VERSION "HNPBNNNYNNNNNNNNNNNNNNNNNNNNNNNNYNYYYYYYYY>4>%%%/4>'%**4YYY///"

NS_ :

BS_:

BU_: TPM TCM SCCM RF_HUB PTS ORC IC HaLF ETM ESM ESC EPS ECM Diagnost DTCM DASM CBC AFLS ADCM

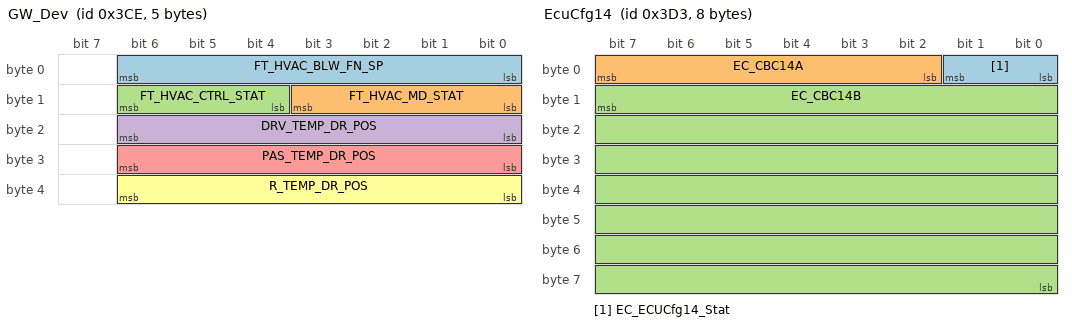
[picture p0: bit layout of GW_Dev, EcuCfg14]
BO_ 974 GW_Dev: 5 CBC
 SG_ FT_HVAC_BLW_FN_SP : 0|7@1+ (1,0) [0|100] "Bars"  ECM
 SG_ FT_HVAC_MD_STAT : 8|4@1+ (1,0) [0|0] ""  ECM
 SG_ FT_HVAC_CTRL_STAT : 12|3@1+ (1,0) [0|0] ""  ECM
 SG_ DRV_TEMP_DR_POS : 16|7@1+ (1,0) [0|100] "%"  ECM
 SG_ PAS_TEMP_DR_POS : 24|7@1+ (1,0) [0|100] "%"  ECM
 SG_ R_TEMP_DR_POS : 32|7@1+ (1,0) [0|100] "%"  ECM

BO_ 975 IC_SRT: 8 IC
 SG_ SRT_CTRL3 M : 0|4@1+ (1,0) [0|0] ""  CBC
 SG_ SRT_60mphTmC m0 : 8|8@1+ (0.1,0) [0|25.2] "sec"  CBC
 SG_ SRT_60mphTmB m1 : 8|8@1+ (0.1,0) [0|25.2] "sec"  CBC
 SG_ SRT_100mphTmL m10 : 8|8@1+ (0.1,0) [0|25.2] "sec"  CBC
 SG_ SRT_100mphTm_C m11 : 8|8@1+ (0.1,0) [0|25.2] "sec"  CBC
 SG_ SRT_100mphTm_B m12 : 8|8@1+ (0.1,0) [0|25.2] "sec"  CBC
 SG_ SRT_100mphTm_L m13 : 8|8@1+ (0.1,0) [0|25.2] "sec"  CBC
 SG_ SRT_60mphTmL m2 : 8|8@1+ (0.1,0) [0|25.2] "sec"  CBC
 SG_ SRT_60mphTm_C m3 : 8|8@1+ (0.1,0) [0|25.2] "sec"  CBC
 SG_ SRT_60mphTm_B m4 : 8|8@1+ (0.1,0) [0|25.2] "sec"  CBC
 SG_ SRT_60mphTm_L m5 : 8|8@1+ (0.1,0) [0|25.2] "sec"  CBC
 SG_ SRT_100mphTmC m8 : 8|8@1+ (0.1,0) [0|25.2] "sec"  CBC
 SG_ SRT_100mphTmB m9 : 8|8@1+ (0.1,0) [0|25.2] "sec"  CBC
 SG_ SRT_eighthTmC m0 : 16|8@1+ (0.1,0) [0|25.2] "sec"  CBC
 SG_ SRT_eighthTmB m1 : 16|8@1+ (0.1,0) [0|25.2] "sec"  CBC
 SG_ SRT_BrkTmL m10 : 16|8@1+ (0.1,0) [0|25.2] "sec"  CBC
 SG_ SRT_BrkTm_C m11 : 16|8@1+ (0.1,0) [0|25.2] "sec"  CBC
 SG_ SRT_BrkTm_B m12 : 16|8@1+ (0.1,0) [0|25.2] "sec"  CBC
 SG_ SRT_BrkTm_L m13 : 16|8@1+ (0.1,0) [0|25.2] "sec"  CBC
 SG_ SRT_eighthTmL m2 : 16|8@1+ (0.1,0) [0|25.2] "sec"  CBC
 SG_ SRT_eighthTm_C m3 : 16|8@1+ (0.1,0) [0|25.2] "sec"  CBC
 SG_ SRT_eighthTm_B m4 : 16|8@1+ (0.1,0) [0|25.2] "sec"  CBC
 SG_ SRT_eighthTm_L m5 : 16|8@1+ (0.1,0) [0|25.2] "sec"  CBC
 SG_ SRT_BrkTmC m8 : 16|8@1+ (0.1,0) [0|25.2] "sec"  CBC
 SG_ SRT_BrkTmB m9 : 16|8@1+ (0.1,0) [0|25.2] "sec"  CBC
 SG_ SRT_quarterTmC m0 : 24|8@1+ (0.1,0) [0|25.2] "sec"  CBC
 SG_ SRT_quarterTmB m1 : 24|8@1+ (0.1,0) [0|25.2] "sec"  CBC
 SG_ SRT_ReactTmL m10 : 24|8@1+ (0.01,-1.26) [-1.26|1.26] "sec"  CBC
 SG_ SRT_quarterTmL m2 : 24|8@1+ (0.1,0) [0|25.2] "sec"  CBC
 SG_ SRT_quarterTm_C m3 : 24|8@1+ (0.1,0) [0|25.2] "sec"  CBC
 SG_ SRT_quarterTm_B m4 : 24|8@1+ (0.1,0) [0|25.2] "sec"  CBC
 SG_ SRT_quarterTm_L m5 : 24|8@1+ (0.1,0) [0|25.2] "sec"  CBC
 SG_ SRT_ReactTmC m8 : 24|8@1+ (0.01,-1.26) [-1.26|1.26] "sec"  CBC
 SG_ SRT_ReactTmB m9 : 24|8@1+ (0.01,-1.26) [-1.26|1.26] "sec"  CBC
 SG_ SRT_EthSpdC_M m0 : 32|8@1+ (1,0) [0|254] "km/h"  CBC
 SG_ SRT_EthSpdB_M m1 : 32|8@1+ (1,0) [0|254] "km/h"  CBC
 SG_ SRT_EthSpdL_M m2 : 32|8@1+ (1,0) [0|254] "km/h"  CBC
 SG_ SRT_EthSpdC_US m3 : 32|8@1+ (1,0) [0|254] "mph"  CBC
 SG_ SRT_EthSpdB_US m4 : 32|8@1+ (1,0) [0|254] "mph"  CBC
 SG_ SRT_EthSpdL_US m5 : 32|8@1+ (1,0) [0|254] "mph"  CBC
 SG_ SRT_QrtSpdC_M m0 : 40|8@1+ (1,0) [0|254] "km/h"  CBC
 SG_ SRT_QrtSpdB_M m1 : 40|8@1+ (1,0) [0|254] "km/h"  CBC
 SG_ SRT_QrtSpdL_M m2 : 40|8@1+ (1,0) [0|254] "km/h"  CBC
 SG_ SRT_QrtSpdC_US m3 : 40|8@1+ (1,0) [0|254] "mph"  CBC
 SG_ SRT_QrtSpdB_US m4 : 40|8@1+ (1,0) [0|254] "mph"  CBC
 SG_ SRT_QrtSpdL_US m5 : 40|8@1+ (1,0) [0|254] "mph"  CBC
 SG_ SRT_BrkSpdC_M m0 : 48|8@1+ (1,0) [0|254] "km/h"  CBC
 SG_ SRT_BrkSpdB_M m1 : 48|8@1+ (1,0) [0|254] "km/h"  CBC
 SG_ SRT_BrkSpdL_M m2 : 48|8@1+ (1,0) [0|254] "km/h"  CBC
 SG_ SRT_BrkSpdC_US m3 : 48|8@1+ (1,0) [0|254] "mph"  CBC
 SG_ SRT_BrkSpdB_US m4 : 48|8@1+ (1,0) [0|254] "mph"  CBC
 SG_ SRT_BrkSpdL_US m5 : 48|8@1+ (1,0) [0|254] "mph"  CBC
 SG_ SRT_BrkDistC_M m0 : 56|8@1+ (1,0) [0|252] "m"  CBC
 SG_ SRT_BrkDistB_M m1 : 56|8@1+ (1,0) [0|252] "m"  CBC
 SG_ SRT_BrkDistL_M m2 : 56|8@1+ (1,0) [0|252] "m"  CBC
 SG_ SRT_BrkDistC_US m3 : 56|8@1+ (1,0) [0|252] "Yards"  CBC
 SG_ SRT_BrkDistB_US m4 : 56|8@1+ (1,0) [0|252] "Yards"  CBC
 SG_ SRT_BrkDistL_US m5 : 56|8@1+ (1,0) [0|252] "Yards"  CBC

BO_ 977 TCM_CFG: 4 TCM
 SG_ TransTyp : 0|8@1+ (1,0) [0|0] ""  DTCM,ESC,CBC,RF_HUB

BO_ 979 EcuCfg14: 8 CBC
 SG_ EC_ECUCfg14_Stat : 0|2@1+ (1,0) [0|0] ""  RF_HUB
 SG_ EC_CBC14A : 2|6@1+ (1,0) [0|0] ""  RF_HUB
 SG_ EC_CBC14B : 15|56@0+ (1,0) [0|0] ""  RF_HUB

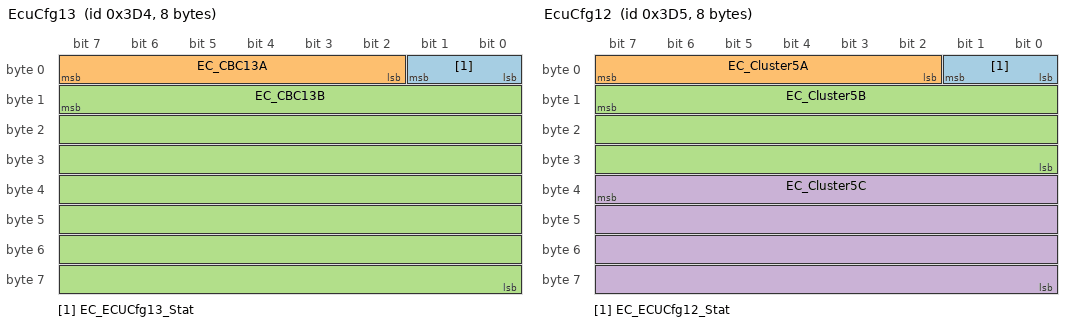
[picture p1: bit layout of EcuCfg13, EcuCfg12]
BO_ 980 EcuCfg13: 8 CBC
 SG_ EC_ECUCfg13_Stat : 0|2@1+ (1,0) [0|0] ""  RF_HUB
 SG_ EC_CBC13A : 2|6@1+ (1,0) [0|0] ""  RF_HUB
 SG_ EC_CBC13B : 15|56@0+ (1,0) [0|0] ""  RF_HUB

BO_ 981 EcuCfg12: 8 CBC
 SG_ EC_ECUCfg12_Stat : 0|2@1+ (1,0) [0|0] ""  IC,RF_HUB
 SG_ EC_Cluster5A : 2|6@1+ (1,0) [0|0] ""  IC,RF_HUB
 SG_ EC_Cluster5B : 15|24@0+ (1,0) [0|0] ""  IC,RF_HUB
 SG_ EC_Cluster5C : 39|32@0+ (1,0) [0|0] ""  IC,RF_HUB

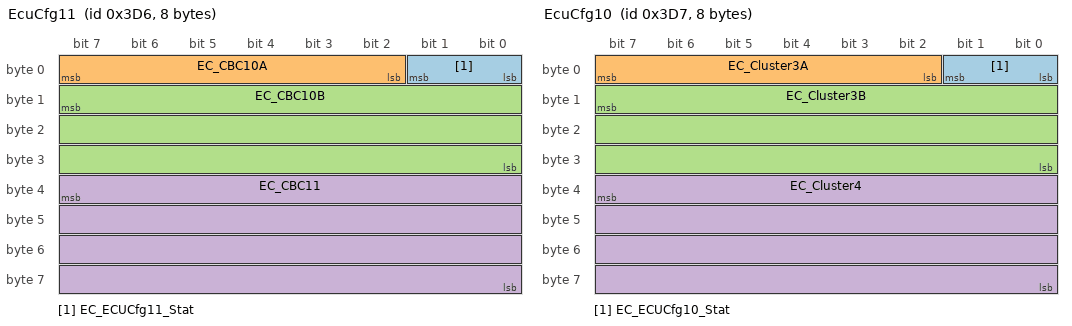
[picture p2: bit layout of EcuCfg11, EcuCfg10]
BO_ 982 EcuCfg11: 8 CBC
 SG_ EC_ECUCfg11_Stat : 0|2@1+ (1,0) [0|0] ""  RF_HUB
 SG_ EC_CBC10A : 2|6@1+ (1,0) [0|0] ""  RF_HUB
 SG_ EC_CBC10B : 15|24@0+ (1,0) [0|0] ""  RF_HUB
 SG_ EC_CBC11 : 39|32@0+ (1,0) [0|0] ""  RF_HUB

BO_ 983 EcuCfg10: 8 CBC
 SG_ EC_ECUCfg10_Stat : 0|2@1+ (1,0) [0|0] ""  IC,RF_HUB
 SG_ EC_Cluster3A : 2|6@1+ (1,0) [0|0] ""  IC,RF_HUB
 SG_ EC_Cluster3B : 15|24@0+ (1,0) [0|0] ""  IC,RF_HUB
 SG_ EC_Cluster4 : 39|32@0+ (1,0) [0|0] ""  IC,RF_HUB

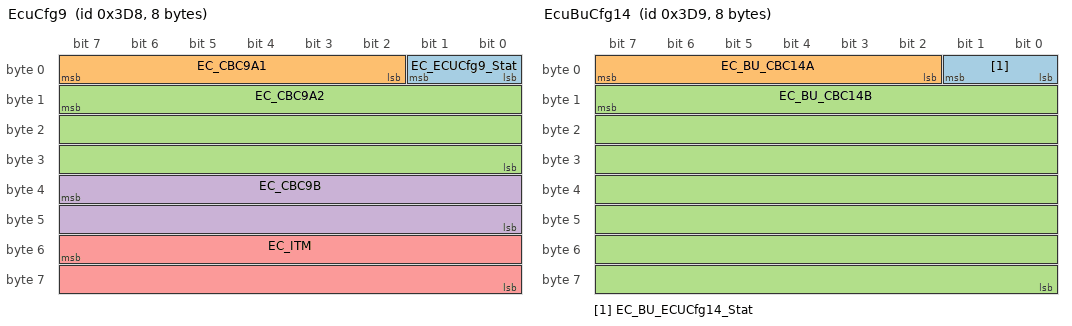
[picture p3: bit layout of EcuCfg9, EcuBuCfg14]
BO_ 984 EcuCfg9: 8 CBC
 SG_ EC_ECUCfg9_Stat : 0|2@1+ (1,0) [0|0] ""  RF_HUB
 SG_ EC_CBC9A1 : 2|6@1+ (1,0) [0|0] ""  RF_HUB
 SG_ EC_CBC9A2 : 15|24@0+ (1,0) [0|0] ""  RF_HUB
 SG_ EC_CBC9B : 39|16@0+ (1,0) [0|0] ""  RF_HUB
 SG_ EC_ITM : 55|16@0+ (1,0) [0|0] ""  RF_HUB

BO_ 985 EcuBuCfg14: 8 RF_HUB
 SG_ EC_BU_ECUCfg14_Stat : 0|2@1+ (1,0) [0|0] ""  CBC
 SG_ EC_BU_CBC14A : 2|6@1+ (1,0) [0|0] ""  CBC
 SG_ EC_BU_CBC14B : 15|56@0+ (1,0) [0|0] ""  CBC

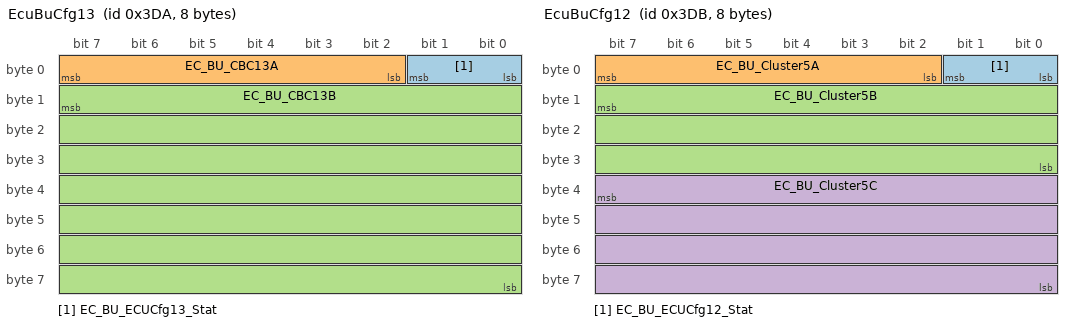
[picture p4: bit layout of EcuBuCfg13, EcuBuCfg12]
BO_ 986 EcuBuCfg13: 8 RF_HUB
 SG_ EC_BU_ECUCfg13_Stat : 0|2@1+ (1,0) [0|0] ""  CBC
 SG_ EC_BU_CBC13A : 2|6@1+ (1,0) [0|0] ""  CBC
 SG_ EC_BU_CBC13B : 15|56@0+ (1,0) [0|0] ""  CBC

BO_ 987 EcuBuCfg12: 8 RF_HUB
 SG_ EC_BU_ECUCfg12_Stat : 0|2@1+ (1,0) [0|0] ""  CBC
 SG_ EC_BU_Cluster5A : 2|6@1+ (1,0) [0|0] ""  CBC
 SG_ EC_BU_Cluster5B : 15|24@0+ (1,0) [0|0] ""  CBC
 SG_ EC_BU_Cluster5C : 39|32@0+ (1,0) [0|0] ""  CBC

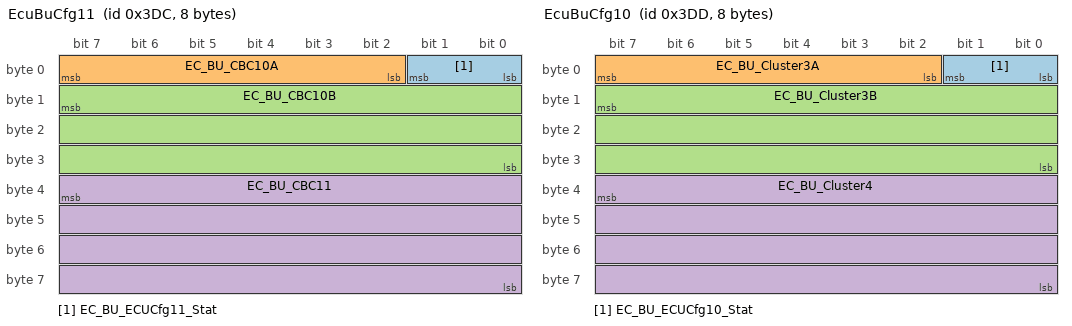
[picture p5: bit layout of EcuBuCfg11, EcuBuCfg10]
BO_ 988 EcuBuCfg11: 8 RF_HUB
 SG_ EC_BU_ECUCfg11_Stat : 0|2@1+ (1,0) [0|0] ""  CBC
 SG_ EC_BU_CBC10A : 2|6@1+ (1,0) [0|0] ""  CBC
 SG_ EC_BU_CBC10B : 15|24@0+ (1,0) [0|0] ""  CBC
 SG_ EC_BU_CBC11 : 39|32@0+ (1,0) [0|0] ""  CBC

BO_ 989 EcuBuCfg10: 8 RF_HUB
 SG_ EC_BU_ECUCfg10_Stat : 0|2@1+ (1,0) [0|0] ""  CBC
 SG_ EC_BU_Cluster3A : 2|6@1+ (1,0) [0|0] ""  CBC
 SG_ EC_BU_Cluster3B : 15|24@0+ (1,0) [0|0] ""  CBC
 SG_ EC_BU_Cluster4 : 39|32@0+ (1,0) [0|0] ""  CBC

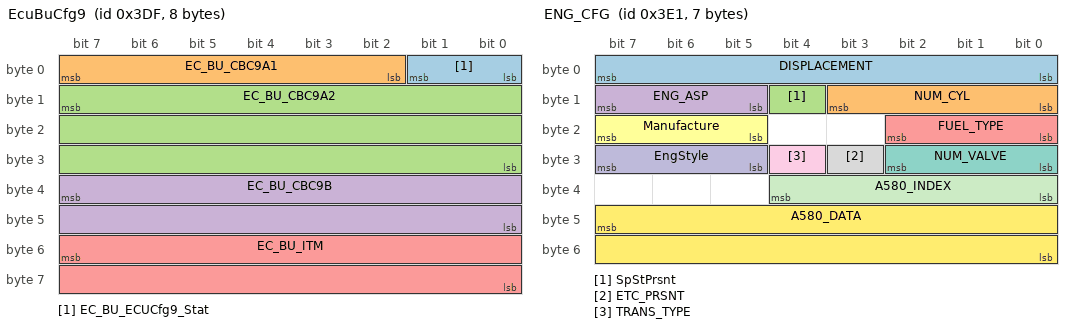
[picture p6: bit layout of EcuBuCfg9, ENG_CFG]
BO_ 991 EcuBuCfg9: 8 RF_HUB
 SG_ EC_BU_ECUCfg9_Stat : 0|2@1+ (1,0) [0|0] ""  CBC
 SG_ EC_BU_CBC9A1 : 2|6@1+ (1,0) [0|0] ""  CBC
 SG_ EC_BU_CBC9A2 : 15|24@0+ (1,0) [0|0] ""  CBC
 SG_ EC_BU_CBC9B : 39|16@0+ (1,0) [0|0] ""  CBC
 SG_ EC_BU_ITM : 55|16@0+ (1,0) [0|0] ""  CBC

BO_ 992 VIN: 8 ECM
 SG_ VIN_MSG : 0|2@1+ (1,0) [0|0] ""  HaLF,ORC,ADCM,DTCM,ESM,TCM,ECM,DASM,ESC,SCCM,EPS,AFLS,TPM,PTS,IC,CBC,RF_HUB
 SG_ VIN_DATA : 15|56@0+ (1,0) [0|0] ""  HaLF,ORC,ADCM,DTCM,ESM,TCM,ECM,DASM,ESC,SCCM,EPS,AFLS,TPM,PTS,IC,CBC,RF_HUB

BO_ 993 ENG_CFG: 7 ECM
 SG_ DISPLACEMENT : 0|8@1+ (0.1,0) [0|25] "liters"  ETM,DASM,ESC,EPS,IC,CBC
 SG_ NUM_CYL : 8|4@1+ (1,0) [0|14] "cylinders"  DASM,ESC
 SG_ SpStPrsnt : 12|1@1+ (1,0) [0|0] ""  EPS,IC,CBC
 SG_ ENG_ASP : 13|3@1+ (1,0) [0|0] ""  ETM,DASM,ESC
 SG_ FUEL_TYPE : 16|3@1+ (1,0) [0|0] ""  ORC,DASM,ESC,IC,CBC
 SG_ Manufacture : 21|3@1+ (1,0) [0|0] "" Vector__XXX
 SG_ NUM_VALVE : 24|3@1+ (1,0) [0|6] "valve-per-cylinder"  DASM
 SG_ ETC_PRSNT : 27|1@1+ (1,0) [0|0] ""  IC
 SG_ TRANS_TYPE : 28|1@1+ (1,0) [0|0] ""  EPS,ORC,DTCM,DASM,ESC,TPM,PTS,IC,CBC,RF_HUB
 SG_ EngStyle : 29|3@1+ (1,0) [0|0] ""  ESC,CBC
 SG_ A580_INDEX : 32|5@1+ (1,0) [0|0] "" Vector__XXX
 SG_ A580_DATA : 47|16@0+ (1,0) [0|0] "" Vector__XXX

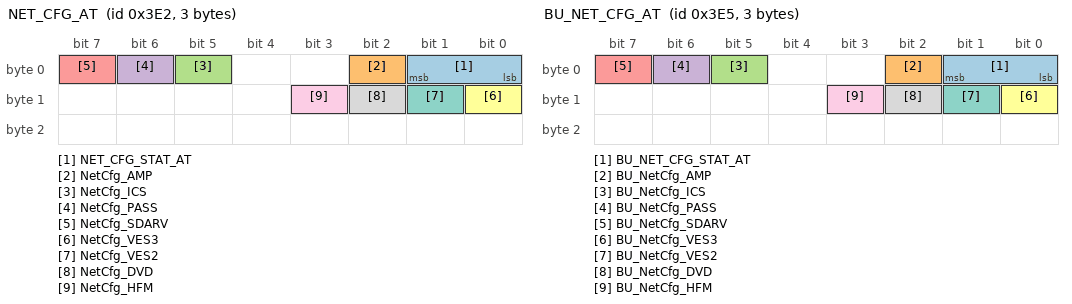
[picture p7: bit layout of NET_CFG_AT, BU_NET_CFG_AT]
BO_ 994 NET_CFG_AT: 3 CBC
 SG_ NET_CFG_STAT_AT : 0|2@1+ (1,0) [0|0] ""  RF_HUB
 SG_ NetCfg_AMP : 2|1@1+ (1,0) [0|0] ""  RF_HUB
 SG_ NetCfg_ICS : 5|1@1+ (1,0) [0|0] ""  RF_HUB
 SG_ NetCfg_PASS : 6|1@1+ (1,0) [0|0] ""  RF_HUB
 SG_ NetCfg_SDARV : 7|1@1+ (1,0) [0|0] ""  RF_HUB
 SG_ NetCfg_VES3 : 8|1@1+ (1,0) [0|0] ""  RF_HUB
 SG_ NetCfg_VES2 : 9|1@1+ (1,0) [0|0] ""  RF_HUB
 SG_ NetCfg_DVD : 10|1@1+ (1,0) [0|0] ""  RF_HUB
 SG_ NetCfg_HFM : 11|1@1+ (1,0) [0|0] ""  RF_HUB

BO_ 995 NET_CFG_INT: 8 CBC
 SG_ NET_CFG_STAT_INT : 0|2@1+ (1,0) [0|0] ""  IC,RF_HUB
 SG_ NetCfg_RBSS : 2|1@1+ (1,0) [0|0] ""  RF_HUB
 SG_ NetCfg_BSM : 3|1@1+ (1,0) [0|0] ""  IC,RF_HUB
 SG_ NetCfg_CBC_IN : 4|1@1+ (1,0) [0|0] ""  IC,RF_HUB
 SG_ NetCfg_CSWM : 5|1@1+ (1,0) [0|0] ""  IC,RF_HUB
 SG_ NetCfg_DCM_DR : 6|1@1+ (1,0) [0|0] ""  IC,RF_HUB
 SG_ NetCfg_DCM_PASS : 7|1@1+ (1,0) [0|0] ""  IC,RF_HUB
 SG_ NetCfg_DCM_RL : 8|1@1+ (1,0) [0|0] ""  IC,RF_HUB
 SG_ NetCfg_DCM_RR : 9|1@1+ (1,0) [0|0] ""  IC,RF_HUB
 SG_ NetCfg_HVAC : 10|1@1+ (1,0) [0|0] ""  IC,RF_HUB
 SG_ NetCfg_MSM : 11|1@1+ (1,0) [0|0] ""  IC,RF_HUB
 SG_ NetCfg_PLG : 12|1@1+ (1,0) [0|0] ""  IC,RF_HUB
 SG_ NetCfg_VTM : 13|1@1+ (1,0) [0|0] ""  RF_HUB
 SG_ NetCfg_PSD_LT : 14|1@1+ (1,0) [0|0] ""  IC,RF_HUB
 SG_ NetCfg_PSD_RT : 15|1@1+ (1,0) [0|0] ""  IC,RF_HUB
 SG_ NetCfg_FSM : 16|1@1+ (1,0) [0|0] ""  IC,RF_HUB
 SG_ NetCfg_PTCM : 17|1@1+ (1,0) [0|0] ""  IC,RF_HUB
 SG_ NetCfg_RBC : 18|1@1+ (1,0) [0|0] ""  IC,RF_HUB
 SG_ NetCfg_DTV : 19|1@1+ (1,0) [0|0] ""  RF_HUB
 SG_ NetCfg_TGW : 20|1@1+ (1,0) [0|0] ""  IC,RF_HUB
 SG_ NetCfg_CLOCK : 21|1@1+ (1,0) [0|0] ""  RF_HUB
 SG_ NetCfg_VSIM : 22|1@1+ (1,0) [0|0] ""  IC,RF_HUB
 SG_ NetCfg_ITM : 23|1@1+ (1,0) [0|0] ""  IC,RF_HUB
 SG_ NetCfg_AMP_I : 24|1@1+ (1,0) [0|0] ""  RF_HUB
 SG_ NetCfg_DVD_CDM : 25|1@1+ (1,0) [0|0] ""  RF_HUB
 SG_ NetCfg_HFM_CTM : 26|1@1+ (1,0) [0|0] ""  RF_HUB
 SG_ NetCfg_ICS_I : 27|1@1+ (1,0) [0|0] ""  RF_HUB
 SG_ NetCfg_VES2_I : 28|1@1+ (1,0) [0|0] ""  RF_HUB
 SG_ NetCfg_VES3_I : 29|1@1+ (1,0) [0|0] ""  RF_HUB
 SG_ NetCfg_CRSM : 30|1@1+ (1,0) [0|0] ""  RF_HUB
 SG_ NetCfg_HVAC_R : 31|1@1+ (1,0) [0|0] ""  RF_HUB

BO_ 996 NET_CFG_PT: 8 CBC
 SG_ NET_CFG_STAT_PT : 0|2@1+ (1,0) [0|0] ""  HaLF,ORC,ADCM,DTCM,ESM,TCM,ECM,DASM,ESC,SCCM,EPS,AFLS,TPM,PTS,IC,RF_HUB
 SG_ NetCfg_ACC : 2|1@1+ (1,0) [0|0] ""  IC,RF_HUB
 SG_ NetCfg_ADCM : 3|1@1+ (1,0) [0|0] ""  DASM,IC,RF_HUB
 SG_ NetCfg_AHLM : 4|1@1+ (1,0) [0|0] ""  IC,RF_HUB
 SG_ NetCfg_VSIM_C : 5|1@1+ (1,0) [0|0] ""  ECM,IC,RF_HUB
 SG_ NetCfg_ASCM : 6|1@1+ (1,0) [0|0] ""  HaLF,ESC,SCCM,AFLS,TPM,PTS,IC,RF_HUB
 SG_ NetCfg_CBC_PT : 7|1@1+ (1,0) [0|0] ""  ORC,TCM,ECM,DASM,ESC,SCCM,EPS,TPM,PTS,IC,RF_HUB
 SG_ NetCfg_DTCM : 8|1@1+ (1,0) [0|0] ""  TCM,ECM,DASM,ESC,IC,RF_HUB
 SG_ NetCfg_ECM : 9|1@1+ (1,0) [0|0] ""  ORC,TCM,ECM,DASM,ESC,SCCM,EPS,TPM,PTS,IC,RF_HUB
 SG_ NetCfg_EPS : 10|1@1+ (1,0) [0|0] ""  ECM,IC,RF_HUB
 SG_ NetCfg_ESM : 11|1@1+ (1,0) [0|0] ""  ECM,IC,RF_HUB
 SG_ NetCfg_ESC : 12|1@1+ (1,0) [0|0] ""  ORC,TCM,ECM,DASM,EPS,TPM,PTS,IC,RF_HUB
 SG_ NetCfg_EPB : 13|1@1+ (1,0) [0|0] ""  ECM,DASM,RF_HUB
 SG_ NetCfg_RF_HUB : 14|1@1+ (1,0) [0|0] ""  ECM,DASM,ESC,SCCM,TPM,IC,RF_HUB
 SG_ NetCfg_IC : 15|1@1+ (1,0) [0|0] ""  TCM,ECM,DASM,ESC,SCCM,EPS,TPM,PTS,IC,RF_HUB
 SG_ NetCfg_DASM : 16|1@1+ (1,0) [0|0] ""  TCM,ECM,DASM,ESC,SCCM,IC,RF_HUB
 SG_ NetCfg_FDCM : 17|1@1+ (1,0) [0|0] ""  RF_HUB
 SG_ NetCfg_EPPM : 18|1@1+ (1,0) [0|0] ""  ORC,RF_HUB
 SG_ NetCfg_ORC : 19|1@1+ (1,0) [0|0] ""  ECM,DASM,ESC,IC,RF_HUB
 SG_ NetCfg_PTS : 20|1@1+ (1,0) [0|0] ""  EPS,IC,RF_HUB
 SG_ NetCfg_RBT_DR : 21|1@1+ (1,0) [0|0] ""  DASM,ESC,IC,RF_HUB
 SG_ NetCfg_RBT_PASS : 22|1@1+ (1,0) [0|0] ""  DASM,ESC,IC,RF_HUB
 SG_ NetCfg_SCCM : 23|1@1+ (1,0) [0|0] ""  ORC,ECM,DASM,ESC,SCCM,EPS,TPM,PTS,IC,RF_HUB
 SG_ NetCfg_ELSD : 24|1@1+ (1,0) [0|0] ""  ESC,IC,RF_HUB
 SG_ NetCfg_TCM : 25|1@1+ (1,0) [0|0] ""  EPS,ORC,ESM,ECM,DASM,ESC,PTS,IC,RF_HUB
 SG_ NetCfg_TPM : 26|1@1+ (1,0) [0|0] ""  ORC,SCCM,TPM,IC,RF_HUB
 SG_ NetCfg_PASS_PT : 27|1@1+ (1,0) [0|0] ""  IC,RF_HUB
 SG_ NetCfg_AFLS : 28|1@1+ (1,0) [0|0] ""  IC,RF_HUB
 SG_ NetCfg_ITBM : 29|1@1+ (1,0) [0|0] ""  PTS,IC,RF_HUB
 SG_ NetCfg_OCM : 30|1@1+ (1,0) [0|0] ""  RF_HUB
 SG_ NetCfg_HaLF : 31|1@1+ (1,0) [0|0] ""  HaLF,DASM,SCCM,EPS,RF_HUB
 SG_ NetCfg_ANC : 39|1@1+ (1,0) [0|0] ""  RF_HUB

BO_ 997 BU_NET_CFG_AT: 3 RF_HUB
 SG_ BU_NET_CFG_STAT_AT : 0|2@1+ (1,0) [0|0] ""  CBC
 SG_ BU_NetCfg_AMP : 2|1@1+ (1,0) [0|0] ""  CBC
 SG_ BU_NetCfg_ICS : 5|1@1+ (1,0) [0|0] ""  CBC
 SG_ BU_NetCfg_PASS : 6|1@1+ (1,0) [0|0] ""  CBC
 SG_ BU_NetCfg_SDARV : 7|1@1+ (1,0) [0|0] ""  CBC
 SG_ BU_NetCfg_VES3 : 8|1@1+ (1,0) [0|0] ""  CBC
 SG_ BU_NetCfg_VES2 : 9|1@1+ (1,0) [0|0] ""  CBC
 SG_ BU_NetCfg_DVD : 10|1@1+ (1,0) [0|0] ""  CBC
 SG_ BU_NetCfg_HFM : 11|1@1+ (1,0) [0|0] ""  CBC

BO_ 998 BU_NET_CFG_INT: 8 RF_HUB
 SG_ BU_NET_CFG_STAT_INT : 0|2@1+ (1,0) [0|0] ""  CBC
 SG_ BU_NetCfg_RBSS : 2|1@1+ (1,0) [0|0] ""  CBC
 SG_ BU_NetCfg_BSM : 3|1@1+ (1,0) [0|0] ""  CBC
 SG_ BU_NetCfg_CBC_IN : 4|1@1+ (1,0) [0|0] ""  CBC
 SG_ BU_NetCfg_CSWM : 5|1@1+ (1,0) [0|0] ""  CBC
 SG_ BU_NetCfg_DCM_DR : 6|1@1+ (1,0) [0|0] ""  CBC
 SG_ BU_NetCfg_DCM_PASS : 7|1@1+ (1,0) [0|0] ""  CBC
 SG_ BU_NetCfg_DCM_RL : 8|1@1+ (1,0) [0|0] ""  CBC
 SG_ BU_NetCfg_DCM_RR : 9|1@1+ (1,0) [0|0] ""  CBC
 SG_ BU_NetCfg_HVAC : 10|1@1+ (1,0) [0|0] ""  CBC
 SG_ BU_NetCfg_MSM : 11|1@1+ (1,0) [0|0] ""  CBC
 SG_ BU_NetCfg_PLG : 12|1@1+ (1,0) [0|0] ""  CBC
 SG_ BU_NetCfg_VTM : 13|1@1+ (1,0) [0|0] ""  CBC
 SG_ BU_NetCfg_PSD_LT : 14|1@1+ (1,0) [0|0] ""  CBC
 SG_ BU_NetCfg_PSD_RT : 15|1@1+ (1,0) [0|0] ""  CBC
 SG_ BU_NetCfg_FSM : 16|1@1+ (1,0) [0|0] ""  CBC
 SG_ BU_NetCfg_PTCM : 17|1@1+ (1,0) [0|0] ""  CBC
 SG_ BU_NetCfg_RBC : 18|1@1+ (1,0) [0|0] ""  CBC
 SG_ BU_NetCfg_DTV : 19|1@1+ (1,0) [0|0] ""  CBC
 SG_ BU_NetCfg_TGW : 20|1@1+ (1,0) [0|0] ""  CBC
 SG_ BU_NetCfg_CLOCK : 21|1@1+ (1,0) [0|0] ""  CBC
 SG_ BU_NetCfg_VSIM : 22|1@1+ (1,0) [0|0] ""  CBC
 SG_ BU_NetCfg_ITM : 23|1@1+ (1,0) [0|0] ""  CBC
 SG_ BU_NetCfg_AMP_I : 24|1@1+ (1,0) [0|0] ""  CBC
 SG_ BU_NetCfg_DVD_CDM : 25|1@1+ (1,0) [0|0] ""  CBC
 SG_ BU_NetCfg_HFM_CTM : 26|1@1+ (1,0) [0|0] ""  CBC
 SG_ BU_NetCfg_ICS_I : 27|1@1+ (1,0) [0|0] ""  CBC
 SG_ BU_NetCfg_VES2_I : 28|1@1+ (1,0) [0|0] ""  CBC
 SG_ BU_NetCfg_VES3_I : 29|1@1+ (1,0) [0|0] ""  CBC
 SG_ BU_NetCfg_CRSM : 30|1@1+ (1,0) [0|0] ""  CBC
 SG_ BU_NetCfg_HVAC_R : 31|1@1+ (1,0) [0|0] ""  CBC

CM_ SG_ 974 FT_HVAC_BLW_FN_SP "Front HVAC blower fan speed status in 'bars'";
CM_ SG_ 974 FT_HVAC_MD_STAT "Front HVAC control mode status";
CM_ SG_ 974 FT_HVAC_CTRL_STAT "Front HVAC control status";
CM_ SG_ 974 DRV_TEMP_DR_POS "Driver temperature door postion";
CM_ SG_ 974 PAS_TEMP_DR_POS "Passenger temperature door postion";
CM_ SG_ 974 R_TEMP_DR_POS "Rear temperature door postion";
CM_ SG_ 975 SRT_CTRL3 "Control signal SRT functions";
CM_ SG_ 975 SRT_60mphTmC "SRT 0 to 60 timer - current";
CM_ SG_ 975 SRT_60mphTmB "SRT 0 to 60 timer - best";
CM_ SG_ 975 SRT_100mphTmL "SRT 0 to 100  timer - last";
CM_ SG_ 975 SRT_100mphTm_C "SRT 0 to 100  timer - current";
CM_ SG_ 975 SRT_100mphTm_B "SRT 0 to 100  timer - best";
CM_ SG_ 975 SRT_100mphTm_L "SRT 0 to 100 to 0 timer - last";
CM_ SG_ 975 SRT_60mphTmL "SRT 0 to 60 timer - last";
CM_ SG_ 975 SRT_60mphTm_C "SRT 0 to 60 timer - current";
CM_ SG_ 975 SRT_60mphTm_B "SRT 0 to 60 timer - best";
CM_ SG_ 975 SRT_60mphTm_L "SRT 0 to 60 timer - last";
CM_ SG_ 975 SRT_100mphTmC "SRT 0 to 100  timer - current";
CM_ SG_ 975 SRT_100mphTmB "SRT 0 to 100  timer - best";
CM_ SG_ 975 SRT_eighthTmC "SRT eighth mile timer - current";
CM_ SG_ 975 SRT_eighthTmB "SRT eighth mile timer - best";
CM_ SG_ 975 SRT_BrkTmL "SRT braking timer - last";
CM_ SG_ 975 SRT_BrkTm_C "SRT braking timer - current";
CM_ SG_ 975 SRT_BrkTm_B "SRT braking timer - best";
CM_ SG_ 975 SRT_BrkTm_L "SRT braking timer - last";
CM_ SG_ 975 SRT_eighthTmL "SRT eighth mile timer - last";
CM_ SG_ 975 SRT_eighthTm_C "SRT eighth mile timer - current";
CM_ SG_ 975 SRT_eighthTm_B "SRT eighth mile timer - best";
CM_ SG_ 975 SRT_eighthTm_L "SRT eighth mile timer - last";
CM_ SG_ 975 SRT_BrkTmC "SRT braking timer - current";
CM_ SG_ 975 SRT_BrkTmB "SRT braking timer - best";
CM_ SG_ 975 SRT_quarterTmC "SRT quarter mile timer - current";
CM_ SG_ 975 SRT_quarterTmB "SRT quarter mile timer - best";
CM_ SG_ 975 SRT_ReactTmL "SRT reaction time - last";
CM_ SG_ 975 SRT_quarterTmL "SRT quarter mile timer - last";
CM_ SG_ 975 SRT_quarterTm_C "SRT quarter mile timer - current";
CM_ SG_ 975 SRT_quarterTm_B "SRT quarter mile timer - best";
CM_ SG_ 975 SRT_quarterTm_L "SRT quarter mile timer - last";
CM_ SG_ 975 SRT_ReactTmC "SRT reaction time - current";
CM_ SG_ 975 SRT_ReactTmB "SRT reaction time - best";
CM_ SG_ 975 SRT_EthSpdC_M "SRT eighth mile speed - current in kmph";
CM_ SG_ 975 SRT_EthSpdB_M "SRT eighth mile speed - best in kmph";
CM_ SG_ 975 SRT_EthSpdL_M "SRT eighth mile speed - last in kmph";
CM_ SG_ 975 SRT_EthSpdC_US "SRT eighth mile speed - current in mph";
CM_ SG_ 975 SRT_EthSpdB_US "SRT eighth mile speed - best in mph";
CM_ SG_ 975 SRT_EthSpdL_US "SRT eighth mile speed - last in mph";
CM_ SG_ 975 SRT_QrtSpdC_M "SRT quarter mile speed - current in kmph";
CM_ SG_ 975 SRT_QrtSpdB_M "SRT quarter mile speed - best in kmph";
CM_ SG_ 975 SRT_QrtSpdL_M "SRT quarter mile speed - last in kmph";
CM_ SG_ 975 SRT_QrtSpdC_US "SRT quarter mile speed - current in mph";
CM_ SG_ 975 SRT_QrtSpdB_US "SRT quarter mile speed - best in mph";
CM_ SG_ 975 SRT_QrtSpdL_US "SRT quarter mile speed - last in mph";
CM_ SG_ 975 SRT_BrkSpdC_M "SRT braking speed - current in kmph";
CM_ SG_ 975 SRT_BrkSpdB_M "SRT braking speed - best in kmph";
CM_ SG_ 975 SRT_BrkSpdL_M "SRT braking speed - last in kmph";
CM_ SG_ 975 SRT_BrkSpdC_US "SRT braking speed - current in mph";
CM_ SG_ 975 SRT_BrkSpdB_US "SRT braking speed - best in mph";
CM_ SG_ 975 SRT_BrkSpdL_US "SRT braking speed - last in mph";
CM_ SG_ 975 SRT_BrkDistC_M "SRT braking distance - current in meters";
CM_ SG_ 975 SRT_BrkDistB_M "SRT braking distance - best in meters";
CM_ SG_ 975 SRT_BrkDistL_M "SRT braking distance - last in meters";
CM_ SG_ 975 SRT_BrkDistC_US "SRT braking distance - current in yards";
CM_ SG_ 975 SRT_BrkDistB_US "SRT braking distance - best in yards";
CM_ SG_ 975 SRT_BrkDistL_US "SRT braking distance - last in yards";
CM_ SG_ 977 TransTyp "Transmission type";
CM_ SG_ 979 EC_ECUCfg14_Stat "ECU Configuration messages status 14";
CM_ SG_ 979 EC_CBC14A "CBC ecu configuration 14A";
CM_ SG_ 979 EC_CBC14B "CBC ecu configuration 14B";
CM_ SG_ 980 EC_ECUCfg13_Stat "ECU Configuration messages status 13";
CM_ SG_ 980 EC_CBC13A "CBC ecu configuration 13A";
CM_ SG_ 980 EC_CBC13B "CBC ecu configuration 13B";
CM_ SG_ 981 EC_ECUCfg12_Stat "ECU Configuration messages status 12";
CM_ SG_ 981 EC_Cluster5A "Instrument cluster ecu configuration 5A";
CM_ SG_ 981 EC_Cluster5B "Instrument cluster ecu configuration 5B";
CM_ SG_ 981 EC_Cluster5C "Instrument cluster ecu configuration 5C";
CM_ SG_ 982 EC_ECUCfg11_Stat "ECU Configuration messages status 11";
CM_ SG_ 982 EC_CBC10A "CBC ecu configuration 10A";
CM_ SG_ 982 EC_CBC10B "CBC ecu configuration 10B";
CM_ SG_ 982 EC_CBC11 "CBC ecu configuration 11";
CM_ SG_ 983 EC_ECUCfg10_Stat "ECU Configuration messages status 10";
CM_ SG_ 983 EC_Cluster3A "Instrument cluster ecu configuration 3A";
CM_ SG_ 983 EC_Cluster3B "Instrument cluster ecu configuration 3B";
CM_ SG_ 983 EC_Cluster4 "Instrument cluster ecu configuration 4";
CM_ SG_ 984 EC_ECUCfg9_Stat "ECU Configuration messages status 9";
CM_ SG_ 984 EC_CBC9A1 "CBC configuration 9A1";
CM_ SG_ 984 EC_CBC9A2 "CBC configuration 9A2";
CM_ SG_ 984 EC_CBC9B "CBC configuration 9B";
CM_ SG_ 984 EC_ITM "ITM ecu configuration";
CM_ SG_ 985 EC_BU_ECUCfg14_Stat "Backup for ECU Configuration messages status 14";
CM_ SG_ 985 EC_BU_CBC14A "Backup for CBC ecu configuration 14A";
CM_ SG_ 985 EC_BU_CBC14B "Backup for CBC ecu configuration 14B";
CM_ SG_ 986 EC_BU_ECUCfg13_Stat "Backup for ECU Configuration messages status 13";
CM_ SG_ 986 EC_BU_CBC13A "Backup for CBC ecu configuration 13A";
CM_ SG_ 986 EC_BU_CBC13B "Backup for CBC ecu configuration 13B";
CM_ SG_ 987 EC_BU_ECUCfg12_Stat "Backup for ECU Configuration messages status 12";
CM_ SG_ 987 EC_BU_Cluster5A "Backup for Instrument cluster ecu configuration 5A";
CM_ SG_ 987 EC_BU_Cluster5B "Backup for Instrument cluster ecu configuration 5B";
CM_ SG_ 987 EC_BU_Cluster5C "Backup for Instrument cluster ecu configuration 5C";
CM_ SG_ 988 EC_BU_ECUCfg11_Stat "Backup for ECU Configuration messages status 11";
CM_ SG_ 988 EC_BU_CBC10A "Backup for CBC ecu configuration 10A";
CM_ SG_ 988 EC_BU_CBC10B "Backup for CBC ecu configuration 10B";
CM_ SG_ 988 EC_BU_CBC11 "Backup for CBC ecu configuration 11";
CM_ SG_ 989 EC_BU_ECUCfg10_Stat "Backup for ECU Configuration messages status 10";
CM_ SG_ 989 EC_BU_Cluster3A "Backup for Instrument cluster ecu configuration 3A";
CM_ SG_ 989 EC_BU_Cluster3B "Backup for Instrument cluster ecu configuration 3B";
CM_ SG_ 989 EC_BU_Cluster4 "Backup for Instrument cluster ecu configuration 4";
CM_ SG_ 991 EC_BU_ECUCfg9_Stat "Backup for ECU Configuration messages status 9";
CM_ SG_ 991 EC_BU_CBC9A1 "Backup for CBC configuration 9A1";
CM_ SG_ 991 EC_BU_CBC9A2 "Backup for CBC configuration 9A2";
CM_ SG_ 991 EC_BU_CBC9B "Backup for CBC configuration 9B";
CM_ SG_ 991 EC_BU_ITM "Backup for ITM ecu configuration";
CM_ SG_ 992 VIN_MSG "VIN Message Information";
CM_ SG_ 992 VIN_DATA "VIN Digits (8 bit ascii encoded) - see Signal Description Doc for details";
CM_ SG_ 993 DISPLACEMENT "Engine displacement";
CM_ SG_ 993 NUM_CYL "Number of engine cylinders";
CM_ SG_ 993 SpStPrsnt "Stop start feature present";
CM_ SG_ 993 ENG_ASP "Engine aspiration method";
CM_ SG_ 993 FUEL_TYPE "Fuel type";
CM_ SG_ 993 Manufacture "Engine manufacture";
CM_ SG_ 993 NUM_VALVE "Number of valves per cylinder";
CM_ SG_ 993 ETC_PRSNT "Electronic throttle control";
CM_ SG_ 993 TRANS_TYPE "Transmission type; [0] = manual, [1] = automatic";
CM_ SG_ 993 EngStyle "Engine output version";
CM_ SG_ 993 A580_INDEX "A580 data index";
CM_ SG_ 993 A580_DATA "A580 engine stored data and CRC";
CM_ SG_ 994 NET_CFG_STAT_AT "Network configuration status";
CM_ SG_ 994 NetCfg_AMP "Amplifier Module (1=present)";
CM_ SG_ 994 NetCfg_ICS "Integrated Center Stack Module (1=present)";
CM_ SG_ 994 NetCfg_PASS "Personal Assistant Safety System Module (1=present)";
CM_ SG_ 994 NetCfg_SDARV "Satellite Digital Video Module (1=present)";
CM_ SG_ 994 NetCfg_VES3 "Video Entertainment System Screen 1 Module (1=present)";
CM_ SG_ 994 NetCfg_VES2 "Video Entertainment System Screen 2 Module (1=present)";
CM_ SG_ 994 NetCfg_DVD "In-dash DVD player Module (1=present)";
CM_ SG_ 994 NetCfg_HFM "Hands Free Module (1=present)";
CM_ SG_ 995 NET_CFG_STAT_INT "Network configuration status";
CM_ SG_ 995 NetCfg_RBSS "Right Blind-Spot Module (1=present)";
CM_ SG_ 995 NetCfg_BSM "Blind-Spot Module (1=present)";
CM_ SG_ 995 NetCfg_CBC_IN "Common Body Controller Int Bus (1=present)";
CM_ SG_ 995 NetCfg_CSWM "Comfot Seats and Wheel Module (1=present)";
CM_ SG_ 995 NetCfg_DCM_DR "Door Control Module Driver (1=present)";
CM_ SG_ 995 NetCfg_DCM_PASS "Door Control Module Passenger (1=present)";
CM_ SG_ 995 NetCfg_DCM_RL "Door Control Module Rear Left (1=present)";
CM_ SG_ 995 NetCfg_DCM_RR "Door Control Module Rear Right (1=present)";
CM_ SG_ 995 NetCfg_HVAC "Heating Ventilation Air Conditioning (1=present)";
CM_ SG_ 995 NetCfg_MSM "Memory Seat Module (1=present)";
CM_ SG_ 995 NetCfg_PLG "Power Liftgate Module (1=present)";
CM_ SG_ 995 NetCfg_VTM "Vehicle theft / tax module (1=present)";
CM_ SG_ 995 NetCfg_PSD_LT "Power Sliding Door Left Module (1=present)";
CM_ SG_ 995 NetCfg_PSD_RT "Power Sliding Door Right Module (1=present)";
CM_ SG_ 995 NetCfg_FSM "Folding Seat Module (1=present)";
CM_ SG_ 995 NetCfg_PTCM "Power Top Control Module (1=present)";
CM_ SG_ 995 NetCfg_RBC "Rear Body Controller Module (1=present)";
CM_ SG_ 995 NetCfg_DTV "Digital TV Module (1=present)";
CM_ SG_ 995 NetCfg_TGW "Telematics gateway (1=present)";
CM_ SG_ 995 NetCfg_CLOCK "CAN I Clock Module (1=present)";
CM_ SG_ 995 NetCfg_VSIM "Vehicle System Interface Module (1=present)";
CM_ SG_ 995 NetCfg_ITM "Intrusion module (1=present)";
CM_ SG_ 995 NetCfg_AMP_I "CAN I Amplifier Module (1=present)";
CM_ SG_ 995 NetCfg_DVD_CDM "CAN I in-dash disc player module (1=present)";
CM_ SG_ 995 NetCfg_HFM_CTM "Convergence Telematics Module (1=present)";
CM_ SG_ 995 NetCfg_ICS_I "CAN I Integrated Center Stack Module (1=present)";
CM_ SG_ 995 NetCfg_VES2_I "CAN I Video Ent. System screen 2 Module (1=present)";
CM_ SG_ 995 NetCfg_VES3_I "CAN I Video Ent. System screen 1 Module (1=present)";
CM_ SG_ 995 NetCfg_CRSM "CAN I Comfort Rear Seat Module (1=present)";
CM_ SG_ 995 NetCfg_HVAC_R "CAN I Rear Heating Ventilation Air Conditioning (1=present)";
CM_ SG_ 996 NET_CFG_STAT_PT "Network configuration status";
CM_ SG_ 996 NetCfg_ACC "Active Cruise Control (1=present)";
CM_ SG_ 996 NetCfg_ADCM "Active Damping Control Module (1=present)";
CM_ SG_ 996 NetCfg_AHLM "Automatic Headlamp Leveling Module (1=present)";
CM_ SG_ 996 NetCfg_VSIM_C "Vehicle System Interface Module (1=present)";
CM_ SG_ 996 NetCfg_ASCM "Air Suspension Control Module (1=present)";
CM_ SG_ 996 NetCfg_CBC_PT "Common Body Controller PT Bus (1=present)";
CM_ SG_ 996 NetCfg_DTCM "Drivetrain Control Module (1=present)";
CM_ SG_ 996 NetCfg_ECM "Engine Control Module (1=present)";
CM_ SG_ 996 NetCfg_EPS "Electric Power Steering (1=present)";
CM_ SG_ 996 NetCfg_ESM "Electronic Shift Module (1=present)";
CM_ SG_ 996 NetCfg_ESC "Electronic Stability Module / Anti-Lock Brake (1=present)";
CM_ SG_ 996 NetCfg_EPB "Electric Park Brake Module (1=present)";
CM_ SG_ 996 NetCfg_RF_HUB "RF Hub Node (1=present)";
CM_ SG_ 996 NetCfg_IC "Instrument Cluster (1=present)";
CM_ SG_ 996 NetCfg_DASM "Driver Assistance System Module (1=present)";
CM_ SG_ 996 NetCfg_FDCM "Final Drive Control Module (1=present)";
CM_ SG_ 996 NetCfg_EPPM "Elect. Pedestrian protection module (1=present)";
CM_ SG_ 996 NetCfg_ORC "Occupant Restraint Controller (1=present)";
CM_ SG_ 996 NetCfg_PTS "Parktronics System (1=present)";
CM_ SG_ 996 NetCfg_RBT_DR "Belt Pre-Tensioner Driver (1=present)";
CM_ SG_ 996 NetCfg_RBT_PASS "Belt Pre-Tensioner Passenger (1=present)";
CM_ SG_ 996 NetCfg_SCCM "Steering Column Control Module (1=present)";
CM_ SG_ 996 NetCfg_ELSD "Electric Limited Slip Differential (1=present)";
CM_ SG_ 996 NetCfg_TCM "Automatic Transmission Controller (1=present)";
CM_ SG_ 996 NetCfg_TPM "Tire Pressure Monitor (1=present)";
CM_ SG_ 996 NetCfg_PASS_PT "Personal Assistant Safety System Module PT Bus (1=present)";
CM_ SG_ 996 NetCfg_AFLS "Advanced Front Lighting System (1=present)";
CM_ SG_ 996 NetCfg_ITBM "Integrated Trailer Brake Module (1=present)";
CM_ SG_ 996 NetCfg_OCM "Occupant Classification Module (1=present)";
CM_ SG_ 996 NetCfg_HaLF "Haptic Lane Feedback module (1=present)";
CM_ SG_ 996 NetCfg_ANC "Active Noise Cancellation (1=present)";
CM_ SG_ 997 BU_NET_CFG_STAT_AT "Backup for network configuration status";
CM_ SG_ 997 BU_NetCfg_AMP "Backup for Amplifier Module (1=present)";
CM_ SG_ 997 BU_NetCfg_ICS "Backup for Integrated Center Stack Module (1=present)";
CM_ SG_ 997 BU_NetCfg_PASS "Backup for Personal Assistant Safety System Module (1=present)";
CM_ SG_ 997 BU_NetCfg_SDARV "Backup for Satellite Digital Video Module (1=present)";
CM_ SG_ 997 BU_NetCfg_VES3 "Backup for Video Entertainment System Screen 1 Module (1=present)";
CM_ SG_ 997 BU_NetCfg_VES2 "Backup for Video Entertainment System Screen 2 Module (1=present)";
CM_ SG_ 997 BU_NetCfg_DVD "Backup for In-dash DVD player Module (1=present)";
CM_ SG_ 997 BU_NetCfg_HFM "Backup for Hands Free  Module (1=present)";
CM_ SG_ 998 BU_NET_CFG_STAT_INT "Backup for network configuration status";
CM_ SG_ 998 BU_NetCfg_RBSS "Backup for Right Blind-Spot Module (1=present)";
CM_ SG_ 998 BU_NetCfg_BSM "Backup for Blind-Spot Module (1=present)";
CM_ SG_ 998 BU_NetCfg_CBC_IN "Backup for Common Body Controller Int Bus (1=present)";
CM_ SG_ 998 BU_NetCfg_CSWM "Backup for Comfot Seats and Wheel Module (1=present)";
CM_ SG_ 998 BU_NetCfg_DCM_DR "Backup for Door Control Module Driver (1=present)";
CM_ SG_ 998 BU_NetCfg_DCM_PASS "Backup for Door Control Module Passenger (1=present)";
CM_ SG_ 998 BU_NetCfg_DCM_RL "Backup for Door Control Module Rear Left (1=present)";
CM_ SG_ 998 BU_NetCfg_DCM_RR "Backup for Door Control Module Rear Right (1=present)";
CM_ SG_ 998 BU_NetCfg_HVAC "Backup for Heating Ventilation Air Conditioning (1=present)";
CM_ SG_ 998 BU_NetCfg_MSM "Backup for Memory Seat Module (1=present)";
CM_ SG_ 998 BU_NetCfg_PLG "Backup for Power Liftgate Module (1=present)";
CM_ SG_ 998 BU_NetCfg_VTM "Backup for vehicle theft / tax module (1=present)";
CM_ SG_ 998 BU_NetCfg_PSD_LT "Backup for Power Sliding Door Left Module (1=present)";
CM_ SG_ 998 BU_NetCfg_PSD_RT "Backup for Power Sliding Door Right Module (1=present)";
CM_ SG_ 998 BU_NetCfg_FSM "Backup for Folding Seat Module (1=present)";
CM_ SG_ 998 BU_NetCfg_PTCM "Backup for Power Top Control Module (1=present)";
CM_ SG_ 998 BU_NetCfg_RBC "Backup for Rear Body Controller Module (1=present)";
CM_ SG_ 998 BU_NetCfg_DTV "Backup for Digital TV Module (1=present)";
CM_ SG_ 998 BU_NetCfg_TGW "Backup for Telematics gateway (1=present)";
CM_ SG_ 998 BU_NetCfg_CLOCK "Backup for CAN I Clock Module (1=present)";
CM_ SG_ 998 BU_NetCfg_VSIM "Backup for Vehicle System Interface Module (1=present)";
CM_ SG_ 998 BU_NetCfg_ITM "Backup for Intrusion module (1=present)";
CM_ SG_ 998 BU_NetCfg_AMP_I "Backup for CAN I Amplifier Module (1=present)";
CM_ SG_ 998 BU_NetCfg_DVD_CDM "Backup for CAN I in-dash disc player module (1=present)";
CM_ SG_ 998 BU_NetCfg_HFM_CTM "Backup for Convergence Telematics Module (1=present)";
CM_ SG_ 998 BU_NetCfg_ICS_I "Backup for CAN I Integrated Center Stack Module (1=present)";
CM_ SG_ 998 BU_NetCfg_VES2_I "Backup for CAN I Video Ent. System screen 2 Module (1=present)";
CM_ SG_ 998 BU_NetCfg_VES3_I "Backup for CAN I Video Ent. System screen 1 Module (1=present)";
CM_ SG_ 998 BU_NetCfg_CRSM "Backup for CAN I Comfort Rear Seat Module (1=present)";
CM_ SG_ 998 BU_NetCfg_HVAC_R "Backup for CAN I Rear Heating Ventilation Air Conditioning (1=present)";
BA_DEF_ SG_  "GenSigTimeout_ADCM" INT 0 65535;
BA_DEF_ SG_  "GenSigTimeout_AFLS" INT 0 65535;
BA_DEF_ SG_  "GenSigTimeout_CBC" INT 0 65535;
BA_DEF_ SG_  "GenSigTimeout_DTCM" INT 0 65535;
BA_DEF_ SG_  "GenSigTimeout_ECM" INT 0 65535;
BA_DEF_ SG_  "GenSigTimeout_EPS" INT 0 65535;
BA_DEF_ SG_  "GenSigTimeout_ESC" INT 0 65535;
BA_DEF_ SG_  "GenSigTimeout_ESM" INT 0 65535;
BA_DEF_ SG_  "GenSigTimeout_ETM" INT 0 65535;
BA_DEF_ SG_  "GenSigTimeout_HaLF" INT 0 65535;
BA_DEF_ SG_  "GenSigTimeout_IC" INT 0 65535;
BA_DEF_ SG_  "GenSigTimeout_ORC" INT 0 65535;
BA_DEF_ SG_  "GenSigTimeout_PTS" INT 0 65535;
BA_DEF_ SG_  "GenSigTimeout_RF_HUB" INT 0 65535;
BA_DEF_ SG_  "GenSigTimeout_SCCM" INT 0 65535;
BA_DEF_ SG_  "GenSigTimeout_TPM" INT 0 65535;
BA_DEF_ BO_  "GenMsgStartValue" STRING ;
BA_DEF_ SG_  "GenSigSNA" STRING ;
BA_DEF_ SG_  "FlexKomIsMotorola" ENUM  "nein","ja";
BA_DEF_ SG_  "FlexKomSigLaenge" INT 0 64;
BA_DEF_ SG_  "FlexKomSigStartPos" INT 0 63;
BA_DEF_ SG_  "FlexKomComment" STRING ;
BA_DEF_ SG_  "FlexKomSigName" STRING ;
BA_DEF_ SG_  "FlexKomSID" INT 0 2147483647;
BA_DEF_ SG_  "GenSigStartValue" HEX 0 4294967295;
BA_DEF_ SG_  "FlexKomSigStartValue" STRING ;
BA_DEF_ SG_  "GenSigCycleTimeActive" INT 0 65535;
BA_DEF_ SG_  "GenSigCycleTime" INT 0 65535;
BA_DEF_ SG_  "GenSigSendType" ENUM  "cyclicX","spontanX","cyclicIfActiveX","spontanWithDelay","cyclicAndSpontanX","cyclicAndSpontanWithDelay","spontanWithRepitition","cyclicIfActiveAndSpontanWD","cyclicIfActiveFast","cyclicWithRepeatOnDemand","none";
BA_DEF_ BO_  "GenMsgNrOfRepetitions" INT 0 65535;
BA_DEF_ BO_  "GenMsgDelayTime" INT 0 65535;
BA_DEF_ BO_  "GenMsgStartDelayTime" INT 0 65535;
BA_DEF_ BO_  "GenMsgCycleTimeActive" INT 0 65535;
BA_DEF_ BO_  "GenMsgCycleTime" INT 0 65535;
BA_DEF_ BO_  "GenMsgSendType" ENUM  "cyclicX","spontanX","cyclicIfActiveX","spontanWithDelay","cyclicAndSpontanX","cyclicAndSpontanWithDelay","spontanWithRepitition","cyclicIfActiveAndSpontanWD","cyclicIfActiveFast","cyclicWithRepeatOnDemand","none";
BA_DEF_ BO_  "DiagResponse" ENUM  "nein","ja";
BA_DEF_ BO_  "DiagRequest" ENUM  "nein","ja";
BA_DEF_ BO_  "DiagState" ENUM  "nein","ja";
BA_DEF_ BO_  "App-Botschaft" ENUM  "nein","ja";
BA_DEF_ BO_  "NWM-Botschaft" ENUM  "nein","ja";
BA_DEF_DEF_  "GenSigTimeout_ADCM" 0;
BA_DEF_DEF_  "GenSigTimeout_AFLS" 0;
BA_DEF_DEF_  "GenSigTimeout_CBC" 0;
BA_DEF_DEF_  "GenSigTimeout_DTCM" 0;
BA_DEF_DEF_  "GenSigTimeout_ECM" 0;
BA_DEF_DEF_  "GenSigTimeout_EPS" 0;
BA_DEF_DEF_  "GenSigTimeout_ESC" 0;
BA_DEF_DEF_  "GenSigTimeout_ESM" 0;
BA_DEF_DEF_  "GenSigTimeout_ETM" 0;
BA_DEF_DEF_  "GenSigTimeout_HaLF" 0;
BA_DEF_DEF_  "GenSigTimeout_IC" 0;
BA_DEF_DEF_  "GenSigTimeout_ORC" 0;
BA_DEF_DEF_  "GenSigTimeout_PTS" 0;
BA_DEF_DEF_  "GenSigTimeout_RF_HUB" 0;
BA_DEF_DEF_  "GenSigTimeout_SCCM" 0;
BA_DEF_DEF_  "GenSigTimeout_TPM" 0;
BA_DEF_DEF_  "GenMsgStartValue" "";
BA_DEF_DEF_  "GenSigSNA" "";
BA_DEF_DEF_  "FlexKomIsMotorola" "nein";
BA_DEF_DEF_  "FlexKomSigLaenge" 0;
BA_DEF_DEF_  "FlexKomSigStartPos" 0;
BA_DEF_DEF_  "FlexKomComment" "";
BA_DEF_DEF_  "FlexKomSigName" "";
BA_DEF_DEF_  "FlexKomSID" 0;
BA_DEF_DEF_  "GenSigStartValue" 0;
BA_DEF_DEF_  "FlexKomSigStartValue" "";
BA_DEF_DEF_  "GenSigCycleTimeActive" 0;
BA_DEF_DEF_  "GenSigCycleTime" 0;
BA_DEF_DEF_  "GenSigSendType" "cyclicX";
BA_DEF_DEF_  "GenMsgNrOfRepetitions" 0;
BA_DEF_DEF_  "GenMsgDelayTime" 0;
BA_DEF_DEF_  "GenMsgStartDelayTime" 0;
BA_DEF_DEF_  "GenMsgCycleTimeActive" 0;
BA_DEF_DEF_  "GenMsgCycleTime" 0;
BA_DEF_DEF_  "GenMsgSendType" "cyclicX";
BA_DEF_DEF_  "DiagResponse" "nein";
BA_DEF_DEF_  "DiagRequest" "nein";
BA_DEF_DEF_  "DiagState" "nein";
BA_DEF_DEF_  "App-Botschaft" "nein";
BA_DEF_DEF_  "NWM-Botschaft" "nein";
BA_ "GenMsgSendType" BO_ 974 5;
BA_ "GenMsgCycleTime" BO_ 974 1000;
BA_ "GenMsgDelayTime" BO_ 974 20;
BA_ "GenMsgNrOfRepetitions" BO_ 974 2;
BA_ "GenMsgStartValue" BO_ 974 "7F0F7F7F7Fh";
BA_ "GenMsgStartDelayTime" BO_ 974 70;
BA_ "GenMsgSendType" BO_ 975 9;
BA_ "GenMsgCycleTime" BO_ 975 100;
BA_ "GenMsgDelayTime" BO_ 975 100;
BA_ "GenMsgNrOfRepetitions" BO_ 975 3;
BA_ "GenMsgStartValue" BO_ 975 "0F00000000000000h";
BA_ "GenMsgCycleTime" BO_ 977 500;
BA_ "GenMsgDelayTime" BO_ 977 20;
BA_ "GenMsgNrOfRepetitions" BO_ 977 2;
BA_ "GenMsgStartValue" BO_ 977 "FF000000h";
BA_ "GenMsgCycleTime" BO_ 979 2000;
BA_ "GenMsgDelayTime" BO_ 979 20;
BA_ "GenMsgNrOfRepetitions" BO_ 979 2;
BA_ "GenMsgStartValue" BO_ 979 "0300000000000000h";
BA_ "GenMsgStartDelayTime" BO_ 979 130;
BA_ "GenMsgCycleTime" BO_ 980 2000;
BA_ "GenMsgDelayTime" BO_ 980 20;
BA_ "GenMsgNrOfRepetitions" BO_ 980 2;
BA_ "GenMsgStartValue" BO_ 980 "0300000000000000h";
BA_ "GenMsgStartDelayTime" BO_ 980 130;
BA_ "GenMsgSendType" BO_ 981 5;
BA_ "GenMsgCycleTime" BO_ 981 2000;
BA_ "GenMsgDelayTime" BO_ 981 20;
BA_ "GenMsgNrOfRepetitions" BO_ 981 2;
BA_ "GenMsgStartValue" BO_ 981 "0300000000000000h";
BA_ "GenMsgStartDelayTime" BO_ 981 120;
BA_ "GenMsgCycleTime" BO_ 982 2000;
BA_ "GenMsgDelayTime" BO_ 982 20;
BA_ "GenMsgNrOfRepetitions" BO_ 982 2;
BA_ "GenMsgStartValue" BO_ 982 "0300000000000000h";
BA_ "GenMsgStartDelayTime" BO_ 982 130;
BA_ "GenMsgSendType" BO_ 983 5;
BA_ "GenMsgCycleTime" BO_ 983 2000;
BA_ "GenMsgDelayTime" BO_ 983 20;
BA_ "GenMsgNrOfRepetitions" BO_ 983 2;
BA_ "GenMsgStartValue" BO_ 983 "0300000000000000h";
BA_ "GenMsgStartDelayTime" BO_ 983 100;
BA_ "GenMsgCycleTime" BO_ 984 2000;
BA_ "GenMsgDelayTime" BO_ 984 20;
BA_ "GenMsgNrOfRepetitions" BO_ 984 2;
BA_ "GenMsgStartValue" BO_ 984 "0300000000000000h";
BA_ "GenMsgStartDelayTime" BO_ 984 90;
BA_ "GenMsgSendType" BO_ 985 1;
BA_ "GenMsgDelayTime" BO_ 985 20;
BA_ "GenMsgNrOfRepetitions" BO_ 985 2;
BA_ "GenMsgStartValue" BO_ 985 "0300000000000000h";
BA_ "GenMsgSendType" BO_ 986 1;
BA_ "GenMsgDelayTime" BO_ 986 20;
BA_ "GenMsgNrOfRepetitions" BO_ 986 2;
BA_ "GenMsgStartValue" BO_ 986 "0300000000000000h";
BA_ "GenMsgSendType" BO_ 987 1;
BA_ "GenMsgDelayTime" BO_ 987 20;
BA_ "GenMsgNrOfRepetitions" BO_ 987 2;
BA_ "GenMsgStartValue" BO_ 987 "0300000000000000h";
BA_ "GenMsgSendType" BO_ 988 1;
BA_ "GenMsgDelayTime" BO_ 988 20;
BA_ "GenMsgNrOfRepetitions" BO_ 988 2;
BA_ "GenMsgStartValue" BO_ 988 "0300000000000000h";
BA_ "GenMsgSendType" BO_ 989 1;
BA_ "GenMsgDelayTime" BO_ 989 20;
BA_ "GenMsgNrOfRepetitions" BO_ 989 2;
BA_ "GenMsgStartValue" BO_ 989 "0300000000000000h";
BA_ "GenMsgSendType" BO_ 991 1;
BA_ "GenMsgDelayTime" BO_ 991 20;
BA_ "GenMsgNrOfRepetitions" BO_ 991 2;
BA_ "GenMsgStartValue" BO_ 991 "0300000000000000h";
BA_ "GenMsgCycleTime" BO_ 992 100;
BA_ "GenMsgDelayTime" BO_ 992 20;
BA_ "GenMsgNrOfRepetitions" BO_ 992 2;
BA_ "GenMsgStartValue" BO_ 992 "0300000000000000h";
BA_ "GenMsgCycleTime" BO_ 993 100;
BA_ "GenMsgDelayTime" BO_ 993 20;
BA_ "GenMsgNrOfRepetitions" BO_ 993 2;
BA_ "GenMsgStartValue" BO_ 993 "FFEFE7E71F0000h";
BA_ "GenMsgSendType" BO_ 994 5;
BA_ "GenMsgCycleTime" BO_ 994 2000;
BA_ "GenMsgDelayTime" BO_ 994 20;
BA_ "GenMsgNrOfRepetitions" BO_ 994 2;
BA_ "GenMsgStartValue" BO_ 994 "030000h";
BA_ "GenMsgStartDelayTime" BO_ 994 10;
BA_ "GenMsgSendType" BO_ 995 5;
BA_ "GenMsgCycleTime" BO_ 995 2000;
BA_ "GenMsgDelayTime" BO_ 995 20;
BA_ "GenMsgNrOfRepetitions" BO_ 995 2;
BA_ "GenMsgStartValue" BO_ 995 "0300000000000000h";
BA_ "GenMsgStartDelayTime" BO_ 995 20;
BA_ "GenMsgSendType" BO_ 996 5;
BA_ "GenMsgCycleTime" BO_ 996 2000;
BA_ "GenMsgDelayTime" BO_ 996 20;
BA_ "GenMsgNrOfRepetitions" BO_ 996 2;
BA_ "GenMsgStartValue" BO_ 996 "0300000000000000h";
BA_ "GenMsgStartDelayTime" BO_ 996 10;
BA_ "GenMsgSendType" BO_ 997 1;
BA_ "GenMsgDelayTime" BO_ 997 20;
BA_ "GenMsgNrOfRepetitions" BO_ 997 2;
BA_ "GenMsgStartValue" BO_ 997 "030000h";
BA_ "GenMsgSendType" BO_ 998 1;
BA_ "GenMsgDelayTime" BO_ 998 20;
BA_ "GenMsgNrOfRepetitions" BO_ 998 2;
BA_ "GenMsgStartValue" BO_ 998 "0300000000000000h";
BA_ "GenSigSendType" SG_ 974 FT_HVAC_BLW_FN_SP 5;
BA_ "GenSigCycleTime" SG_ 974 FT_HVAC_BLW_FN_SP 1000;
BA_ "FlexKomSigStartValue" SG_ 974 FT_HVAC_BLW_FN_SP "7F0F7F7F7Fh";
BA_ "GenSigStartValue" SG_ 974 FT_HVAC_BLW_FN_SP 127;
BA_ "FlexKomSID" SG_ 974 FT_HVAC_BLW_FN_SP 1445;
BA_ "FlexKomSigStartPos" SG_ 974 FT_HVAC_BLW_FN_SP 7;
BA_ "FlexKomSigLaenge" SG_ 974 FT_HVAC_BLW_FN_SP 40;
BA_ "FlexKomSigName" SG_ 974 FT_HVAC_BLW_FN_SP "GW_Dev";
BA_ "FlexKomComment" SG_ 974 FT_HVAC_BLW_FN_SP "Temporary development packet - route signals from ";
BA_ "FlexKomIsMotorola" SG_ 974 FT_HVAC_BLW_FN_SP 1;
BA_ "GenSigSNA" SG_ 974 FT_HVAC_BLW_FN_SP "7Fh";
BA_ "GenSigSendType" SG_ 974 FT_HVAC_MD_STAT 5;
BA_ "GenSigCycleTime" SG_ 974 FT_HVAC_MD_STAT 1000;
BA_ "FlexKomSigStartValue" SG_ 974 FT_HVAC_MD_STAT "7F0F7F7F7Fh";
BA_ "GenSigStartValue" SG_ 974 FT_HVAC_MD_STAT 15;
BA_ "FlexKomSID" SG_ 974 FT_HVAC_MD_STAT 1445;
BA_ "FlexKomSigStartPos" SG_ 974 FT_HVAC_MD_STAT 7;
BA_ "FlexKomSigLaenge" SG_ 974 FT_HVAC_MD_STAT 40;
BA_ "FlexKomSigName" SG_ 974 FT_HVAC_MD_STAT "GW_Dev";
BA_ "FlexKomComment" SG_ 974 FT_HVAC_MD_STAT "Temporary development packet - route signals from ";
BA_ "FlexKomIsMotorola" SG_ 974 FT_HVAC_MD_STAT 1;
BA_ "GenSigSNA" SG_ 974 FT_HVAC_MD_STAT "Fh";
BA_ "GenSigSendType" SG_ 974 FT_HVAC_CTRL_STAT 5;
BA_ "GenSigCycleTime" SG_ 974 FT_HVAC_CTRL_STAT 1000;
BA_ "FlexKomSigStartValue" SG_ 974 FT_HVAC_CTRL_STAT "7F0F7F7F7Fh";
BA_ "FlexKomSID" SG_ 974 FT_HVAC_CTRL_STAT 1445;
BA_ "FlexKomSigStartPos" SG_ 974 FT_HVAC_CTRL_STAT 7;
BA_ "FlexKomSigLaenge" SG_ 974 FT_HVAC_CTRL_STAT 40;
BA_ "FlexKomSigName" SG_ 974 FT_HVAC_CTRL_STAT "GW_Dev";
BA_ "FlexKomComment" SG_ 974 FT_HVAC_CTRL_STAT "Temporary development packet - route signals from ";
BA_ "FlexKomIsMotorola" SG_ 974 FT_HVAC_CTRL_STAT 1;
BA_ "GenSigSNA" SG_ 974 FT_HVAC_CTRL_STAT "7h";
BA_ "GenSigSendType" SG_ 974 DRV_TEMP_DR_POS 5;
BA_ "GenSigCycleTime" SG_ 974 DRV_TEMP_DR_POS 1000;
BA_ "FlexKomSigStartValue" SG_ 974 DRV_TEMP_DR_POS "7F0F7F7F7Fh";
BA_ "GenSigStartValue" SG_ 974 DRV_TEMP_DR_POS 127;
BA_ "FlexKomSID" SG_ 974 DRV_TEMP_DR_POS 1445;
BA_ "FlexKomSigStartPos" SG_ 974 DRV_TEMP_DR_POS 7;
BA_ "FlexKomSigLaenge" SG_ 974 DRV_TEMP_DR_POS 40;
BA_ "FlexKomSigName" SG_ 974 DRV_TEMP_DR_POS "GW_Dev";
BA_ "FlexKomComment" SG_ 974 DRV_TEMP_DR_POS "Temporary development packet - route signals from ";
BA_ "FlexKomIsMotorola" SG_ 974 DRV_TEMP_DR_POS 1;
BA_ "GenSigSNA" SG_ 974 DRV_TEMP_DR_POS "7Fh";
BA_ "GenSigSendType" SG_ 974 PAS_TEMP_DR_POS 5;
BA_ "GenSigCycleTime" SG_ 974 PAS_TEMP_DR_POS 1000;
BA_ "FlexKomSigStartValue" SG_ 974 PAS_TEMP_DR_POS "7F0F7F7F7Fh";
BA_ "GenSigStartValue" SG_ 974 PAS_TEMP_DR_POS 127;
BA_ "FlexKomSID" SG_ 974 PAS_TEMP_DR_POS 1445;
BA_ "FlexKomSigStartPos" SG_ 974 PAS_TEMP_DR_POS 7;
BA_ "FlexKomSigLaenge" SG_ 974 PAS_TEMP_DR_POS 40;
BA_ "FlexKomSigName" SG_ 974 PAS_TEMP_DR_POS "GW_Dev";
BA_ "FlexKomComment" SG_ 974 PAS_TEMP_DR_POS "Temporary development packet - route signals from ";
BA_ "FlexKomIsMotorola" SG_ 974 PAS_TEMP_DR_POS 1;
BA_ "GenSigSNA" SG_ 974 PAS_TEMP_DR_POS "7Fh";
BA_ "GenSigSendType" SG_ 974 R_TEMP_DR_POS 5;
BA_ "GenSigCycleTime" SG_ 974 R_TEMP_DR_POS 1000;
BA_ "FlexKomSigStartValue" SG_ 974 R_TEMP_DR_POS "7F0F7F7F7Fh";
BA_ "GenSigStartValue" SG_ 974 R_TEMP_DR_POS 127;
BA_ "FlexKomSID" SG_ 974 R_TEMP_DR_POS 1445;
BA_ "FlexKomSigStartPos" SG_ 974 R_TEMP_DR_POS 7;
BA_ "FlexKomSigLaenge" SG_ 974 R_TEMP_DR_POS 40;
BA_ "FlexKomSigName" SG_ 974 R_TEMP_DR_POS "GW_Dev";
BA_ "FlexKomComment" SG_ 974 R_TEMP_DR_POS "Temporary development packet - route signals from ";
BA_ "FlexKomIsMotorola" SG_ 974 R_TEMP_DR_POS 1;
BA_ "GenSigSNA" SG_ 974 R_TEMP_DR_POS "7Fh";
BA_ "GenSigSendType" SG_ 975 SRT_CTRL3 9;
BA_ "GenSigCycleTime" SG_ 975 SRT_CTRL3 100;
BA_ "FlexKomSigStartValue" SG_ 975 SRT_CTRL3 "0F00000000000000h";
BA_ "GenSigStartValue" SG_ 975 SRT_CTRL3 15;
BA_ "FlexKomSID" SG_ 975 SRT_CTRL3 1992;
BA_ "FlexKomSigStartPos" SG_ 975 SRT_CTRL3 7;
BA_ "FlexKomSigLaenge" SG_ 975 SRT_CTRL3 64;
BA_ "FlexKomSigName" SG_ 975 SRT_CTRL3 "IC_SRT_PKT";
BA_ "FlexKomComment" SG_ 975 SRT_CTRL3 "IC SRT packet";
BA_ "FlexKomIsMotorola" SG_ 975 SRT_CTRL3 1;
BA_ "GenSigSNA" SG_ 975 SRT_CTRL3 "Fh";
BA_ "GenSigSendType" SG_ 975 SRT_60mphTmC 9;
BA_ "GenSigCycleTime" SG_ 975 SRT_60mphTmC 100;
BA_ "FlexKomSigStartValue" SG_ 975 SRT_60mphTmC "0F00000000000000h";
BA_ "GenSigStartValue" SG_ 975 SRT_60mphTmC 255;
BA_ "FlexKomSID" SG_ 975 SRT_60mphTmC 1992;
BA_ "FlexKomSigStartPos" SG_ 975 SRT_60mphTmC 7;
BA_ "FlexKomSigLaenge" SG_ 975 SRT_60mphTmC 64;
BA_ "FlexKomSigName" SG_ 975 SRT_60mphTmC "IC_SRT_PKT";
BA_ "FlexKomComment" SG_ 975 SRT_60mphTmC "IC SRT packet";
BA_ "FlexKomIsMotorola" SG_ 975 SRT_60mphTmC 1;
BA_ "GenSigSNA" SG_ 975 SRT_60mphTmC "FFh";
BA_ "GenSigSendType" SG_ 975 SRT_60mphTmB 9;
BA_ "GenSigCycleTime" SG_ 975 SRT_60mphTmB 100;
BA_ "FlexKomSigStartValue" SG_ 975 SRT_60mphTmB "0F00000000000000h";
BA_ "GenSigStartValue" SG_ 975 SRT_60mphTmB 255;
BA_ "FlexKomSID" SG_ 975 SRT_60mphTmB 1992;
BA_ "FlexKomSigStartPos" SG_ 975 SRT_60mphTmB 7;
BA_ "FlexKomSigLaenge" SG_ 975 SRT_60mphTmB 64;
BA_ "FlexKomSigName" SG_ 975 SRT_60mphTmB "IC_SRT_PKT";
BA_ "FlexKomComment" SG_ 975 SRT_60mphTmB "IC SRT packet";
BA_ "FlexKomIsMotorola" SG_ 975 SRT_60mphTmB 1;
BA_ "GenSigSNA" SG_ 975 SRT_60mphTmB "FFh";
BA_ "GenSigSendType" SG_ 975 SRT_100mphTmL 9;
BA_ "GenSigCycleTime" SG_ 975 SRT_100mphTmL 100;
BA_ "FlexKomSigStartValue" SG_ 975 SRT_100mphTmL "0F00000000000000h";
BA_ "GenSigStartValue" SG_ 975 SRT_100mphTmL 255;
BA_ "FlexKomSID" SG_ 975 SRT_100mphTmL 1992;
BA_ "FlexKomSigStartPos" SG_ 975 SRT_100mphTmL 7;
BA_ "FlexKomSigLaenge" SG_ 975 SRT_100mphTmL 64;
BA_ "FlexKomSigName" SG_ 975 SRT_100mphTmL "IC_SRT_PKT";
BA_ "FlexKomComment" SG_ 975 SRT_100mphTmL "IC SRT packet";
BA_ "FlexKomIsMotorola" SG_ 975 SRT_100mphTmL 1;
BA_ "GenSigSNA" SG_ 975 SRT_100mphTmL "FFh";
BA_ "GenSigSendType" SG_ 975 SRT_100mphTm_C 9;
BA_ "GenSigCycleTime" SG_ 975 SRT_100mphTm_C 100;
BA_ "FlexKomSigStartValue" SG_ 975 SRT_100mphTm_C "0F00000000000000h";
BA_ "GenSigStartValue" SG_ 975 SRT_100mphTm_C 255;
BA_ "FlexKomSID" SG_ 975 SRT_100mphTm_C 1992;
BA_ "FlexKomSigStartPos" SG_ 975 SRT_100mphTm_C 7;
BA_ "FlexKomSigLaenge" SG_ 975 SRT_100mphTm_C 64;
BA_ "FlexKomSigName" SG_ 975 SRT_100mphTm_C "IC_SRT_PKT";
BA_ "FlexKomComment" SG_ 975 SRT_100mphTm_C "IC SRT packet";
BA_ "FlexKomIsMotorola" SG_ 975 SRT_100mphTm_C 1;
BA_ "GenSigSNA" SG_ 975 SRT_100mphTm_C "FFh";
BA_ "GenSigSendType" SG_ 975 SRT_100mphTm_B 9;
BA_ "GenSigCycleTime" SG_ 975 SRT_100mphTm_B 100;
BA_ "FlexKomSigStartValue" SG_ 975 SRT_100mphTm_B "0F00000000000000h";
BA_ "GenSigStartValue" SG_ 975 SRT_100mphTm_B 255;
BA_ "FlexKomSID" SG_ 975 SRT_100mphTm_B 1992;
BA_ "FlexKomSigStartPos" SG_ 975 SRT_100mphTm_B 7;
BA_ "FlexKomSigLaenge" SG_ 975 SRT_100mphTm_B 64;
BA_ "FlexKomSigName" SG_ 975 SRT_100mphTm_B "IC_SRT_PKT";
BA_ "FlexKomComment" SG_ 975 SRT_100mphTm_B "IC SRT packet";
BA_ "FlexKomIsMotorola" SG_ 975 SRT_100mphTm_B 1;
BA_ "GenSigSNA" SG_ 975 SRT_100mphTm_B "FFh";
BA_ "GenSigSendType" SG_ 975 SRT_100mphTm_L 9;
BA_ "GenSigCycleTime" SG_ 975 SRT_100mphTm_L 100;
BA_ "FlexKomSigStartValue" SG_ 975 SRT_100mphTm_L "0F00000000000000h";
BA_ "GenSigStartValue" SG_ 975 SRT_100mphTm_L 255;
BA_ "FlexKomSID" SG_ 975 SRT_100mphTm_L 1992;
BA_ "FlexKomSigStartPos" SG_ 975 SRT_100mphTm_L 7;
BA_ "FlexKomSigLaenge" SG_ 975 SRT_100mphTm_L 64;
BA_ "FlexKomSigName" SG_ 975 SRT_100mphTm_L "IC_SRT_PKT";
BA_ "FlexKomComment" SG_ 975 SRT_100mphTm_L "IC SRT packet";
BA_ "FlexKomIsMotorola" SG_ 975 SRT_100mphTm_L 1;
BA_ "GenSigSNA" SG_ 975 SRT_100mphTm_L "FFh";
BA_ "GenSigSendType" SG_ 975 SRT_60mphTmL 9;
BA_ "GenSigCycleTime" SG_ 975 SRT_60mphTmL 100;
BA_ "FlexKomSigStartValue" SG_ 975 SRT_60mphTmL "0F00000000000000h";
BA_ "GenSigStartValue" SG_ 975 SRT_60mphTmL 255;
BA_ "FlexKomSID" SG_ 975 SRT_60mphTmL 1992;
BA_ "FlexKomSigStartPos" SG_ 975 SRT_60mphTmL 7;
BA_ "FlexKomSigLaenge" SG_ 975 SRT_60mphTmL 64;
BA_ "FlexKomSigName" SG_ 975 SRT_60mphTmL "IC_SRT_PKT";
BA_ "FlexKomComment" SG_ 975 SRT_60mphTmL "IC SRT packet";
BA_ "FlexKomIsMotorola" SG_ 975 SRT_60mphTmL 1;
BA_ "GenSigSNA" SG_ 975 SRT_60mphTmL "FFh";
BA_ "GenSigSendType" SG_ 975 SRT_60mphTm_C 9;
BA_ "GenSigCycleTime" SG_ 975 SRT_60mphTm_C 100;
BA_ "FlexKomSigStartValue" SG_ 975 SRT_60mphTm_C "0F00000000000000h";
BA_ "GenSigStartValue" SG_ 975 SRT_60mphTm_C 255;
BA_ "FlexKomSID" SG_ 975 SRT_60mphTm_C 1992;
BA_ "FlexKomSigStartPos" SG_ 975 SRT_60mphTm_C 7;
BA_ "FlexKomSigLaenge" SG_ 975 SRT_60mphTm_C 64;
BA_ "FlexKomSigName" SG_ 975 SRT_60mphTm_C "IC_SRT_PKT";
BA_ "FlexKomComment" SG_ 975 SRT_60mphTm_C "IC SRT packet";
BA_ "FlexKomIsMotorola" SG_ 975 SRT_60mphTm_C 1;
BA_ "GenSigSNA" SG_ 975 SRT_60mphTm_C "FFh";
BA_ "GenSigSendType" SG_ 975 SRT_60mphTm_B 9;
BA_ "GenSigCycleTime" SG_ 975 SRT_60mphTm_B 100;
BA_ "FlexKomSigStartValue" SG_ 975 SRT_60mphTm_B "0F00000000000000h";
BA_ "GenSigStartValue" SG_ 975 SRT_60mphTm_B 255;
BA_ "FlexKomSID" SG_ 975 SRT_60mphTm_B 1992;
BA_ "FlexKomSigStartPos" SG_ 975 SRT_60mphTm_B 7;
BA_ "FlexKomSigLaenge" SG_ 975 SRT_60mphTm_B 64;
BA_ "FlexKomSigName" SG_ 975 SRT_60mphTm_B "IC_SRT_PKT";
BA_ "FlexKomComment" SG_ 975 SRT_60mphTm_B "IC SRT packet";
BA_ "FlexKomIsMotorola" SG_ 975 SRT_60mphTm_B 1;
BA_ "GenSigSNA" SG_ 975 SRT_60mphTm_B "FFh";
BA_ "GenSigSendType" SG_ 975 SRT_60mphTm_L 9;
BA_ "GenSigCycleTime" SG_ 975 SRT_60mphTm_L 100;
BA_ "FlexKomSigStartValue" SG_ 975 SRT_60mphTm_L "0F00000000000000h";
BA_ "GenSigStartValue" SG_ 975 SRT_60mphTm_L 255;
BA_ "FlexKomSID" SG_ 975 SRT_60mphTm_L 1992;
BA_ "FlexKomSigStartPos" SG_ 975 SRT_60mphTm_L 7;
BA_ "FlexKomSigLaenge" SG_ 975 SRT_60mphTm_L 64;
BA_ "FlexKomSigName" SG_ 975 SRT_60mphTm_L "IC_SRT_PKT";
BA_ "FlexKomComment" SG_ 975 SRT_60mphTm_L "IC SRT packet";
BA_ "FlexKomIsMotorola" SG_ 975 SRT_60mphTm_L 1;
BA_ "GenSigSNA" SG_ 975 SRT_60mphTm_L "FFh";
BA_ "GenSigSendType" SG_ 975 SRT_100mphTmC 9;
BA_ "GenSigCycleTime" SG_ 975 SRT_100mphTmC 100;
BA_ "FlexKomSigStartValue" SG_ 975 SRT_100mphTmC "0F00000000000000h";
BA_ "GenSigStartValue" SG_ 975 SRT_100mphTmC 255;
BA_ "FlexKomSID" SG_ 975 SRT_100mphTmC 1992;
BA_ "FlexKomSigStartPos" SG_ 975 SRT_100mphTmC 7;
BA_ "FlexKomSigLaenge" SG_ 975 SRT_100mphTmC 64;
BA_ "FlexKomSigName" SG_ 975 SRT_100mphTmC "IC_SRT_PKT";
BA_ "FlexKomComment" SG_ 975 SRT_100mphTmC "IC SRT packet";
BA_ "FlexKomIsMotorola" SG_ 975 SRT_100mphTmC 1;
BA_ "GenSigSNA" SG_ 975 SRT_100mphTmC "FFh";
BA_ "GenSigSendType" SG_ 975 SRT_100mphTmB 9;
BA_ "GenSigCycleTime" SG_ 975 SRT_100mphTmB 100;
BA_ "FlexKomSigStartValue" SG_ 975 SRT_100mphTmB "0F00000000000000h";
BA_ "GenSigStartValue" SG_ 975 SRT_100mphTmB 255;
BA_ "FlexKomSID" SG_ 975 SRT_100mphTmB 1992;
BA_ "FlexKomSigStartPos" SG_ 975 SRT_100mphTmB 7;
BA_ "FlexKomSigLaenge" SG_ 975 SRT_100mphTmB 64;
BA_ "FlexKomSigName" SG_ 975 SRT_100mphTmB "IC_SRT_PKT";
BA_ "FlexKomComment" SG_ 975 SRT_100mphTmB "IC SRT packet";
BA_ "FlexKomIsMotorola" SG_ 975 SRT_100mphTmB 1;
BA_ "GenSigSNA" SG_ 975 SRT_100mphTmB "FFh";
BA_ "GenSigSendType" SG_ 975 SRT_eighthTmC 9;
BA_ "GenSigCycleTime" SG_ 975 SRT_eighthTmC 100;
BA_ "FlexKomSigStartValue" SG_ 975 SRT_eighthTmC "0F00000000000000h";
BA_ "GenSigStartValue" SG_ 975 SRT_eighthTmC 255;
BA_ "FlexKomSID" SG_ 975 SRT_eighthTmC 1992;
BA_ "FlexKomSigStartPos" SG_ 975 SRT_eighthTmC 7;
BA_ "FlexKomSigLaenge" SG_ 975 SRT_eighthTmC 64;
BA_ "FlexKomSigName" SG_ 975 SRT_eighthTmC "IC_SRT_PKT";
BA_ "FlexKomComment" SG_ 975 SRT_eighthTmC "IC SRT packet";
BA_ "FlexKomIsMotorola" SG_ 975 SRT_eighthTmC 1;
BA_ "GenSigSNA" SG_ 975 SRT_eighthTmC "FFh";
BA_ "GenSigSendType" SG_ 975 SRT_eighthTmB 9;
BA_ "GenSigCycleTime" SG_ 975 SRT_eighthTmB 100;
BA_ "FlexKomSigStartValue" SG_ 975 SRT_eighthTmB "0F00000000000000h";
BA_ "GenSigStartValue" SG_ 975 SRT_eighthTmB 255;
BA_ "FlexKomSID" SG_ 975 SRT_eighthTmB 1992;
BA_ "FlexKomSigStartPos" SG_ 975 SRT_eighthTmB 7;
BA_ "FlexKomSigLaenge" SG_ 975 SRT_eighthTmB 64;
BA_ "FlexKomSigName" SG_ 975 SRT_eighthTmB "IC_SRT_PKT";
BA_ "FlexKomComment" SG_ 975 SRT_eighthTmB "IC SRT packet";
BA_ "FlexKomIsMotorola" SG_ 975 SRT_eighthTmB 1;
BA_ "GenSigSNA" SG_ 975 SRT_eighthTmB "FFh";
BA_ "GenSigSendType" SG_ 975 SRT_BrkTmL 9;
BA_ "GenSigCycleTime" SG_ 975 SRT_BrkTmL 100;
BA_ "FlexKomSigStartValue" SG_ 975 SRT_BrkTmL "0F00000000000000h";
BA_ "GenSigStartValue" SG_ 975 SRT_BrkTmL 255;
BA_ "FlexKomSID" SG_ 975 SRT_BrkTmL 1992;
BA_ "FlexKomSigStartPos" SG_ 975 SRT_BrkTmL 7;
BA_ "FlexKomSigLaenge" SG_ 975 SRT_BrkTmL 64;
BA_ "FlexKomSigName" SG_ 975 SRT_BrkTmL "IC_SRT_PKT";
BA_ "FlexKomComment" SG_ 975 SRT_BrkTmL "IC SRT packet";
BA_ "FlexKomIsMotorola" SG_ 975 SRT_BrkTmL 1;
BA_ "GenSigSNA" SG_ 975 SRT_BrkTmL "FFh";
BA_ "GenSigSendType" SG_ 975 SRT_BrkTm_C 9;
BA_ "GenSigCycleTime" SG_ 975 SRT_BrkTm_C 100;
BA_ "FlexKomSigStartValue" SG_ 975 SRT_BrkTm_C "0F00000000000000h";
BA_ "GenSigStartValue" SG_ 975 SRT_BrkTm_C 255;
BA_ "FlexKomSID" SG_ 975 SRT_BrkTm_C 1992;
BA_ "FlexKomSigStartPos" SG_ 975 SRT_BrkTm_C 7;
BA_ "FlexKomSigLaenge" SG_ 975 SRT_BrkTm_C 64;
BA_ "FlexKomSigName" SG_ 975 SRT_BrkTm_C "IC_SRT_PKT";
BA_ "FlexKomComment" SG_ 975 SRT_BrkTm_C "IC SRT packet";
BA_ "FlexKomIsMotorola" SG_ 975 SRT_BrkTm_C 1;
BA_ "GenSigSNA" SG_ 975 SRT_BrkTm_C "FFh";
BA_ "GenSigSendType" SG_ 975 SRT_BrkTm_B 9;
BA_ "GenSigCycleTime" SG_ 975 SRT_BrkTm_B 100;
BA_ "FlexKomSigStartValue" SG_ 975 SRT_BrkTm_B "0F00000000000000h";
BA_ "GenSigStartValue" SG_ 975 SRT_BrkTm_B 255;
BA_ "FlexKomSID" SG_ 975 SRT_BrkTm_B 1992;
BA_ "FlexKomSigStartPos" SG_ 975 SRT_BrkTm_B 7;
BA_ "FlexKomSigLaenge" SG_ 975 SRT_BrkTm_B 64;
BA_ "FlexKomSigName" SG_ 975 SRT_BrkTm_B "IC_SRT_PKT";
BA_ "FlexKomComment" SG_ 975 SRT_BrkTm_B "IC SRT packet";
BA_ "FlexKomIsMotorola" SG_ 975 SRT_BrkTm_B 1;
BA_ "GenSigSNA" SG_ 975 SRT_BrkTm_B "FFh";
BA_ "GenSigSendType" SG_ 975 SRT_BrkTm_L 9;
BA_ "GenSigCycleTime" SG_ 975 SRT_BrkTm_L 100;
BA_ "FlexKomSigStartValue" SG_ 975 SRT_BrkTm_L "0F00000000000000h";
BA_ "GenSigStartValue" SG_ 975 SRT_BrkTm_L 255;
BA_ "FlexKomSID" SG_ 975 SRT_BrkTm_L 1992;
BA_ "FlexKomSigStartPos" SG_ 975 SRT_BrkTm_L 7;
BA_ "FlexKomSigLaenge" SG_ 975 SRT_BrkTm_L 64;
BA_ "FlexKomSigName" SG_ 975 SRT_BrkTm_L "IC_SRT_PKT";
BA_ "FlexKomComment" SG_ 975 SRT_BrkTm_L "IC SRT packet";
BA_ "FlexKomIsMotorola" SG_ 975 SRT_BrkTm_L 1;
BA_ "GenSigSNA" SG_ 975 SRT_BrkTm_L "FFh";
BA_ "GenSigSendType" SG_ 975 SRT_eighthTmL 9;
BA_ "GenSigCycleTime" SG_ 975 SRT_eighthTmL 100;
BA_ "FlexKomSigStartValue" SG_ 975 SRT_eighthTmL "0F00000000000000h";
BA_ "GenSigStartValue" SG_ 975 SRT_eighthTmL 255;
BA_ "FlexKomSID" SG_ 975 SRT_eighthTmL 1992;
BA_ "FlexKomSigStartPos" SG_ 975 SRT_eighthTmL 7;
BA_ "FlexKomSigLaenge" SG_ 975 SRT_eighthTmL 64;
BA_ "FlexKomSigName" SG_ 975 SRT_eighthTmL "IC_SRT_PKT";
BA_ "FlexKomComment" SG_ 975 SRT_eighthTmL "IC SRT packet";
BA_ "FlexKomIsMotorola" SG_ 975 SRT_eighthTmL 1;
BA_ "GenSigSNA" SG_ 975 SRT_eighthTmL "FFh";
BA_ "GenSigSendType" SG_ 975 SRT_eighthTm_C 9;
BA_ "GenSigCycleTime" SG_ 975 SRT_eighthTm_C 100;
BA_ "FlexKomSigStartValue" SG_ 975 SRT_eighthTm_C "0F00000000000000h";
BA_ "GenSigStartValue" SG_ 975 SRT_eighthTm_C 255;
BA_ "FlexKomSID" SG_ 975 SRT_eighthTm_C 1992;
BA_ "FlexKomSigStartPos" SG_ 975 SRT_eighthTm_C 7;
BA_ "FlexKomSigLaenge" SG_ 975 SRT_eighthTm_C 64;
BA_ "FlexKomSigName" SG_ 975 SRT_eighthTm_C "IC_SRT_PKT";
BA_ "FlexKomComment" SG_ 975 SRT_eighthTm_C "IC SRT packet";
BA_ "FlexKomIsMotorola" SG_ 975 SRT_eighthTm_C 1;
BA_ "GenSigSNA" SG_ 975 SRT_eighthTm_C "FFh";
BA_ "GenSigSendType" SG_ 975 SRT_eighthTm_B 9;
BA_ "GenSigCycleTime" SG_ 975 SRT_eighthTm_B 100;
BA_ "FlexKomSigStartValue" SG_ 975 SRT_eighthTm_B "0F00000000000000h";
BA_ "GenSigStartValue" SG_ 975 SRT_eighthTm_B 255;
BA_ "FlexKomSID" SG_ 975 SRT_eighthTm_B 1992;
BA_ "FlexKomSigStartPos" SG_ 975 SRT_eighthTm_B 7;
BA_ "FlexKomSigLaenge" SG_ 975 SRT_eighthTm_B 64;
BA_ "FlexKomSigName" SG_ 975 SRT_eighthTm_B "IC_SRT_PKT";
BA_ "FlexKomComment" SG_ 975 SRT_eighthTm_B "IC SRT packet";
BA_ "FlexKomIsMotorola" SG_ 975 SRT_eighthTm_B 1;
BA_ "GenSigSNA" SG_ 975 SRT_eighthTm_B "FFh";
BA_ "GenSigSendType" SG_ 975 SRT_eighthTm_L 9;
BA_ "GenSigCycleTime" SG_ 975 SRT_eighthTm_L 100;
BA_ "FlexKomSigStartValue" SG_ 975 SRT_eighthTm_L "0F00000000000000h";
BA_ "GenSigStartValue" SG_ 975 SRT_eighthTm_L 255;
BA_ "FlexKomSID" SG_ 975 SRT_eighthTm_L 1992;
BA_ "FlexKomSigStartPos" SG_ 975 SRT_eighthTm_L 7;
BA_ "FlexKomSigLaenge" SG_ 975 SRT_eighthTm_L 64;
BA_ "FlexKomSigName" SG_ 975 SRT_eighthTm_L "IC_SRT_PKT";
BA_ "FlexKomComment" SG_ 975 SRT_eighthTm_L "IC SRT packet";
BA_ "FlexKomIsMotorola" SG_ 975 SRT_eighthTm_L 1;
BA_ "GenSigSNA" SG_ 975 SRT_eighthTm_L "FFh";
BA_ "GenSigSendType" SG_ 975 SRT_BrkTmC 9;
BA_ "GenSigCycleTime" SG_ 975 SRT_BrkTmC 100;
BA_ "FlexKomSigStartValue" SG_ 975 SRT_BrkTmC "0F00000000000000h";
BA_ "GenSigStartValue" SG_ 975 SRT_BrkTmC 255;
BA_ "FlexKomSID" SG_ 975 SRT_BrkTmC 1992;
BA_ "FlexKomSigStartPos" SG_ 975 SRT_BrkTmC 7;
BA_ "FlexKomSigLaenge" SG_ 975 SRT_BrkTmC 64;
BA_ "FlexKomSigName" SG_ 975 SRT_BrkTmC "IC_SRT_PKT";
BA_ "FlexKomComment" SG_ 975 SRT_BrkTmC "IC SRT packet";
BA_ "FlexKomIsMotorola" SG_ 975 SRT_BrkTmC 1;
BA_ "GenSigSNA" SG_ 975 SRT_BrkTmC "FFh";
BA_ "GenSigSendType" SG_ 975 SRT_BrkTmB 9;
BA_ "GenSigCycleTime" SG_ 975 SRT_BrkTmB 100;
BA_ "FlexKomSigStartValue" SG_ 975 SRT_BrkTmB "0F00000000000000h";
BA_ "GenSigStartValue" SG_ 975 SRT_BrkTmB 255;
BA_ "FlexKomSID" SG_ 975 SRT_BrkTmB 1992;
BA_ "FlexKomSigStartPos" SG_ 975 SRT_BrkTmB 7;
BA_ "FlexKomSigLaenge" SG_ 975 SRT_BrkTmB 64;
BA_ "FlexKomSigName" SG_ 975 SRT_BrkTmB "IC_SRT_PKT";
BA_ "FlexKomComment" SG_ 975 SRT_BrkTmB "IC SRT packet";
BA_ "FlexKomIsMotorola" SG_ 975 SRT_BrkTmB 1;
BA_ "GenSigSNA" SG_ 975 SRT_BrkTmB "FFh";
BA_ "GenSigSendType" SG_ 975 SRT_quarterTmC 9;
BA_ "GenSigCycleTime" SG_ 975 SRT_quarterTmC 100;
BA_ "FlexKomSigStartValue" SG_ 975 SRT_quarterTmC "0F00000000000000h";
BA_ "GenSigStartValue" SG_ 975 SRT_quarterTmC 255;
BA_ "FlexKomSID" SG_ 975 SRT_quarterTmC 1992;
BA_ "FlexKomSigStartPos" SG_ 975 SRT_quarterTmC 7;
BA_ "FlexKomSigLaenge" SG_ 975 SRT_quarterTmC 64;
BA_ "FlexKomSigName" SG_ 975 SRT_quarterTmC "IC_SRT_PKT";
BA_ "FlexKomComment" SG_ 975 SRT_quarterTmC "IC SRT packet";
BA_ "FlexKomIsMotorola" SG_ 975 SRT_quarterTmC 1;
BA_ "GenSigSNA" SG_ 975 SRT_quarterTmC "FFh";
BA_ "GenSigSendType" SG_ 975 SRT_quarterTmB 9;
BA_ "GenSigCycleTime" SG_ 975 SRT_quarterTmB 100;
BA_ "FlexKomSigStartValue" SG_ 975 SRT_quarterTmB "0F00000000000000h";
BA_ "GenSigStartValue" SG_ 975 SRT_quarterTmB 255;
BA_ "FlexKomSID" SG_ 975 SRT_quarterTmB 1992;
BA_ "FlexKomSigStartPos" SG_ 975 SRT_quarterTmB 7;
BA_ "FlexKomSigLaenge" SG_ 975 SRT_quarterTmB 64;
BA_ "FlexKomSigName" SG_ 975 SRT_quarterTmB "IC_SRT_PKT";
BA_ "FlexKomComment" SG_ 975 SRT_quarterTmB "IC SRT packet";
BA_ "FlexKomIsMotorola" SG_ 975 SRT_quarterTmB 1;
BA_ "GenSigSNA" SG_ 975 SRT_quarterTmB "FFh";
BA_ "GenSigSendType" SG_ 975 SRT_ReactTmL 9;
BA_ "GenSigCycleTime" SG_ 975 SRT_ReactTmL 100;
BA_ "FlexKomSigStartValue" SG_ 975 SRT_ReactTmL "0F00000000000000h";
BA_ "GenSigStartValue" SG_ 975 SRT_ReactTmL 255;
BA_ "FlexKomSID" SG_ 975 SRT_ReactTmL 1992;
BA_ "FlexKomSigStartPos" SG_ 975 SRT_ReactTmL 7;
BA_ "FlexKomSigLaenge" SG_ 975 SRT_ReactTmL 64;
BA_ "FlexKomSigName" SG_ 975 SRT_ReactTmL "IC_SRT_PKT";
BA_ "FlexKomComment" SG_ 975 SRT_ReactTmL "IC SRT packet";
BA_ "FlexKomIsMotorola" SG_ 975 SRT_ReactTmL 1;
BA_ "GenSigSNA" SG_ 975 SRT_ReactTmL "FFh";
BA_ "GenSigSendType" SG_ 975 SRT_quarterTmL 9;
BA_ "GenSigCycleTime" SG_ 975 SRT_quarterTmL 100;
BA_ "FlexKomSigStartValue" SG_ 975 SRT_quarterTmL "0F00000000000000h";
BA_ "GenSigStartValue" SG_ 975 SRT_quarterTmL 255;
BA_ "FlexKomSID" SG_ 975 SRT_quarterTmL 1992;
BA_ "FlexKomSigStartPos" SG_ 975 SRT_quarterTmL 7;
BA_ "FlexKomSigLaenge" SG_ 975 SRT_quarterTmL 64;
BA_ "FlexKomSigName" SG_ 975 SRT_quarterTmL "IC_SRT_PKT";
BA_ "FlexKomComment" SG_ 975 SRT_quarterTmL "IC SRT packet";
BA_ "FlexKomIsMotorola" SG_ 975 SRT_quarterTmL 1;
BA_ "GenSigSNA" SG_ 975 SRT_quarterTmL "FFh";
BA_ "GenSigSendType" SG_ 975 SRT_quarterTm_C 9;
BA_ "GenSigCycleTime" SG_ 975 SRT_quarterTm_C 100;
BA_ "FlexKomSigStartValue" SG_ 975 SRT_quarterTm_C "0F00000000000000h";
BA_ "GenSigStartValue" SG_ 975 SRT_quarterTm_C 255;
BA_ "FlexKomSID" SG_ 975 SRT_quarterTm_C 1992;
BA_ "FlexKomSigStartPos" SG_ 975 SRT_quarterTm_C 7;
BA_ "FlexKomSigLaenge" SG_ 975 SRT_quarterTm_C 64;
BA_ "FlexKomSigName" SG_ 975 SRT_quarterTm_C "IC_SRT_PKT";
BA_ "FlexKomComment" SG_ 975 SRT_quarterTm_C "IC SRT packet";
BA_ "FlexKomIsMotorola" SG_ 975 SRT_quarterTm_C 1;
BA_ "GenSigSNA" SG_ 975 SRT_quarterTm_C "FFh";
BA_ "GenSigSendType" SG_ 975 SRT_quarterTm_B 9;
BA_ "GenSigCycleTime" SG_ 975 SRT_quarterTm_B 100;
BA_ "FlexKomSigStartValue" SG_ 975 SRT_quarterTm_B "0F00000000000000h";
BA_ "GenSigStartValue" SG_ 975 SRT_quarterTm_B 255;
BA_ "FlexKomSID" SG_ 975 SRT_quarterTm_B 1992;
BA_ "FlexKomSigStartPos" SG_ 975 SRT_quarterTm_B 7;
BA_ "FlexKomSigLaenge" SG_ 975 SRT_quarterTm_B 64;
BA_ "FlexKomSigName" SG_ 975 SRT_quarterTm_B "IC_SRT_PKT";
BA_ "FlexKomComment" SG_ 975 SRT_quarterTm_B "IC SRT packet";
BA_ "FlexKomIsMotorola" SG_ 975 SRT_quarterTm_B 1;
BA_ "GenSigSNA" SG_ 975 SRT_quarterTm_B "FFh";
BA_ "GenSigSendType" SG_ 975 SRT_quarterTm_L 9;
BA_ "GenSigCycleTime" SG_ 975 SRT_quarterTm_L 100;
BA_ "FlexKomSigStartValue" SG_ 975 SRT_quarterTm_L "0F00000000000000h";
BA_ "GenSigStartValue" SG_ 975 SRT_quarterTm_L 255;
BA_ "FlexKomSID" SG_ 975 SRT_quarterTm_L 1992;
BA_ "FlexKomSigStartPos" SG_ 975 SRT_quarterTm_L 7;
BA_ "FlexKomSigLaenge" SG_ 975 SRT_quarterTm_L 64;
BA_ "FlexKomSigName" SG_ 975 SRT_quarterTm_L "IC_SRT_PKT";
BA_ "FlexKomComment" SG_ 975 SRT_quarterTm_L "IC SRT packet";
BA_ "FlexKomIsMotorola" SG_ 975 SRT_quarterTm_L 1;
BA_ "GenSigSNA" SG_ 975 SRT_quarterTm_L "FFh";
BA_ "GenSigSendType" SG_ 975 SRT_ReactTmC 9;
BA_ "GenSigCycleTime" SG_ 975 SRT_ReactTmC 100;
BA_ "FlexKomSigStartValue" SG_ 975 SRT_ReactTmC "0F00000000000000h";
BA_ "GenSigStartValue" SG_ 975 SRT_ReactTmC 255;
BA_ "FlexKomSID" SG_ 975 SRT_ReactTmC 1992;
BA_ "FlexKomSigStartPos" SG_ 975 SRT_ReactTmC 7;
BA_ "FlexKomSigLaenge" SG_ 975 SRT_ReactTmC 64;
BA_ "FlexKomSigName" SG_ 975 SRT_ReactTmC "IC_SRT_PKT";
BA_ "FlexKomComment" SG_ 975 SRT_ReactTmC "IC SRT packet";
BA_ "FlexKomIsMotorola" SG_ 975 SRT_ReactTmC 1;
BA_ "GenSigSNA" SG_ 975 SRT_ReactTmC "FFh";
BA_ "GenSigSendType" SG_ 975 SRT_ReactTmB 9;
BA_ "GenSigCycleTime" SG_ 975 SRT_ReactTmB 100;
BA_ "FlexKomSigStartValue" SG_ 975 SRT_ReactTmB "0F00000000000000h";
BA_ "GenSigStartValue" SG_ 975 SRT_ReactTmB 255;
BA_ "FlexKomSID" SG_ 975 SRT_ReactTmB 1992;
BA_ "FlexKomSigStartPos" SG_ 975 SRT_ReactTmB 7;
BA_ "FlexKomSigLaenge" SG_ 975 SRT_ReactTmB 64;
BA_ "FlexKomSigName" SG_ 975 SRT_ReactTmB "IC_SRT_PKT";
BA_ "FlexKomComment" SG_ 975 SRT_ReactTmB "IC SRT packet";
BA_ "FlexKomIsMotorola" SG_ 975 SRT_ReactTmB 1;
BA_ "GenSigSNA" SG_ 975 SRT_ReactTmB "FFh";
BA_ "GenSigSendType" SG_ 975 SRT_EthSpdC_M 9;
BA_ "GenSigCycleTime" SG_ 975 SRT_EthSpdC_M 100;
BA_ "FlexKomSigStartValue" SG_ 975 SRT_EthSpdC_M "0F00000000000000h";
BA_ "GenSigStartValue" SG_ 975 SRT_EthSpdC_M 255;
BA_ "FlexKomSID" SG_ 975 SRT_EthSpdC_M 1992;
BA_ "FlexKomSigStartPos" SG_ 975 SRT_EthSpdC_M 7;
BA_ "FlexKomSigLaenge" SG_ 975 SRT_EthSpdC_M 64;
BA_ "FlexKomSigName" SG_ 975 SRT_EthSpdC_M "IC_SRT_PKT";
BA_ "FlexKomComment" SG_ 975 SRT_EthSpdC_M "IC SRT packet";
BA_ "FlexKomIsMotorola" SG_ 975 SRT_EthSpdC_M 1;
BA_ "GenSigSNA" SG_ 975 SRT_EthSpdC_M "FFh";
BA_ "GenSigSendType" SG_ 975 SRT_EthSpdB_M 9;
BA_ "GenSigCycleTime" SG_ 975 SRT_EthSpdB_M 100;
BA_ "FlexKomSigStartValue" SG_ 975 SRT_EthSpdB_M "0F00000000000000h";
BA_ "GenSigStartValue" SG_ 975 SRT_EthSpdB_M 255;
BA_ "FlexKomSID" SG_ 975 SRT_EthSpdB_M 1992;
BA_ "FlexKomSigStartPos" SG_ 975 SRT_EthSpdB_M 7;
BA_ "FlexKomSigLaenge" SG_ 975 SRT_EthSpdB_M 64;
BA_ "FlexKomSigName" SG_ 975 SRT_EthSpdB_M "IC_SRT_PKT";
BA_ "FlexKomComment" SG_ 975 SRT_EthSpdB_M "IC SRT packet";
BA_ "FlexKomIsMotorola" SG_ 975 SRT_EthSpdB_M 1;
BA_ "GenSigSNA" SG_ 975 SRT_EthSpdB_M "FFh";
BA_ "GenSigSendType" SG_ 975 SRT_EthSpdL_M 9;
BA_ "GenSigCycleTime" SG_ 975 SRT_EthSpdL_M 100;
BA_ "FlexKomSigStartValue" SG_ 975 SRT_EthSpdL_M "0F00000000000000h";
BA_ "GenSigStartValue" SG_ 975 SRT_EthSpdL_M 255;
BA_ "FlexKomSID" SG_ 975 SRT_EthSpdL_M 1992;
BA_ "FlexKomSigStartPos" SG_ 975 SRT_EthSpdL_M 7;
BA_ "FlexKomSigLaenge" SG_ 975 SRT_EthSpdL_M 64;
BA_ "FlexKomSigName" SG_ 975 SRT_EthSpdL_M "IC_SRT_PKT";
BA_ "FlexKomComment" SG_ 975 SRT_EthSpdL_M "IC SRT packet";
BA_ "FlexKomIsMotorola" SG_ 975 SRT_EthSpdL_M 1;
BA_ "GenSigSNA" SG_ 975 SRT_EthSpdL_M "FFh";
BA_ "GenSigSendType" SG_ 975 SRT_EthSpdC_US 9;
BA_ "GenSigCycleTime" SG_ 975 SRT_EthSpdC_US 100;
BA_ "FlexKomSigStartValue" SG_ 975 SRT_EthSpdC_US "0F00000000000000h";
BA_ "GenSigStartValue" SG_ 975 SRT_EthSpdC_US 255;
BA_ "FlexKomSID" SG_ 975 SRT_EthSpdC_US 1992;
BA_ "FlexKomSigStartPos" SG_ 975 SRT_EthSpdC_US 7;
BA_ "FlexKomSigLaenge" SG_ 975 SRT_EthSpdC_US 64;
BA_ "FlexKomSigName" SG_ 975 SRT_EthSpdC_US "IC_SRT_PKT";
BA_ "FlexKomComment" SG_ 975 SRT_EthSpdC_US "IC SRT packet";
BA_ "FlexKomIsMotorola" SG_ 975 SRT_EthSpdC_US 1;
BA_ "GenSigSNA" SG_ 975 SRT_EthSpdC_US "FFh";
BA_ "GenSigSendType" SG_ 975 SRT_EthSpdB_US 9;
BA_ "GenSigCycleTime" SG_ 975 SRT_EthSpdB_US 100;
BA_ "FlexKomSigStartValue" SG_ 975 SRT_EthSpdB_US "0F00000000000000h";
BA_ "GenSigStartValue" SG_ 975 SRT_EthSpdB_US 255;
BA_ "FlexKomSID" SG_ 975 SRT_EthSpdB_US 1992;
BA_ "FlexKomSigStartPos" SG_ 975 SRT_EthSpdB_US 7;
BA_ "FlexKomSigLaenge" SG_ 975 SRT_EthSpdB_US 64;
BA_ "FlexKomSigName" SG_ 975 SRT_EthSpdB_US "IC_SRT_PKT";
BA_ "FlexKomComment" SG_ 975 SRT_EthSpdB_US "IC SRT packet";
BA_ "FlexKomIsMotorola" SG_ 975 SRT_EthSpdB_US 1;
BA_ "GenSigSNA" SG_ 975 SRT_EthSpdB_US "FFh";
BA_ "GenSigSendType" SG_ 975 SRT_EthSpdL_US 9;
BA_ "GenSigCycleTime" SG_ 975 SRT_EthSpdL_US 100;
BA_ "FlexKomSigStartValue" SG_ 975 SRT_EthSpdL_US "0F00000000000000h";
BA_ "GenSigStartValue" SG_ 975 SRT_EthSpdL_US 255;
BA_ "FlexKomSID" SG_ 975 SRT_EthSpdL_US 1992;
BA_ "FlexKomSigStartPos" SG_ 975 SRT_EthSpdL_US 7;
BA_ "FlexKomSigLaenge" SG_ 975 SRT_EthSpdL_US 64;
BA_ "FlexKomSigName" SG_ 975 SRT_EthSpdL_US "IC_SRT_PKT";
BA_ "FlexKomComment" SG_ 975 SRT_EthSpdL_US "IC SRT packet";
BA_ "FlexKomIsMotorola" SG_ 975 SRT_EthSpdL_US 1;
BA_ "GenSigSNA" SG_ 975 SRT_EthSpdL_US "FFh";
BA_ "GenSigSendType" SG_ 975 SRT_QrtSpdC_M 9;
BA_ "GenSigCycleTime" SG_ 975 SRT_QrtSpdC_M 100;
BA_ "FlexKomSigStartValue" SG_ 975 SRT_QrtSpdC_M "0F00000000000000h";
BA_ "GenSigStartValue" SG_ 975 SRT_QrtSpdC_M 255;
BA_ "FlexKomSID" SG_ 975 SRT_QrtSpdC_M 1992;
BA_ "FlexKomSigStartPos" SG_ 975 SRT_QrtSpdC_M 7;
BA_ "FlexKomSigLaenge" SG_ 975 SRT_QrtSpdC_M 64;
BA_ "FlexKomSigName" SG_ 975 SRT_QrtSpdC_M "IC_SRT_PKT";
BA_ "FlexKomComment" SG_ 975 SRT_QrtSpdC_M "IC SRT packet";
BA_ "FlexKomIsMotorola" SG_ 975 SRT_QrtSpdC_M 1;
BA_ "GenSigSNA" SG_ 975 SRT_QrtSpdC_M "FFh";
BA_ "GenSigSendType" SG_ 975 SRT_QrtSpdB_M 9;
BA_ "GenSigCycleTime" SG_ 975 SRT_QrtSpdB_M 100;
BA_ "FlexKomSigStartValue" SG_ 975 SRT_QrtSpdB_M "0F00000000000000h";
BA_ "GenSigStartValue" SG_ 975 SRT_QrtSpdB_M 255;
BA_ "FlexKomSID" SG_ 975 SRT_QrtSpdB_M 1992;
BA_ "FlexKomSigStartPos" SG_ 975 SRT_QrtSpdB_M 7;
BA_ "FlexKomSigLaenge" SG_ 975 SRT_QrtSpdB_M 64;
BA_ "FlexKomSigName" SG_ 975 SRT_QrtSpdB_M "IC_SRT_PKT";
BA_ "FlexKomComment" SG_ 975 SRT_QrtSpdB_M "IC SRT packet";
BA_ "FlexKomIsMotorola" SG_ 975 SRT_QrtSpdB_M 1;
BA_ "GenSigSNA" SG_ 975 SRT_QrtSpdB_M "FFh";
BA_ "GenSigSendType" SG_ 975 SRT_QrtSpdL_M 9;
BA_ "GenSigCycleTime" SG_ 975 SRT_QrtSpdL_M 100;
BA_ "FlexKomSigStartValue" SG_ 975 SRT_QrtSpdL_M "0F00000000000000h";
BA_ "GenSigStartValue" SG_ 975 SRT_QrtSpdL_M 255;
BA_ "FlexKomSID" SG_ 975 SRT_QrtSpdL_M 1992;
BA_ "FlexKomSigStartPos" SG_ 975 SRT_QrtSpdL_M 7;
BA_ "FlexKomSigLaenge" SG_ 975 SRT_QrtSpdL_M 64;
BA_ "FlexKomSigName" SG_ 975 SRT_QrtSpdL_M "IC_SRT_PKT";
BA_ "FlexKomComment" SG_ 975 SRT_QrtSpdL_M "IC SRT packet";
BA_ "FlexKomIsMotorola" SG_ 975 SRT_QrtSpdL_M 1;
BA_ "GenSigSNA" SG_ 975 SRT_QrtSpdL_M "FFh";
BA_ "GenSigSendType" SG_ 975 SRT_QrtSpdC_US 9;
BA_ "GenSigCycleTime" SG_ 975 SRT_QrtSpdC_US 100;
BA_ "FlexKomSigStartValue" SG_ 975 SRT_QrtSpdC_US "0F00000000000000h";
BA_ "GenSigStartValue" SG_ 975 SRT_QrtSpdC_US 255;
BA_ "FlexKomSID" SG_ 975 SRT_QrtSpdC_US 1992;
BA_ "FlexKomSigStartPos" SG_ 975 SRT_QrtSpdC_US 7;
BA_ "FlexKomSigLaenge" SG_ 975 SRT_QrtSpdC_US 64;
BA_ "FlexKomSigName" SG_ 975 SRT_QrtSpdC_US "IC_SRT_PKT";
BA_ "FlexKomComment" SG_ 975 SRT_QrtSpdC_US "IC SRT packet";
BA_ "FlexKomIsMotorola" SG_ 975 SRT_QrtSpdC_US 1;
BA_ "GenSigSNA" SG_ 975 SRT_QrtSpdC_US "FFh";
BA_ "GenSigSendType" SG_ 975 SRT_QrtSpdB_US 9;
BA_ "GenSigCycleTime" SG_ 975 SRT_QrtSpdB_US 100;
BA_ "FlexKomSigStartValue" SG_ 975 SRT_QrtSpdB_US "0F00000000000000h";
BA_ "GenSigStartValue" SG_ 975 SRT_QrtSpdB_US 255;
BA_ "FlexKomSID" SG_ 975 SRT_QrtSpdB_US 1992;
BA_ "FlexKomSigStartPos" SG_ 975 SRT_QrtSpdB_US 7;
BA_ "FlexKomSigLaenge" SG_ 975 SRT_QrtSpdB_US 64;
BA_ "FlexKomSigName" SG_ 975 SRT_QrtSpdB_US "IC_SRT_PKT";
BA_ "FlexKomComment" SG_ 975 SRT_QrtSpdB_US "IC SRT packet";
BA_ "FlexKomIsMotorola" SG_ 975 SRT_QrtSpdB_US 1;
BA_ "GenSigSNA" SG_ 975 SRT_QrtSpdB_US "FFh";
BA_ "GenSigSendType" SG_ 975 SRT_QrtSpdL_US 9;
BA_ "GenSigCycleTime" SG_ 975 SRT_QrtSpdL_US 100;
BA_ "FlexKomSigStartValue" SG_ 975 SRT_QrtSpdL_US "0F00000000000000h";
BA_ "GenSigStartValue" SG_ 975 SRT_QrtSpdL_US 255;
BA_ "FlexKomSID" SG_ 975 SRT_QrtSpdL_US 1992;
BA_ "FlexKomSigStartPos" SG_ 975 SRT_QrtSpdL_US 7;
BA_ "FlexKomSigLaenge" SG_ 975 SRT_QrtSpdL_US 64;
BA_ "FlexKomSigName" SG_ 975 SRT_QrtSpdL_US "IC_SRT_PKT";
BA_ "FlexKomComment" SG_ 975 SRT_QrtSpdL_US "IC SRT packet";
BA_ "FlexKomIsMotorola" SG_ 975 SRT_QrtSpdL_US 1;
BA_ "GenSigSNA" SG_ 975 SRT_QrtSpdL_US "FFh";
BA_ "GenSigSendType" SG_ 975 SRT_BrkSpdC_M 9;
BA_ "GenSigCycleTime" SG_ 975 SRT_BrkSpdC_M 100;
BA_ "FlexKomSigStartValue" SG_ 975 SRT_BrkSpdC_M "0F00000000000000h";
BA_ "GenSigStartValue" SG_ 975 SRT_BrkSpdC_M 255;
BA_ "FlexKomSID" SG_ 975 SRT_BrkSpdC_M 1992;
BA_ "FlexKomSigStartPos" SG_ 975 SRT_BrkSpdC_M 7;
BA_ "FlexKomSigLaenge" SG_ 975 SRT_BrkSpdC_M 64;
BA_ "FlexKomSigName" SG_ 975 SRT_BrkSpdC_M "IC_SRT_PKT";
BA_ "FlexKomComment" SG_ 975 SRT_BrkSpdC_M "IC SRT packet";
BA_ "FlexKomIsMotorola" SG_ 975 SRT_BrkSpdC_M 1;
BA_ "GenSigSNA" SG_ 975 SRT_BrkSpdC_M "FFh";
BA_ "GenSigSendType" SG_ 975 SRT_BrkSpdB_M 9;
BA_ "GenSigCycleTime" SG_ 975 SRT_BrkSpdB_M 100;
BA_ "FlexKomSigStartValue" SG_ 975 SRT_BrkSpdB_M "0F00000000000000h";
BA_ "GenSigStartValue" SG_ 975 SRT_BrkSpdB_M 255;
BA_ "FlexKomSID" SG_ 975 SRT_BrkSpdB_M 1992;
BA_ "FlexKomSigStartPos" SG_ 975 SRT_BrkSpdB_M 7;
BA_ "FlexKomSigLaenge" SG_ 975 SRT_BrkSpdB_M 64;
BA_ "FlexKomSigName" SG_ 975 SRT_BrkSpdB_M "IC_SRT_PKT";
BA_ "FlexKomComment" SG_ 975 SRT_BrkSpdB_M "IC SRT packet";
BA_ "FlexKomIsMotorola" SG_ 975 SRT_BrkSpdB_M 1;
BA_ "GenSigSNA" SG_ 975 SRT_BrkSpdB_M "FFh";
BA_ "GenSigSendType" SG_ 975 SRT_BrkSpdL_M 9;
BA_ "GenSigCycleTime" SG_ 975 SRT_BrkSpdL_M 100;
BA_ "FlexKomSigStartValue" SG_ 975 SRT_BrkSpdL_M "0F00000000000000h";
BA_ "GenSigStartValue" SG_ 975 SRT_BrkSpdL_M 255;
BA_ "FlexKomSID" SG_ 975 SRT_BrkSpdL_M 1992;
BA_ "FlexKomSigStartPos" SG_ 975 SRT_BrkSpdL_M 7;
BA_ "FlexKomSigLaenge" SG_ 975 SRT_BrkSpdL_M 64;
BA_ "FlexKomSigName" SG_ 975 SRT_BrkSpdL_M "IC_SRT_PKT";
BA_ "FlexKomComment" SG_ 975 SRT_BrkSpdL_M "IC SRT packet";
BA_ "FlexKomIsMotorola" SG_ 975 SRT_BrkSpdL_M 1;
BA_ "GenSigSNA" SG_ 975 SRT_BrkSpdL_M "FFh";
BA_ "GenSigSendType" SG_ 975 SRT_BrkSpdC_US 9;
BA_ "GenSigCycleTime" SG_ 975 SRT_BrkSpdC_US 100;
BA_ "FlexKomSigStartValue" SG_ 975 SRT_BrkSpdC_US "0F00000000000000h";
BA_ "GenSigStartValue" SG_ 975 SRT_BrkSpdC_US 255;
BA_ "FlexKomSID" SG_ 975 SRT_BrkSpdC_US 1992;
BA_ "FlexKomSigStartPos" SG_ 975 SRT_BrkSpdC_US 7;
BA_ "FlexKomSigLaenge" SG_ 975 SRT_BrkSpdC_US 64;
BA_ "FlexKomSigName" SG_ 975 SRT_BrkSpdC_US "IC_SRT_PKT";
BA_ "FlexKomComment" SG_ 975 SRT_BrkSpdC_US "IC SRT packet";
BA_ "FlexKomIsMotorola" SG_ 975 SRT_BrkSpdC_US 1;
BA_ "GenSigSNA" SG_ 975 SRT_BrkSpdC_US "FFh";
BA_ "GenSigSendType" SG_ 975 SRT_BrkSpdB_US 9;
BA_ "GenSigCycleTime" SG_ 975 SRT_BrkSpdB_US 100;
BA_ "FlexKomSigStartValue" SG_ 975 SRT_BrkSpdB_US "0F00000000000000h";
BA_ "GenSigStartValue" SG_ 975 SRT_BrkSpdB_US 255;
BA_ "FlexKomSID" SG_ 975 SRT_BrkSpdB_US 1992;
BA_ "FlexKomSigStartPos" SG_ 975 SRT_BrkSpdB_US 7;
BA_ "FlexKomSigLaenge" SG_ 975 SRT_BrkSpdB_US 64;
BA_ "FlexKomSigName" SG_ 975 SRT_BrkSpdB_US "IC_SRT_PKT";
BA_ "FlexKomComment" SG_ 975 SRT_BrkSpdB_US "IC SRT packet";
BA_ "FlexKomIsMotorola" SG_ 975 SRT_BrkSpdB_US 1;
BA_ "GenSigSNA" SG_ 975 SRT_BrkSpdB_US "FFh";
BA_ "GenSigSendType" SG_ 975 SRT_BrkSpdL_US 9;
BA_ "GenSigCycleTime" SG_ 975 SRT_BrkSpdL_US 100;
BA_ "FlexKomSigStartValue" SG_ 975 SRT_BrkSpdL_US "0F00000000000000h";
BA_ "GenSigStartValue" SG_ 975 SRT_BrkSpdL_US 255;
BA_ "FlexKomSID" SG_ 975 SRT_BrkSpdL_US 1992;
BA_ "FlexKomSigStartPos" SG_ 975 SRT_BrkSpdL_US 7;
BA_ "FlexKomSigLaenge" SG_ 975 SRT_BrkSpdL_US 64;
BA_ "FlexKomSigName" SG_ 975 SRT_BrkSpdL_US "IC_SRT_PKT";
BA_ "FlexKomComment" SG_ 975 SRT_BrkSpdL_US "IC SRT packet";
BA_ "FlexKomIsMotorola" SG_ 975 SRT_BrkSpdL_US 1;
BA_ "GenSigSNA" SG_ 975 SRT_BrkSpdL_US "FFh";
BA_ "GenSigSendType" SG_ 975 SRT_BrkDistC_M 9;
BA_ "GenSigCycleTime" SG_ 975 SRT_BrkDistC_M 100;
BA_ "FlexKomSigStartValue" SG_ 975 SRT_BrkDistC_M "0F00000000000000h";
BA_ "GenSigStartValue" SG_ 975 SRT_BrkDistC_M 255;
BA_ "FlexKomSID" SG_ 975 SRT_BrkDistC_M 1992;
BA_ "FlexKomSigStartPos" SG_ 975 SRT_BrkDistC_M 7;
BA_ "FlexKomSigLaenge" SG_ 975 SRT_BrkDistC_M 64;
BA_ "FlexKomSigName" SG_ 975 SRT_BrkDistC_M "IC_SRT_PKT";
BA_ "FlexKomComment" SG_ 975 SRT_BrkDistC_M "IC SRT packet";
BA_ "FlexKomIsMotorola" SG_ 975 SRT_BrkDistC_M 1;
BA_ "GenSigSNA" SG_ 975 SRT_BrkDistC_M "FFh";
BA_ "GenSigSendType" SG_ 975 SRT_BrkDistB_M 9;
BA_ "GenSigCycleTime" SG_ 975 SRT_BrkDistB_M 100;
BA_ "FlexKomSigStartValue" SG_ 975 SRT_BrkDistB_M "0F00000000000000h";
BA_ "GenSigStartValue" SG_ 975 SRT_BrkDistB_M 255;
BA_ "FlexKomSID" SG_ 975 SRT_BrkDistB_M 1992;
BA_ "FlexKomSigStartPos" SG_ 975 SRT_BrkDistB_M 7;
BA_ "FlexKomSigLaenge" SG_ 975 SRT_BrkDistB_M 64;
BA_ "FlexKomSigName" SG_ 975 SRT_BrkDistB_M "IC_SRT_PKT";
BA_ "FlexKomComment" SG_ 975 SRT_BrkDistB_M "IC SRT packet";
BA_ "FlexKomIsMotorola" SG_ 975 SRT_BrkDistB_M 1;
BA_ "GenSigSNA" SG_ 975 SRT_BrkDistB_M "FFh";
BA_ "GenSigSendType" SG_ 975 SRT_BrkDistL_M 9;
BA_ "GenSigCycleTime" SG_ 975 SRT_BrkDistL_M 100;
BA_ "FlexKomSigStartValue" SG_ 975 SRT_BrkDistL_M "0F00000000000000h";
BA_ "GenSigStartValue" SG_ 975 SRT_BrkDistL_M 255;
BA_ "FlexKomSID" SG_ 975 SRT_BrkDistL_M 1992;
BA_ "FlexKomSigStartPos" SG_ 975 SRT_BrkDistL_M 7;
BA_ "FlexKomSigLaenge" SG_ 975 SRT_BrkDistL_M 64;
BA_ "FlexKomSigName" SG_ 975 SRT_BrkDistL_M "IC_SRT_PKT";
BA_ "FlexKomComment" SG_ 975 SRT_BrkDistL_M "IC SRT packet";
BA_ "FlexKomIsMotorola" SG_ 975 SRT_BrkDistL_M 1;
BA_ "GenSigSNA" SG_ 975 SRT_BrkDistL_M "FFh";
BA_ "GenSigSendType" SG_ 975 SRT_BrkDistC_US 9;
BA_ "GenSigCycleTime" SG_ 975 SRT_BrkDistC_US 100;
BA_ "FlexKomSigStartValue" SG_ 975 SRT_BrkDistC_US "0F00000000000000h";
BA_ "GenSigStartValue" SG_ 975 SRT_BrkDistC_US 255;
BA_ "FlexKomSID" SG_ 975 SRT_BrkDistC_US 1992;
BA_ "FlexKomSigStartPos" SG_ 975 SRT_BrkDistC_US 7;
BA_ "FlexKomSigLaenge" SG_ 975 SRT_BrkDistC_US 64;
BA_ "FlexKomSigName" SG_ 975 SRT_BrkDistC_US "IC_SRT_PKT";
BA_ "FlexKomComment" SG_ 975 SRT_BrkDistC_US "IC SRT packet";
BA_ "FlexKomIsMotorola" SG_ 975 SRT_BrkDistC_US 1;
BA_ "GenSigSNA" SG_ 975 SRT_BrkDistC_US "FFh";
BA_ "GenSigSendType" SG_ 975 SRT_BrkDistB_US 9;
BA_ "GenSigCycleTime" SG_ 975 SRT_BrkDistB_US 100;
BA_ "FlexKomSigStartValue" SG_ 975 SRT_BrkDistB_US "0F00000000000000h";
BA_ "GenSigStartValue" SG_ 975 SRT_BrkDistB_US 255;
BA_ "FlexKomSID" SG_ 975 SRT_BrkDistB_US 1992;
BA_ "FlexKomSigStartPos" SG_ 975 SRT_BrkDistB_US 7;
BA_ "FlexKomSigLaenge" SG_ 975 SRT_BrkDistB_US 64;
BA_ "FlexKomSigName" SG_ 975 SRT_BrkDistB_US "IC_SRT_PKT";
BA_ "FlexKomComment" SG_ 975 SRT_BrkDistB_US "IC SRT packet";
BA_ "FlexKomIsMotorola" SG_ 975 SRT_BrkDistB_US 1;
BA_ "GenSigSNA" SG_ 975 SRT_BrkDistB_US "FFh";
BA_ "GenSigSendType" SG_ 975 SRT_BrkDistL_US 9;
BA_ "GenSigCycleTime" SG_ 975 SRT_BrkDistL_US 100;
BA_ "FlexKomSigStartValue" SG_ 975 SRT_BrkDistL_US "0F00000000000000h";
BA_ "GenSigStartValue" SG_ 975 SRT_BrkDistL_US 255;
BA_ "FlexKomSID" SG_ 975 SRT_BrkDistL_US 1992;
BA_ "FlexKomSigStartPos" SG_ 975 SRT_BrkDistL_US 7;
BA_ "FlexKomSigLaenge" SG_ 975 SRT_BrkDistL_US 64;
BA_ "FlexKomSigName" SG_ 975 SRT_BrkDistL_US "IC_SRT_PKT";
BA_ "FlexKomComment" SG_ 975 SRT_BrkDistL_US "IC SRT packet";
BA_ "FlexKomIsMotorola" SG_ 975 SRT_BrkDistL_US 1;
BA_ "GenSigSNA" SG_ 975 SRT_BrkDistL_US "FFh";
BA_ "GenSigCycleTime" SG_ 977 TransTyp 500;
BA_ "FlexKomSigStartValue" SG_ 977 TransTyp "FF000000h";
BA_ "GenSigStartValue" SG_ 977 TransTyp 255;
BA_ "GenSigTimeout_RF_HUB" SG_ 977 TransTyp 5250;
BA_ "GenSigTimeout_CBC" SG_ 977 TransTyp 5250;
BA_ "GenSigTimeout_ESC" SG_ 977 TransTyp 5250;
BA_ "FlexKomSID" SG_ 977 TransTyp 1414;
BA_ "FlexKomSigStartPos" SG_ 977 TransTyp 7;
BA_ "FlexKomSigLaenge" SG_ 977 TransTyp 32;
BA_ "FlexKomSigName" SG_ 977 TransTyp "TCM_CFG_PKT";
BA_ "FlexKomComment" SG_ 977 TransTyp "Transmission configuration packet";
BA_ "FlexKomIsMotorola" SG_ 977 TransTyp 1;
BA_ "GenSigSNA" SG_ 977 TransTyp "FFh";
BA_ "GenSigCycleTime" SG_ 979 EC_ECUCfg14_Stat 2000;
BA_ "FlexKomSigStartValue" SG_ 979 EC_ECUCfg14_Stat "03h";
BA_ "GenSigStartValue" SG_ 979 EC_ECUCfg14_Stat 3;
BA_ "FlexKomSID" SG_ 979 EC_ECUCfg14_Stat 1950;
BA_ "FlexKomSigStartPos" SG_ 979 EC_ECUCfg14_Stat 1;
BA_ "FlexKomSigLaenge" SG_ 979 EC_ECUCfg14_Stat 2;
BA_ "FlexKomSigName" SG_ 979 EC_ECUCfg14_Stat "EC_ECUCfg14_Stat";
BA_ "FlexKomComment" SG_ 979 EC_ECUCfg14_Stat "ECU Configuration messages status 14";
BA_ "FlexKomIsMotorola" SG_ 979 EC_ECUCfg14_Stat 1;
BA_ "GenSigSNA" SG_ 979 EC_ECUCfg14_Stat "3h";
BA_ "GenSigCycleTime" SG_ 979 EC_CBC14A 2000;
BA_ "FlexKomSigStartValue" SG_ 979 EC_CBC14A "0000000000000000h";
BA_ "FlexKomSID" SG_ 979 EC_CBC14A 1951;
BA_ "FlexKomSigStartPos" SG_ 979 EC_CBC14A 7;
BA_ "FlexKomSigLaenge" SG_ 979 EC_CBC14A 64;
BA_ "FlexKomSigName" SG_ 979 EC_CBC14A "EC_CBC14";
BA_ "FlexKomComment" SG_ 979 EC_CBC14A "CBC ecu configuration 14";
BA_ "FlexKomIsMotorola" SG_ 979 EC_CBC14A 1;
BA_ "GenSigSNA" SG_ 979 EC_CBC14A "0h";
BA_ "GenSigCycleTime" SG_ 979 EC_CBC14B 2000;
BA_ "FlexKomSigStartValue" SG_ 979 EC_CBC14B "0000000000000000h";
BA_ "FlexKomSID" SG_ 979 EC_CBC14B 1951;
BA_ "FlexKomSigStartPos" SG_ 979 EC_CBC14B 7;
BA_ "FlexKomSigLaenge" SG_ 979 EC_CBC14B 64;
BA_ "FlexKomSigName" SG_ 979 EC_CBC14B "EC_CBC14";
BA_ "FlexKomComment" SG_ 979 EC_CBC14B "CBC ecu configuration 14";
BA_ "FlexKomIsMotorola" SG_ 979 EC_CBC14B 1;
BA_ "GenSigSNA" SG_ 979 EC_CBC14B "0h";
BA_ "GenSigCycleTime" SG_ 980 EC_ECUCfg13_Stat 2000;
BA_ "FlexKomSigStartValue" SG_ 980 EC_ECUCfg13_Stat "03h";
BA_ "GenSigStartValue" SG_ 980 EC_ECUCfg13_Stat 3;
BA_ "FlexKomSID" SG_ 980 EC_ECUCfg13_Stat 1868;
BA_ "FlexKomSigStartPos" SG_ 980 EC_ECUCfg13_Stat 1;
BA_ "FlexKomSigLaenge" SG_ 980 EC_ECUCfg13_Stat 2;
BA_ "FlexKomSigName" SG_ 980 EC_ECUCfg13_Stat "EC_ECUCfg13_Stat";
BA_ "FlexKomComment" SG_ 980 EC_ECUCfg13_Stat "ECU Configuration messages status 13";
BA_ "FlexKomIsMotorola" SG_ 980 EC_ECUCfg13_Stat 1;
BA_ "GenSigSNA" SG_ 980 EC_ECUCfg13_Stat "3h";
BA_ "GenSigCycleTime" SG_ 980 EC_CBC13A 2000;
BA_ "FlexKomSigStartValue" SG_ 980 EC_CBC13A "0000000000000000h";
BA_ "FlexKomSID" SG_ 980 EC_CBC13A 1990;
BA_ "FlexKomSigStartPos" SG_ 980 EC_CBC13A 7;
BA_ "FlexKomSigLaenge" SG_ 980 EC_CBC13A 64;
BA_ "FlexKomSigName" SG_ 980 EC_CBC13A "EC_CBC13";
BA_ "FlexKomComment" SG_ 980 EC_CBC13A "CBC ecu configuration 13";
BA_ "FlexKomIsMotorola" SG_ 980 EC_CBC13A 1;
BA_ "GenSigSNA" SG_ 980 EC_CBC13A "0h";
BA_ "GenSigCycleTime" SG_ 980 EC_CBC13B 2000;
BA_ "FlexKomSigStartValue" SG_ 980 EC_CBC13B "0000000000000000h";
BA_ "FlexKomSID" SG_ 980 EC_CBC13B 1990;
BA_ "FlexKomSigStartPos" SG_ 980 EC_CBC13B 7;
BA_ "FlexKomSigLaenge" SG_ 980 EC_CBC13B 64;
BA_ "FlexKomSigName" SG_ 980 EC_CBC13B "EC_CBC13";
BA_ "FlexKomComment" SG_ 980 EC_CBC13B "CBC ecu configuration 13";
BA_ "FlexKomIsMotorola" SG_ 980 EC_CBC13B 1;
BA_ "GenSigSNA" SG_ 980 EC_CBC13B "0h";
BA_ "GenSigSendType" SG_ 981 EC_ECUCfg12_Stat 5;
BA_ "GenSigCycleTime" SG_ 981 EC_ECUCfg12_Stat 2000;
BA_ "FlexKomSigStartValue" SG_ 981 EC_ECUCfg12_Stat "03h";
BA_ "GenSigStartValue" SG_ 981 EC_ECUCfg12_Stat 3;
BA_ "GenSigTimeout_RF_HUB" SG_ 981 EC_ECUCfg12_Stat 21000;
BA_ "GenSigTimeout_IC" SG_ 981 EC_ECUCfg12_Stat 21000;
BA_ "FlexKomSID" SG_ 981 EC_ECUCfg12_Stat 1834;
BA_ "FlexKomSigStartPos" SG_ 981 EC_ECUCfg12_Stat 1;
BA_ "FlexKomSigLaenge" SG_ 981 EC_ECUCfg12_Stat 2;
BA_ "FlexKomSigName" SG_ 981 EC_ECUCfg12_Stat "EC_ECUCfg12_Stat";
BA_ "FlexKomComment" SG_ 981 EC_ECUCfg12_Stat "ECU Configuration messages status 12";
BA_ "FlexKomIsMotorola" SG_ 981 EC_ECUCfg12_Stat 1;
BA_ "GenSigSNA" SG_ 981 EC_ECUCfg12_Stat "3h";
BA_ "GenSigSendType" SG_ 981 EC_Cluster5A 5;
BA_ "GenSigCycleTime" SG_ 981 EC_Cluster5A 2000;
BA_ "FlexKomSigStartValue" SG_ 981 EC_Cluster5A "0000000000000000h";
BA_ "GenSigTimeout_RF_HUB" SG_ 981 EC_Cluster5A 21000;
BA_ "GenSigTimeout_IC" SG_ 981 EC_Cluster5A 21000;
BA_ "FlexKomSID" SG_ 981 EC_Cluster5A 1835;
BA_ "FlexKomSigStartPos" SG_ 981 EC_Cluster5A 7;
BA_ "FlexKomSigLaenge" SG_ 981 EC_Cluster5A 64;
BA_ "FlexKomSigName" SG_ 981 EC_Cluster5A "EC_Cluster5";
BA_ "FlexKomComment" SG_ 981 EC_Cluster5A "Instrument cluster ecu configuration 5";
BA_ "FlexKomIsMotorola" SG_ 981 EC_Cluster5A 1;
BA_ "GenSigSNA" SG_ 981 EC_Cluster5A "0h";
BA_ "GenSigSendType" SG_ 981 EC_Cluster5B 5;
BA_ "GenSigCycleTime" SG_ 981 EC_Cluster5B 2000;
BA_ "FlexKomSigStartValue" SG_ 981 EC_Cluster5B "0000000000000000h";
BA_ "GenSigTimeout_RF_HUB" SG_ 981 EC_Cluster5B 21000;
BA_ "GenSigTimeout_IC" SG_ 981 EC_Cluster5B 21000;
BA_ "FlexKomSID" SG_ 981 EC_Cluster5B 1835;
BA_ "FlexKomSigStartPos" SG_ 981 EC_Cluster5B 7;
BA_ "FlexKomSigLaenge" SG_ 981 EC_Cluster5B 64;
BA_ "FlexKomSigName" SG_ 981 EC_Cluster5B "EC_Cluster5";
BA_ "FlexKomComment" SG_ 981 EC_Cluster5B "Instrument cluster ecu configuration 5";
BA_ "FlexKomIsMotorola" SG_ 981 EC_Cluster5B 1;
BA_ "GenSigSNA" SG_ 981 EC_Cluster5B "0h";
BA_ "GenSigSendType" SG_ 981 EC_Cluster5C 5;
BA_ "GenSigCycleTime" SG_ 981 EC_Cluster5C 2000;
BA_ "FlexKomSigStartValue" SG_ 981 EC_Cluster5C "0000000000000000h";
BA_ "GenSigTimeout_RF_HUB" SG_ 981 EC_Cluster5C 21000;
BA_ "GenSigTimeout_IC" SG_ 981 EC_Cluster5C 21000;
BA_ "FlexKomSID" SG_ 981 EC_Cluster5C 1835;
BA_ "FlexKomSigStartPos" SG_ 981 EC_Cluster5C 7;
BA_ "FlexKomSigLaenge" SG_ 981 EC_Cluster5C 64;
BA_ "FlexKomSigName" SG_ 981 EC_Cluster5C "EC_Cluster5";
BA_ "FlexKomComment" SG_ 981 EC_Cluster5C "Instrument cluster ecu configuration 5";
BA_ "FlexKomIsMotorola" SG_ 981 EC_Cluster5C 1;
BA_ "GenSigSNA" SG_ 981 EC_Cluster5C "0h";
BA_ "GenSigCycleTime" SG_ 982 EC_ECUCfg11_Stat 2000;
BA_ "FlexKomSigStartValue" SG_ 982 EC_ECUCfg11_Stat "03h";
BA_ "GenSigStartValue" SG_ 982 EC_ECUCfg11_Stat 3;
BA_ "FlexKomSID" SG_ 982 EC_ECUCfg11_Stat 1708;
BA_ "FlexKomSigStartPos" SG_ 982 EC_ECUCfg11_Stat 1;
BA_ "FlexKomSigLaenge" SG_ 982 EC_ECUCfg11_Stat 2;
BA_ "FlexKomSigName" SG_ 982 EC_ECUCfg11_Stat "EC_ECUCfg11_Stat";
BA_ "FlexKomComment" SG_ 982 EC_ECUCfg11_Stat "ECU Configuration messages status 11";
BA_ "FlexKomIsMotorola" SG_ 982 EC_ECUCfg11_Stat 1;
BA_ "GenSigSNA" SG_ 982 EC_ECUCfg11_Stat "3h";
BA_ "GenSigCycleTime" SG_ 982 EC_CBC10A 2000;
BA_ "FlexKomSigStartValue" SG_ 982 EC_CBC10A "00000000h";
BA_ "FlexKomSID" SG_ 982 EC_CBC10A 1709;
BA_ "FlexKomSigStartPos" SG_ 982 EC_CBC10A 7;
BA_ "FlexKomSigLaenge" SG_ 982 EC_CBC10A 32;
BA_ "FlexKomSigName" SG_ 982 EC_CBC10A "EC_CBC10";
BA_ "FlexKomComment" SG_ 982 EC_CBC10A "CBC ecu configuration 10";
BA_ "FlexKomIsMotorola" SG_ 982 EC_CBC10A 1;
BA_ "GenSigSNA" SG_ 982 EC_CBC10A "0h";
BA_ "GenSigCycleTime" SG_ 982 EC_CBC10B 2000;
BA_ "FlexKomSigStartValue" SG_ 982 EC_CBC10B "00000000h";
BA_ "FlexKomSID" SG_ 982 EC_CBC10B 1709;
BA_ "FlexKomSigStartPos" SG_ 982 EC_CBC10B 7;
BA_ "FlexKomSigLaenge" SG_ 982 EC_CBC10B 32;
BA_ "FlexKomSigName" SG_ 982 EC_CBC10B "EC_CBC10";
BA_ "FlexKomComment" SG_ 982 EC_CBC10B "CBC ecu configuration 10";
BA_ "FlexKomIsMotorola" SG_ 982 EC_CBC10B 1;
BA_ "GenSigSNA" SG_ 982 EC_CBC10B "0h";
BA_ "GenSigCycleTime" SG_ 982 EC_CBC11 2000;
BA_ "FlexKomSigStartValue" SG_ 982 EC_CBC11 "00000000h";
BA_ "FlexKomSID" SG_ 982 EC_CBC11 1710;
BA_ "FlexKomSigStartPos" SG_ 982 EC_CBC11 39;
BA_ "FlexKomSigLaenge" SG_ 982 EC_CBC11 32;
BA_ "FlexKomSigName" SG_ 982 EC_CBC11 "EC_CBC11";
BA_ "FlexKomComment" SG_ 982 EC_CBC11 "CBC ecu configuration 11";
BA_ "FlexKomIsMotorola" SG_ 982 EC_CBC11 1;
BA_ "GenSigSNA" SG_ 982 EC_CBC11 "0h";
BA_ "GenSigSendType" SG_ 983 EC_ECUCfg10_Stat 5;
BA_ "GenSigCycleTime" SG_ 983 EC_ECUCfg10_Stat 2000;
BA_ "FlexKomSigStartValue" SG_ 983 EC_ECUCfg10_Stat "03h";
BA_ "GenSigStartValue" SG_ 983 EC_ECUCfg10_Stat 3;
BA_ "GenSigTimeout_IC" SG_ 983 EC_ECUCfg10_Stat 21000;
BA_ "FlexKomSID" SG_ 983 EC_ECUCfg10_Stat 1303;
BA_ "FlexKomSigStartPos" SG_ 983 EC_ECUCfg10_Stat 1;
BA_ "FlexKomSigLaenge" SG_ 983 EC_ECUCfg10_Stat 2;
BA_ "FlexKomSigName" SG_ 983 EC_ECUCfg10_Stat "EC_ECUCfg10_Stat";
BA_ "FlexKomComment" SG_ 983 EC_ECUCfg10_Stat "ECU Configuration messages status 10";
BA_ "FlexKomIsMotorola" SG_ 983 EC_ECUCfg10_Stat 1;
BA_ "GenSigSNA" SG_ 983 EC_ECUCfg10_Stat "3h";
BA_ "GenSigSendType" SG_ 983 EC_Cluster3A 5;
BA_ "GenSigCycleTime" SG_ 983 EC_Cluster3A 2000;
BA_ "FlexKomSigStartValue" SG_ 983 EC_Cluster3A "00000000h";
BA_ "GenSigTimeout_IC" SG_ 983 EC_Cluster3A 21000;
BA_ "FlexKomSID" SG_ 983 EC_Cluster3A 1307;
BA_ "FlexKomSigStartPos" SG_ 983 EC_Cluster3A 7;
BA_ "FlexKomSigLaenge" SG_ 983 EC_Cluster3A 32;
BA_ "FlexKomSigName" SG_ 983 EC_Cluster3A "EC_Cluster3";
BA_ "FlexKomComment" SG_ 983 EC_Cluster3A "Instrument cluster ecu configuration 3";
BA_ "FlexKomIsMotorola" SG_ 983 EC_Cluster3A 1;
BA_ "GenSigSNA" SG_ 983 EC_Cluster3A "0h";
BA_ "GenSigSendType" SG_ 983 EC_Cluster3B 5;
BA_ "GenSigCycleTime" SG_ 983 EC_Cluster3B 2000;
BA_ "FlexKomSigStartValue" SG_ 983 EC_Cluster3B "00000000h";
BA_ "GenSigTimeout_IC" SG_ 983 EC_Cluster3B 21000;
BA_ "FlexKomSID" SG_ 983 EC_Cluster3B 1307;
BA_ "FlexKomSigStartPos" SG_ 983 EC_Cluster3B 7;
BA_ "FlexKomSigLaenge" SG_ 983 EC_Cluster3B 32;
BA_ "FlexKomSigName" SG_ 983 EC_Cluster3B "EC_Cluster3";
BA_ "FlexKomComment" SG_ 983 EC_Cluster3B "Instrument cluster ecu configuration 3";
BA_ "FlexKomIsMotorola" SG_ 983 EC_Cluster3B 1;
BA_ "GenSigSNA" SG_ 983 EC_Cluster3B "0h";
BA_ "GenSigSendType" SG_ 983 EC_Cluster4 5;
BA_ "GenSigCycleTime" SG_ 983 EC_Cluster4 2000;
BA_ "FlexKomSigStartValue" SG_ 983 EC_Cluster4 "00000000h";
BA_ "GenSigTimeout_IC" SG_ 983 EC_Cluster4 21000;
BA_ "FlexKomSID" SG_ 983 EC_Cluster4 1306;
BA_ "FlexKomSigStartPos" SG_ 983 EC_Cluster4 39;
BA_ "FlexKomSigLaenge" SG_ 983 EC_Cluster4 32;
BA_ "FlexKomSigName" SG_ 983 EC_Cluster4 "EC_Cluster4";
BA_ "FlexKomComment" SG_ 983 EC_Cluster4 "Instrument cluster ecu configuration 4";
BA_ "FlexKomIsMotorola" SG_ 983 EC_Cluster4 1;
BA_ "GenSigSNA" SG_ 983 EC_Cluster4 "0h";
BA_ "GenSigCycleTime" SG_ 984 EC_ECUCfg9_Stat 2000;
BA_ "FlexKomSigStartValue" SG_ 984 EC_ECUCfg9_Stat "03h";
BA_ "GenSigStartValue" SG_ 984 EC_ECUCfg9_Stat 3;
BA_ "FlexKomSID" SG_ 984 EC_ECUCfg9_Stat 1215;
BA_ "FlexKomSigStartPos" SG_ 984 EC_ECUCfg9_Stat 1;
BA_ "FlexKomSigLaenge" SG_ 984 EC_ECUCfg9_Stat 2;
BA_ "FlexKomSigName" SG_ 984 EC_ECUCfg9_Stat "EC_ECUCfg9_Stat";
BA_ "FlexKomComment" SG_ 984 EC_ECUCfg9_Stat "ECU Configuration messages status 9";
BA_ "FlexKomIsMotorola" SG_ 984 EC_ECUCfg9_Stat 1;
BA_ "GenSigSNA" SG_ 984 EC_ECUCfg9_Stat "3h";
BA_ "GenSigCycleTime" SG_ 984 EC_CBC9A1 2000;
BA_ "FlexKomSigStartValue" SG_ 984 EC_CBC9A1 "00000000h";
BA_ "FlexKomSID" SG_ 984 EC_CBC9A1 1421;
BA_ "FlexKomSigStartPos" SG_ 984 EC_CBC9A1 7;
BA_ "FlexKomSigLaenge" SG_ 984 EC_CBC9A1 32;
BA_ "FlexKomSigName" SG_ 984 EC_CBC9A1 "EC_CBC9A";
BA_ "FlexKomComment" SG_ 984 EC_CBC9A1 "CBC configuration 9A";
BA_ "FlexKomIsMotorola" SG_ 984 EC_CBC9A1 1;
BA_ "GenSigSNA" SG_ 984 EC_CBC9A1 "0h";
BA_ "GenSigCycleTime" SG_ 984 EC_CBC9A2 2000;
BA_ "FlexKomSigStartValue" SG_ 984 EC_CBC9A2 "00000000h";
BA_ "FlexKomSID" SG_ 984 EC_CBC9A2 1421;
BA_ "FlexKomSigStartPos" SG_ 984 EC_CBC9A2 7;
BA_ "FlexKomSigLaenge" SG_ 984 EC_CBC9A2 32;
BA_ "FlexKomSigName" SG_ 984 EC_CBC9A2 "EC_CBC9A";
BA_ "FlexKomComment" SG_ 984 EC_CBC9A2 "CBC configuration 9A";
BA_ "FlexKomIsMotorola" SG_ 984 EC_CBC9A2 1;
BA_ "GenSigSNA" SG_ 984 EC_CBC9A2 "0h";
BA_ "GenSigCycleTime" SG_ 984 EC_CBC9B 2000;
BA_ "FlexKomSigStartValue" SG_ 984 EC_CBC9B "0000h";
BA_ "FlexKomSID" SG_ 984 EC_CBC9B 1422;
BA_ "FlexKomSigStartPos" SG_ 984 EC_CBC9B 39;
BA_ "FlexKomSigLaenge" SG_ 984 EC_CBC9B 16;
BA_ "FlexKomSigName" SG_ 984 EC_CBC9B "EC_CBC9B";
BA_ "FlexKomComment" SG_ 984 EC_CBC9B "CBC configuration 9B";
BA_ "FlexKomIsMotorola" SG_ 984 EC_CBC9B 1;
BA_ "GenSigSNA" SG_ 984 EC_CBC9B "0h";
BA_ "GenSigCycleTime" SG_ 984 EC_ITM 2000;
BA_ "FlexKomSigStartValue" SG_ 984 EC_ITM "0000h";
BA_ "FlexKomSID" SG_ 984 EC_ITM 1219;
BA_ "FlexKomSigStartPos" SG_ 984 EC_ITM 55;
BA_ "FlexKomSigLaenge" SG_ 984 EC_ITM 16;
BA_ "FlexKomSigName" SG_ 984 EC_ITM "EC_ITM";
BA_ "FlexKomComment" SG_ 984 EC_ITM "ITM ecu configuration";
BA_ "FlexKomIsMotorola" SG_ 984 EC_ITM 1;
BA_ "GenSigSNA" SG_ 984 EC_ITM "0h";
BA_ "GenSigSendType" SG_ 985 EC_BU_ECUCfg14_Stat 1;
BA_ "FlexKomSigStartValue" SG_ 985 EC_BU_ECUCfg14_Stat "03h";
BA_ "GenSigStartValue" SG_ 985 EC_BU_ECUCfg14_Stat 3;
BA_ "FlexKomSID" SG_ 985 EC_BU_ECUCfg14_Stat 1952;
BA_ "FlexKomSigStartPos" SG_ 985 EC_BU_ECUCfg14_Stat 1;
BA_ "FlexKomSigLaenge" SG_ 985 EC_BU_ECUCfg14_Stat 2;
BA_ "FlexKomSigName" SG_ 985 EC_BU_ECUCfg14_Stat "EC_BU_ECUCfg14_Stat";
BA_ "FlexKomComment" SG_ 985 EC_BU_ECUCfg14_Stat "Backup for ECU Configuration messages status 14";
BA_ "FlexKomIsMotorola" SG_ 985 EC_BU_ECUCfg14_Stat 1;
BA_ "GenSigSNA" SG_ 985 EC_BU_ECUCfg14_Stat "3h";
BA_ "GenSigSendType" SG_ 985 EC_BU_CBC14A 1;
BA_ "FlexKomSigStartValue" SG_ 985 EC_BU_CBC14A "0000000000000000h";
BA_ "FlexKomSID" SG_ 985 EC_BU_CBC14A 1953;
BA_ "FlexKomSigStartPos" SG_ 985 EC_BU_CBC14A 7;
BA_ "FlexKomSigLaenge" SG_ 985 EC_BU_CBC14A 64;
BA_ "FlexKomSigName" SG_ 985 EC_BU_CBC14A "EC_BU_CBC14";
BA_ "FlexKomComment" SG_ 985 EC_BU_CBC14A "CBC ecu configuration 14";
BA_ "FlexKomIsMotorola" SG_ 985 EC_BU_CBC14A 1;
BA_ "GenSigSNA" SG_ 985 EC_BU_CBC14A "0h";
BA_ "GenSigSendType" SG_ 985 EC_BU_CBC14B 1;
BA_ "FlexKomSigStartValue" SG_ 985 EC_BU_CBC14B "0000000000000000h";
BA_ "FlexKomSID" SG_ 985 EC_BU_CBC14B 1953;
BA_ "FlexKomSigStartPos" SG_ 985 EC_BU_CBC14B 7;
BA_ "FlexKomSigLaenge" SG_ 985 EC_BU_CBC14B 64;
BA_ "FlexKomSigName" SG_ 985 EC_BU_CBC14B "EC_BU_CBC14";
BA_ "FlexKomComment" SG_ 985 EC_BU_CBC14B "CBC ecu configuration 14";
BA_ "FlexKomIsMotorola" SG_ 985 EC_BU_CBC14B 1;
BA_ "GenSigSNA" SG_ 985 EC_BU_CBC14B "0h";
BA_ "GenSigSendType" SG_ 986 EC_BU_ECUCfg13_Stat 1;
BA_ "FlexKomSigStartValue" SG_ 986 EC_BU_ECUCfg13_Stat "03h";
BA_ "GenSigStartValue" SG_ 986 EC_BU_ECUCfg13_Stat 3;
BA_ "FlexKomSID" SG_ 986 EC_BU_ECUCfg13_Stat 1871;
BA_ "FlexKomSigStartPos" SG_ 986 EC_BU_ECUCfg13_Stat 1;
BA_ "FlexKomSigLaenge" SG_ 986 EC_BU_ECUCfg13_Stat 2;
BA_ "FlexKomSigName" SG_ 986 EC_BU_ECUCfg13_Stat "EC_BU_ECUCfg13_Stat";
BA_ "FlexKomComment" SG_ 986 EC_BU_ECUCfg13_Stat "Backup for ECU Configuration messages status 13";
BA_ "FlexKomIsMotorola" SG_ 986 EC_BU_ECUCfg13_Stat 1;
BA_ "GenSigSNA" SG_ 986 EC_BU_ECUCfg13_Stat "3h";
BA_ "GenSigSendType" SG_ 986 EC_BU_CBC13A 1;
BA_ "FlexKomSigStartValue" SG_ 986 EC_BU_CBC13A "0000000000000000h";
BA_ "FlexKomSID" SG_ 986 EC_BU_CBC13A 1991;
BA_ "FlexKomSigStartPos" SG_ 986 EC_BU_CBC13A 7;
BA_ "FlexKomSigLaenge" SG_ 986 EC_BU_CBC13A 64;
BA_ "FlexKomSigName" SG_ 986 EC_BU_CBC13A "EC_BU_CBC13";
BA_ "FlexKomComment" SG_ 986 EC_BU_CBC13A "CBC ecu configuration 13";
BA_ "FlexKomIsMotorola" SG_ 986 EC_BU_CBC13A 1;
BA_ "GenSigSNA" SG_ 986 EC_BU_CBC13A "0h";
BA_ "GenSigSendType" SG_ 986 EC_BU_CBC13B 1;
BA_ "FlexKomSigStartValue" SG_ 986 EC_BU_CBC13B "0000000000000000h";
BA_ "FlexKomSID" SG_ 986 EC_BU_CBC13B 1991;
BA_ "FlexKomSigStartPos" SG_ 986 EC_BU_CBC13B 7;
BA_ "FlexKomSigLaenge" SG_ 986 EC_BU_CBC13B 64;
BA_ "FlexKomSigName" SG_ 986 EC_BU_CBC13B "EC_BU_CBC13";
BA_ "FlexKomComment" SG_ 986 EC_BU_CBC13B "CBC ecu configuration 13";
BA_ "FlexKomIsMotorola" SG_ 986 EC_BU_CBC13B 1;
BA_ "GenSigSNA" SG_ 986 EC_BU_CBC13B "0h";
BA_ "GenSigSendType" SG_ 987 EC_BU_ECUCfg12_Stat 1;
BA_ "FlexKomSigStartValue" SG_ 987 EC_BU_ECUCfg12_Stat "03h";
BA_ "GenSigStartValue" SG_ 987 EC_BU_ECUCfg12_Stat 3;
BA_ "FlexKomSID" SG_ 987 EC_BU_ECUCfg12_Stat 1836;
BA_ "FlexKomSigStartPos" SG_ 987 EC_BU_ECUCfg12_Stat 1;
BA_ "FlexKomSigLaenge" SG_ 987 EC_BU_ECUCfg12_Stat 2;
BA_ "FlexKomSigName" SG_ 987 EC_BU_ECUCfg12_Stat "EC_BU_ECUCfg12_Stat";
BA_ "FlexKomComment" SG_ 987 EC_BU_ECUCfg12_Stat "Backup for ECU Configuration messages status 12";
BA_ "FlexKomIsMotorola" SG_ 987 EC_BU_ECUCfg12_Stat 1;
BA_ "GenSigSNA" SG_ 987 EC_BU_ECUCfg12_Stat "3h";
BA_ "GenSigSendType" SG_ 987 EC_BU_Cluster5A 1;
BA_ "FlexKomSigStartValue" SG_ 987 EC_BU_Cluster5A "0000000000000000h";
BA_ "FlexKomSID" SG_ 987 EC_BU_Cluster5A 1837;
BA_ "FlexKomSigStartPos" SG_ 987 EC_BU_Cluster5A 7;
BA_ "FlexKomSigLaenge" SG_ 987 EC_BU_Cluster5A 64;
BA_ "FlexKomSigName" SG_ 987 EC_BU_Cluster5A "EC_BU_Cluster5";
BA_ "FlexKomComment" SG_ 987 EC_BU_Cluster5A "Backup for Instrument cluster ecu configuration 5";
BA_ "FlexKomIsMotorola" SG_ 987 EC_BU_Cluster5A 1;
BA_ "GenSigSNA" SG_ 987 EC_BU_Cluster5A "0h";
BA_ "GenSigSendType" SG_ 987 EC_BU_Cluster5B 1;
BA_ "FlexKomSigStartValue" SG_ 987 EC_BU_Cluster5B "0000000000000000h";
BA_ "FlexKomSID" SG_ 987 EC_BU_Cluster5B 1837;
BA_ "FlexKomSigStartPos" SG_ 987 EC_BU_Cluster5B 7;
BA_ "FlexKomSigLaenge" SG_ 987 EC_BU_Cluster5B 64;
BA_ "FlexKomSigName" SG_ 987 EC_BU_Cluster5B "EC_BU_Cluster5";
BA_ "FlexKomComment" SG_ 987 EC_BU_Cluster5B "Backup for Instrument cluster ecu configuration 5";
BA_ "FlexKomIsMotorola" SG_ 987 EC_BU_Cluster5B 1;
BA_ "GenSigSNA" SG_ 987 EC_BU_Cluster5B "0h";
BA_ "GenSigSendType" SG_ 987 EC_BU_Cluster5C 1;
BA_ "FlexKomSigStartValue" SG_ 987 EC_BU_Cluster5C "0000000000000000h";
BA_ "FlexKomSID" SG_ 987 EC_BU_Cluster5C 1837;
BA_ "FlexKomSigStartPos" SG_ 987 EC_BU_Cluster5C 7;
BA_ "FlexKomSigLaenge" SG_ 987 EC_BU_Cluster5C 64;
BA_ "FlexKomSigName" SG_ 987 EC_BU_Cluster5C "EC_BU_Cluster5";
BA_ "FlexKomComment" SG_ 987 EC_BU_Cluster5C "Backup for Instrument cluster ecu configuration 5";
BA_ "FlexKomIsMotorola" SG_ 987 EC_BU_Cluster5C 1;
BA_ "GenSigSNA" SG_ 987 EC_BU_Cluster5C "0h";
BA_ "GenSigSendType" SG_ 988 EC_BU_ECUCfg11_Stat 1;
BA_ "FlexKomSigStartValue" SG_ 988 EC_BU_ECUCfg11_Stat "03h";
BA_ "GenSigStartValue" SG_ 988 EC_BU_ECUCfg11_Stat 3;
BA_ "FlexKomSID" SG_ 988 EC_BU_ECUCfg11_Stat 1711;
BA_ "FlexKomSigStartPos" SG_ 988 EC_BU_ECUCfg11_Stat 1;
BA_ "FlexKomSigLaenge" SG_ 988 EC_BU_ECUCfg11_Stat 2;
BA_ "FlexKomSigName" SG_ 988 EC_BU_ECUCfg11_Stat "EC_BU_ECUCfg11_Stat";
BA_ "FlexKomComment" SG_ 988 EC_BU_ECUCfg11_Stat "Backup for ECU Configuration messages status 11";
BA_ "FlexKomIsMotorola" SG_ 988 EC_BU_ECUCfg11_Stat 1;
BA_ "GenSigSNA" SG_ 988 EC_BU_ECUCfg11_Stat "3h";
BA_ "GenSigSendType" SG_ 988 EC_BU_CBC10A 1;
BA_ "FlexKomSigStartValue" SG_ 988 EC_BU_CBC10A "00000000h";
BA_ "FlexKomSID" SG_ 988 EC_BU_CBC10A 1712;
BA_ "FlexKomSigStartPos" SG_ 988 EC_BU_CBC10A 7;
BA_ "FlexKomSigLaenge" SG_ 988 EC_BU_CBC10A 32;
BA_ "FlexKomSigName" SG_ 988 EC_BU_CBC10A "EC_BU_CBC10";
BA_ "FlexKomComment" SG_ 988 EC_BU_CBC10A "Backup for CBC ecu configuration 10";
BA_ "FlexKomIsMotorola" SG_ 988 EC_BU_CBC10A 1;
BA_ "GenSigSNA" SG_ 988 EC_BU_CBC10A "0h";
BA_ "GenSigSendType" SG_ 988 EC_BU_CBC10B 1;
BA_ "FlexKomSigStartValue" SG_ 988 EC_BU_CBC10B "00000000h";
BA_ "FlexKomSID" SG_ 988 EC_BU_CBC10B 1712;
BA_ "FlexKomSigStartPos" SG_ 988 EC_BU_CBC10B 7;
BA_ "FlexKomSigLaenge" SG_ 988 EC_BU_CBC10B 32;
BA_ "FlexKomSigName" SG_ 988 EC_BU_CBC10B "EC_BU_CBC10";
BA_ "FlexKomComment" SG_ 988 EC_BU_CBC10B "Backup for CBC ecu configuration 10";
BA_ "FlexKomIsMotorola" SG_ 988 EC_BU_CBC10B 1;
BA_ "GenSigSNA" SG_ 988 EC_BU_CBC10B "0h";
BA_ "GenSigSendType" SG_ 988 EC_BU_CBC11 1;
BA_ "FlexKomSigStartValue" SG_ 988 EC_BU_CBC11 "00000000h";
BA_ "FlexKomSID" SG_ 988 EC_BU_CBC11 1713;
BA_ "FlexKomSigStartPos" SG_ 988 EC_BU_CBC11 39;
BA_ "FlexKomSigLaenge" SG_ 988 EC_BU_CBC11 32;
BA_ "FlexKomSigName" SG_ 988 EC_BU_CBC11 "EC_BU_CBC11";
BA_ "FlexKomComment" SG_ 988 EC_BU_CBC11 "Backup for CBC ecu configuration 11";
BA_ "FlexKomIsMotorola" SG_ 988 EC_BU_CBC11 1;
BA_ "GenSigSNA" SG_ 988 EC_BU_CBC11 "0h";
BA_ "GenSigSendType" SG_ 989 EC_BU_ECUCfg10_Stat 1;
BA_ "FlexKomSigStartValue" SG_ 989 EC_BU_ECUCfg10_Stat "03h";
BA_ "GenSigStartValue" SG_ 989 EC_BU_ECUCfg10_Stat 3;
BA_ "FlexKomSID" SG_ 989 EC_BU_ECUCfg10_Stat 1302;
BA_ "FlexKomSigStartPos" SG_ 989 EC_BU_ECUCfg10_Stat 1;
BA_ "FlexKomSigLaenge" SG_ 989 EC_BU_ECUCfg10_Stat 2;
BA_ "FlexKomSigName" SG_ 989 EC_BU_ECUCfg10_Stat "EC_BU_ECUCfg10_Stat";
BA_ "FlexKomComment" SG_ 989 EC_BU_ECUCfg10_Stat "Backup for ECU Configuration messages status 10";
BA_ "FlexKomIsMotorola" SG_ 989 EC_BU_ECUCfg10_Stat 1;
BA_ "GenSigSNA" SG_ 989 EC_BU_ECUCfg10_Stat "3h";
BA_ "GenSigSendType" SG_ 989 EC_BU_Cluster3A 1;
BA_ "FlexKomSigStartValue" SG_ 989 EC_BU_Cluster3A "00000000h";
BA_ "FlexKomSID" SG_ 989 EC_BU_Cluster3A 1305;
BA_ "FlexKomSigStartPos" SG_ 989 EC_BU_Cluster3A 7;
BA_ "FlexKomSigLaenge" SG_ 989 EC_BU_Cluster3A 32;
BA_ "FlexKomSigName" SG_ 989 EC_BU_Cluster3A "EC_BU_Cluster3";
BA_ "FlexKomComment" SG_ 989 EC_BU_Cluster3A "Backup for Instrument cluster ecu configuration 3";
BA_ "FlexKomIsMotorola" SG_ 989 EC_BU_Cluster3A 1;
BA_ "GenSigSNA" SG_ 989 EC_BU_Cluster3A "0h";
BA_ "GenSigSendType" SG_ 989 EC_BU_Cluster3B 1;
BA_ "FlexKomSigStartValue" SG_ 989 EC_BU_Cluster3B "00000000h";
BA_ "FlexKomSID" SG_ 989 EC_BU_Cluster3B 1305;
BA_ "FlexKomSigStartPos" SG_ 989 EC_BU_Cluster3B 7;
BA_ "FlexKomSigLaenge" SG_ 989 EC_BU_Cluster3B 32;
BA_ "FlexKomSigName" SG_ 989 EC_BU_Cluster3B "EC_BU_Cluster3";
BA_ "FlexKomComment" SG_ 989 EC_BU_Cluster3B "Backup for Instrument cluster ecu configuration 3";
BA_ "FlexKomIsMotorola" SG_ 989 EC_BU_Cluster3B 1;
BA_ "GenSigSNA" SG_ 989 EC_BU_Cluster3B "0h";
BA_ "GenSigSendType" SG_ 989 EC_BU_Cluster4 1;
BA_ "FlexKomSigStartValue" SG_ 989 EC_BU_Cluster4 "00000000h";
BA_ "FlexKomSID" SG_ 989 EC_BU_Cluster4 1304;
BA_ "FlexKomSigStartPos" SG_ 989 EC_BU_Cluster4 39;
BA_ "FlexKomSigLaenge" SG_ 989 EC_BU_Cluster4 32;
BA_ "FlexKomSigName" SG_ 989 EC_BU_Cluster4 "EC_BU_Cluster4";
BA_ "FlexKomComment" SG_ 989 EC_BU_Cluster4 "Backup for Instrument cluster ecu configuration 4";
BA_ "FlexKomIsMotorola" SG_ 989 EC_BU_Cluster4 1;
BA_ "GenSigSNA" SG_ 989 EC_BU_Cluster4 "0h";
BA_ "GenSigSendType" SG_ 991 EC_BU_ECUCfg9_Stat 1;
BA_ "FlexKomSigStartValue" SG_ 991 EC_BU_ECUCfg9_Stat "03h";
BA_ "GenSigStartValue" SG_ 991 EC_BU_ECUCfg9_Stat 3;
BA_ "FlexKomSID" SG_ 991 EC_BU_ECUCfg9_Stat 1216;
BA_ "FlexKomSigStartPos" SG_ 991 EC_BU_ECUCfg9_Stat 1;
BA_ "FlexKomSigLaenge" SG_ 991 EC_BU_ECUCfg9_Stat 2;
BA_ "FlexKomSigName" SG_ 991 EC_BU_ECUCfg9_Stat "EC_BU_ECUCfg9_Stat";
BA_ "FlexKomComment" SG_ 991 EC_BU_ECUCfg9_Stat "Backup for ECU Configuration messages status 9";
BA_ "FlexKomIsMotorola" SG_ 991 EC_BU_ECUCfg9_Stat 1;
BA_ "GenSigSNA" SG_ 991 EC_BU_ECUCfg9_Stat "3h";
BA_ "GenSigSendType" SG_ 991 EC_BU_CBC9A1 1;
BA_ "FlexKomSigStartValue" SG_ 991 EC_BU_CBC9A1 "00000000h";
BA_ "FlexKomSID" SG_ 991 EC_BU_CBC9A1 1419;
BA_ "FlexKomSigStartPos" SG_ 991 EC_BU_CBC9A1 7;
BA_ "FlexKomSigLaenge" SG_ 991 EC_BU_CBC9A1 32;
BA_ "FlexKomSigName" SG_ 991 EC_BU_CBC9A1 "EC_BU_CBC9A";
BA_ "FlexKomComment" SG_ 991 EC_BU_CBC9A1 "Backup for CBC configuration 9A";
BA_ "FlexKomIsMotorola" SG_ 991 EC_BU_CBC9A1 1;
BA_ "GenSigSNA" SG_ 991 EC_BU_CBC9A1 "0h";
BA_ "GenSigSendType" SG_ 991 EC_BU_CBC9A2 1;
BA_ "FlexKomSigStartValue" SG_ 991 EC_BU_CBC9A2 "00000000h";
BA_ "FlexKomSID" SG_ 991 EC_BU_CBC9A2 1419;
BA_ "FlexKomSigStartPos" SG_ 991 EC_BU_CBC9A2 7;
BA_ "FlexKomSigLaenge" SG_ 991 EC_BU_CBC9A2 32;
BA_ "FlexKomSigName" SG_ 991 EC_BU_CBC9A2 "EC_BU_CBC9A";
BA_ "FlexKomComment" SG_ 991 EC_BU_CBC9A2 "Backup for CBC configuration 9A";
BA_ "FlexKomIsMotorola" SG_ 991 EC_BU_CBC9A2 1;
BA_ "GenSigSNA" SG_ 991 EC_BU_CBC9A2 "0h";
BA_ "GenSigSendType" SG_ 991 EC_BU_CBC9B 1;
BA_ "FlexKomSigStartValue" SG_ 991 EC_BU_CBC9B "0000h";
BA_ "FlexKomSID" SG_ 991 EC_BU_CBC9B 1420;
BA_ "FlexKomSigStartPos" SG_ 991 EC_BU_CBC9B 39;
BA_ "FlexKomSigLaenge" SG_ 991 EC_BU_CBC9B 16;
BA_ "FlexKomSigName" SG_ 991 EC_BU_CBC9B "EC_BU_CBC9B";
BA_ "FlexKomComment" SG_ 991 EC_BU_CBC9B "Backup for CBC configuration 9B";
BA_ "FlexKomIsMotorola" SG_ 991 EC_BU_CBC9B 1;
BA_ "GenSigSNA" SG_ 991 EC_BU_CBC9B "0h";
BA_ "GenSigSendType" SG_ 991 EC_BU_ITM 1;
BA_ "FlexKomSigStartValue" SG_ 991 EC_BU_ITM "0000h";
BA_ "FlexKomSID" SG_ 991 EC_BU_ITM 1220;
BA_ "FlexKomSigStartPos" SG_ 991 EC_BU_ITM 55;
BA_ "FlexKomSigLaenge" SG_ 991 EC_BU_ITM 16;
BA_ "FlexKomSigName" SG_ 991 EC_BU_ITM "EC_BU_ITM";
BA_ "FlexKomComment" SG_ 991 EC_BU_ITM "Backup for ITM ecu configuration";
BA_ "FlexKomIsMotorola" SG_ 991 EC_BU_ITM 1;
BA_ "GenSigSNA" SG_ 991 EC_BU_ITM "0h";
BA_ "GenSigCycleTime" SG_ 992 VIN_MSG 100;
BA_ "FlexKomSigStartValue" SG_ 992 VIN_MSG "0300000000000000h";
BA_ "GenSigStartValue" SG_ 992 VIN_MSG 3;
BA_ "GenSigTimeout_RF_HUB" SG_ 992 VIN_MSG 1050;
BA_ "GenSigTimeout_IC" SG_ 992 VIN_MSG 1050;
BA_ "GenSigTimeout_TPM" SG_ 992 VIN_MSG 1050;
BA_ "GenSigTimeout_EPS" SG_ 992 VIN_MSG 1050;
BA_ "GenSigTimeout_SCCM" SG_ 992 VIN_MSG 1050;
BA_ "GenSigTimeout_ESM" SG_ 992 VIN_MSG 1050;
BA_ "GenSigTimeout_ADCM" SG_ 992 VIN_MSG 5050;
BA_ "GenSigTimeout_ORC" SG_ 992 VIN_MSG 350;
BA_ "FlexKomSID" SG_ 992 VIN_MSG 430;
BA_ "FlexKomSigStartPos" SG_ 992 VIN_MSG 7;
BA_ "FlexKomSigLaenge" SG_ 992 VIN_MSG 64;
BA_ "FlexKomSigName" SG_ 992 VIN_MSG "VIN_INFO";
BA_ "FlexKomComment" SG_ 992 VIN_MSG "Vin Information";
BA_ "FlexKomIsMotorola" SG_ 992 VIN_MSG 1;
BA_ "GenSigSNA" SG_ 992 VIN_MSG "3h";
BA_ "GenSigCycleTime" SG_ 992 VIN_DATA 100;
BA_ "FlexKomSigStartValue" SG_ 992 VIN_DATA "0300000000000000h";
BA_ "GenSigTimeout_IC" SG_ 992 VIN_DATA 1050;
BA_ "GenSigTimeout_TPM" SG_ 992 VIN_DATA 1050;
BA_ "GenSigTimeout_EPS" SG_ 992 VIN_DATA 1050;
BA_ "GenSigTimeout_SCCM" SG_ 992 VIN_DATA 1050;
BA_ "GenSigTimeout_ESM" SG_ 992 VIN_DATA 1050;
BA_ "GenSigTimeout_ADCM" SG_ 992 VIN_DATA 5050;
BA_ "GenSigTimeout_ORC" SG_ 992 VIN_DATA 350;
BA_ "FlexKomSID" SG_ 992 VIN_DATA 430;
BA_ "FlexKomSigStartPos" SG_ 992 VIN_DATA 7;
BA_ "FlexKomSigLaenge" SG_ 992 VIN_DATA 64;
BA_ "FlexKomSigName" SG_ 992 VIN_DATA "VIN_INFO";
BA_ "FlexKomComment" SG_ 992 VIN_DATA "Vin Information";
BA_ "FlexKomIsMotorola" SG_ 992 VIN_DATA 1;
BA_ "GenSigSNA" SG_ 992 VIN_DATA "0h";
BA_ "GenSigCycleTime" SG_ 993 DISPLACEMENT 100;
BA_ "FlexKomSigStartValue" SG_ 993 DISPLACEMENT "FFEFE7E7h";
BA_ "GenSigStartValue" SG_ 993 DISPLACEMENT 255;
BA_ "GenSigTimeout_CBC" SG_ 993 DISPLACEMENT 1050;
BA_ "GenSigTimeout_IC" SG_ 993 DISPLACEMENT 1050;
BA_ "GenSigTimeout_EPS" SG_ 993 DISPLACEMENT 1050;
BA_ "GenSigTimeout_ETM" SG_ 993 DISPLACEMENT 1050;
BA_ "FlexKomSID" SG_ 993 DISPLACEMENT 617;
BA_ "FlexKomSigStartPos" SG_ 993 DISPLACEMENT 7;
BA_ "FlexKomSigLaenge" SG_ 993 DISPLACEMENT 32;
BA_ "FlexKomSigName" SG_ 993 DISPLACEMENT "ENG_CFG";
BA_ "FlexKomComment" SG_ 993 DISPLACEMENT "Engine Configuration Information";
BA_ "FlexKomIsMotorola" SG_ 993 DISPLACEMENT 1;
BA_ "GenSigSNA" SG_ 993 DISPLACEMENT "FFh";
BA_ "GenSigCycleTime" SG_ 993 NUM_CYL 100;
BA_ "FlexKomSigStartValue" SG_ 993 NUM_CYL "FFEFE7E7h";
BA_ "GenSigStartValue" SG_ 993 NUM_CYL 15;
BA_ "FlexKomSID" SG_ 993 NUM_CYL 617;
BA_ "FlexKomSigStartPos" SG_ 993 NUM_CYL 7;
BA_ "FlexKomSigLaenge" SG_ 993 NUM_CYL 32;
BA_ "FlexKomSigName" SG_ 993 NUM_CYL "ENG_CFG";
BA_ "FlexKomComment" SG_ 993 NUM_CYL "Engine Configuration Information";
BA_ "FlexKomIsMotorola" SG_ 993 NUM_CYL 1;
BA_ "GenSigSNA" SG_ 993 NUM_CYL "Fh";
BA_ "GenSigCycleTime" SG_ 993 SpStPrsnt 100;
BA_ "FlexKomSigStartValue" SG_ 993 SpStPrsnt "FFEFE7E7h";
BA_ "GenSigTimeout_IC" SG_ 993 SpStPrsnt 1050;
BA_ "GenSigTimeout_EPS" SG_ 993 SpStPrsnt 1050;
BA_ "FlexKomSID" SG_ 993 SpStPrsnt 617;
BA_ "FlexKomSigStartPos" SG_ 993 SpStPrsnt 7;
BA_ "FlexKomSigLaenge" SG_ 993 SpStPrsnt 32;
BA_ "FlexKomSigName" SG_ 993 SpStPrsnt "ENG_CFG";
BA_ "FlexKomComment" SG_ 993 SpStPrsnt "Engine Configuration Information";
BA_ "FlexKomIsMotorola" SG_ 993 SpStPrsnt 1;
BA_ "GenSigSNA" SG_ 993 SpStPrsnt "0h";
BA_ "GenSigCycleTime" SG_ 993 ENG_ASP 100;
BA_ "FlexKomSigStartValue" SG_ 993 ENG_ASP "FFEFE7E7h";
BA_ "GenSigStartValue" SG_ 993 ENG_ASP 7;
BA_ "GenSigTimeout_ETM" SG_ 993 ENG_ASP 1050;
BA_ "FlexKomSID" SG_ 993 ENG_ASP 617;
BA_ "FlexKomSigStartPos" SG_ 993 ENG_ASP 7;
BA_ "FlexKomSigLaenge" SG_ 993 ENG_ASP 32;
BA_ "FlexKomSigName" SG_ 993 ENG_ASP "ENG_CFG";
BA_ "FlexKomComment" SG_ 993 ENG_ASP "Engine Configuration Information";
BA_ "FlexKomIsMotorola" SG_ 993 ENG_ASP 1;
BA_ "GenSigSNA" SG_ 993 ENG_ASP "7h";
BA_ "GenSigCycleTime" SG_ 993 FUEL_TYPE 100;
BA_ "FlexKomSigStartValue" SG_ 993 FUEL_TYPE "FFEFE7E7h";
BA_ "GenSigStartValue" SG_ 993 FUEL_TYPE 7;
BA_ "GenSigTimeout_CBC" SG_ 993 FUEL_TYPE 1050;
BA_ "GenSigTimeout_IC" SG_ 993 FUEL_TYPE 1050;
BA_ "GenSigTimeout_ORC" SG_ 993 FUEL_TYPE 350;
BA_ "FlexKomSID" SG_ 993 FUEL_TYPE 617;
BA_ "FlexKomSigStartPos" SG_ 993 FUEL_TYPE 7;
BA_ "FlexKomSigLaenge" SG_ 993 FUEL_TYPE 32;
BA_ "FlexKomSigName" SG_ 993 FUEL_TYPE "ENG_CFG";
BA_ "FlexKomComment" SG_ 993 FUEL_TYPE "Engine Configuration Information";
BA_ "FlexKomIsMotorola" SG_ 993 FUEL_TYPE 1;
BA_ "GenSigSNA" SG_ 993 FUEL_TYPE "7h";
BA_ "GenSigCycleTime" SG_ 993 Manufacture 100;
BA_ "FlexKomSigStartValue" SG_ 993 Manufacture "FFEFE7E7h";
BA_ "GenSigStartValue" SG_ 993 Manufacture 7;
BA_ "FlexKomSID" SG_ 993 Manufacture 617;
BA_ "FlexKomSigStartPos" SG_ 993 Manufacture 7;
BA_ "FlexKomSigLaenge" SG_ 993 Manufacture 32;
BA_ "FlexKomSigName" SG_ 993 Manufacture "ENG_CFG";
BA_ "FlexKomComment" SG_ 993 Manufacture "Engine Configuration Information";
BA_ "FlexKomIsMotorola" SG_ 993 Manufacture 1;
BA_ "GenSigSNA" SG_ 993 Manufacture "7h";
BA_ "GenSigCycleTime" SG_ 993 NUM_VALVE 100;
BA_ "FlexKomSigStartValue" SG_ 993 NUM_VALVE "FFEFE7E7h";
BA_ "GenSigStartValue" SG_ 993 NUM_VALVE 7;
BA_ "FlexKomSID" SG_ 993 NUM_VALVE 617;
BA_ "FlexKomSigStartPos" SG_ 993 NUM_VALVE 7;
BA_ "FlexKomSigLaenge" SG_ 993 NUM_VALVE 32;
BA_ "FlexKomSigName" SG_ 993 NUM_VALVE "ENG_CFG";
BA_ "FlexKomComment" SG_ 993 NUM_VALVE "Engine Configuration Information";
BA_ "FlexKomIsMotorola" SG_ 993 NUM_VALVE 1;
BA_ "GenSigSNA" SG_ 993 NUM_VALVE "7h";
BA_ "GenSigCycleTime" SG_ 993 ETC_PRSNT 100;
BA_ "FlexKomSigStartValue" SG_ 993 ETC_PRSNT "FFEFE7E7h";
BA_ "GenSigTimeout_IC" SG_ 993 ETC_PRSNT 1050;
BA_ "FlexKomSID" SG_ 993 ETC_PRSNT 617;
BA_ "FlexKomSigStartPos" SG_ 993 ETC_PRSNT 7;
BA_ "FlexKomSigLaenge" SG_ 993 ETC_PRSNT 32;
BA_ "FlexKomSigName" SG_ 993 ETC_PRSNT "ENG_CFG";
BA_ "FlexKomComment" SG_ 993 ETC_PRSNT "Engine Configuration Information";
BA_ "FlexKomIsMotorola" SG_ 993 ETC_PRSNT 1;
BA_ "GenSigSNA" SG_ 993 ETC_PRSNT "0h";
BA_ "GenSigCycleTime" SG_ 993 TRANS_TYPE 100;
BA_ "FlexKomSigStartValue" SG_ 993 TRANS_TYPE "FFEFE7E7h";
BA_ "GenSigTimeout_IC" SG_ 993 TRANS_TYPE 1050;
BA_ "GenSigTimeout_TPM" SG_ 993 TRANS_TYPE 1050;
BA_ "GenSigTimeout_ORC" SG_ 993 TRANS_TYPE 350;
BA_ "FlexKomSID" SG_ 993 TRANS_TYPE 617;
BA_ "FlexKomSigStartPos" SG_ 993 TRANS_TYPE 7;
BA_ "FlexKomSigLaenge" SG_ 993 TRANS_TYPE 32;
BA_ "FlexKomSigName" SG_ 993 TRANS_TYPE "ENG_CFG";
BA_ "FlexKomComment" SG_ 993 TRANS_TYPE "Engine Configuration Information";
BA_ "FlexKomIsMotorola" SG_ 993 TRANS_TYPE 1;
BA_ "GenSigSNA" SG_ 993 TRANS_TYPE "0h";
BA_ "GenSigCycleTime" SG_ 993 EngStyle 100;
BA_ "FlexKomSigStartValue" SG_ 993 EngStyle "FFEFE7E7h";
BA_ "GenSigStartValue" SG_ 993 EngStyle 7;
BA_ "GenSigTimeout_CBC" SG_ 993 EngStyle 1050;
BA_ "FlexKomSID" SG_ 993 EngStyle 617;
BA_ "FlexKomSigStartPos" SG_ 993 EngStyle 7;
BA_ "FlexKomSigLaenge" SG_ 993 EngStyle 32;
BA_ "FlexKomSigName" SG_ 993 EngStyle "ENG_CFG";
BA_ "FlexKomComment" SG_ 993 EngStyle "Engine Configuration Information";
BA_ "FlexKomIsMotorola" SG_ 993 EngStyle 1;
BA_ "GenSigSNA" SG_ 993 EngStyle "7h";
BA_ "GenSigCycleTime" SG_ 993 A580_INDEX 100;
BA_ "FlexKomSigStartValue" SG_ 993 A580_INDEX "1F0000h";
BA_ "GenSigStartValue" SG_ 993 A580_INDEX 31;
BA_ "FlexKomSID" SG_ 993 A580_INDEX 1090;
BA_ "FlexKomSigStartPos" SG_ 993 A580_INDEX 39;
BA_ "FlexKomSigLaenge" SG_ 993 A580_INDEX 24;
BA_ "FlexKomSigName" SG_ 993 A580_INDEX "AVC_CFG";
BA_ "FlexKomComment" SG_ 993 A580_INDEX "TCM_EGS AVC Configuration";
BA_ "FlexKomIsMotorola" SG_ 993 A580_INDEX 1;
BA_ "GenSigSNA" SG_ 993 A580_INDEX "1Fh";
BA_ "GenSigCycleTime" SG_ 993 A580_DATA 100;
BA_ "FlexKomSigStartValue" SG_ 993 A580_DATA "1F0000h";
BA_ "FlexKomSID" SG_ 993 A580_DATA 1090;
BA_ "FlexKomSigStartPos" SG_ 993 A580_DATA 39;
BA_ "FlexKomSigLaenge" SG_ 993 A580_DATA 24;
BA_ "FlexKomSigName" SG_ 993 A580_DATA "AVC_CFG";
BA_ "FlexKomComment" SG_ 993 A580_DATA "TCM_EGS AVC Configuration";
BA_ "FlexKomIsMotorola" SG_ 993 A580_DATA 1;
BA_ "GenSigSNA" SG_ 993 A580_DATA "0h";
BA_ "GenSigSendType" SG_ 994 NET_CFG_STAT_AT 5;
BA_ "GenSigCycleTime" SG_ 994 NET_CFG_STAT_AT 2000;
BA_ "FlexKomSigStartValue" SG_ 994 NET_CFG_STAT_AT "030000h";
BA_ "GenSigStartValue" SG_ 994 NET_CFG_STAT_AT 3;
BA_ "GenSigTimeout_RF_HUB" SG_ 994 NET_CFG_STAT_AT 21000;
BA_ "FlexKomSID" SG_ 994 NET_CFG_STAT_AT 40;
BA_ "FlexKomSigStartPos" SG_ 994 NET_CFG_STAT_AT 7;
BA_ "FlexKomSigLaenge" SG_ 994 NET_CFG_STAT_AT 24;
BA_ "FlexKomSigName" SG_ 994 NET_CFG_STAT_AT "NET_CFG_DATA_AT";
BA_ "FlexKomComment" SG_ 994 NET_CFG_STAT_AT "Network ECU config data for Audio and Telematics-C";
BA_ "FlexKomIsMotorola" SG_ 994 NET_CFG_STAT_AT 1;
BA_ "GenSigSNA" SG_ 994 NET_CFG_STAT_AT "3h";
BA_ "GenSigSendType" SG_ 994 NetCfg_AMP 5;
BA_ "GenSigCycleTime" SG_ 994 NetCfg_AMP 2000;
BA_ "FlexKomSigStartValue" SG_ 994 NetCfg_AMP "030000h";
BA_ "GenSigTimeout_RF_HUB" SG_ 994 NetCfg_AMP 21000;
BA_ "FlexKomSID" SG_ 994 NetCfg_AMP 40;
BA_ "FlexKomSigStartPos" SG_ 994 NetCfg_AMP 7;
BA_ "FlexKomSigLaenge" SG_ 994 NetCfg_AMP 24;
BA_ "FlexKomSigName" SG_ 994 NetCfg_AMP "NET_CFG_DATA_AT";
BA_ "FlexKomComment" SG_ 994 NetCfg_AMP "Network ECU config data for Audio and Telematics-C";
BA_ "FlexKomIsMotorola" SG_ 994 NetCfg_AMP 1;
BA_ "GenSigSNA" SG_ 994 NetCfg_AMP "0h";
BA_ "GenSigSendType" SG_ 994 NetCfg_ICS 5;
BA_ "GenSigCycleTime" SG_ 994 NetCfg_ICS 2000;
BA_ "FlexKomSigStartValue" SG_ 994 NetCfg_ICS "030000h";
BA_ "GenSigTimeout_RF_HUB" SG_ 994 NetCfg_ICS 21000;
BA_ "FlexKomSID" SG_ 994 NetCfg_ICS 40;
BA_ "FlexKomSigStartPos" SG_ 994 NetCfg_ICS 7;
BA_ "FlexKomSigLaenge" SG_ 994 NetCfg_ICS 24;
BA_ "FlexKomSigName" SG_ 994 NetCfg_ICS "NET_CFG_DATA_AT";
BA_ "FlexKomComment" SG_ 994 NetCfg_ICS "Network ECU config data for Audio and Telematics-C";
BA_ "FlexKomIsMotorola" SG_ 994 NetCfg_ICS 1;
BA_ "GenSigSNA" SG_ 994 NetCfg_ICS "0h";
BA_ "GenSigSendType" SG_ 994 NetCfg_PASS 5;
BA_ "GenSigCycleTime" SG_ 994 NetCfg_PASS 2000;
BA_ "FlexKomSigStartValue" SG_ 994 NetCfg_PASS "030000h";
BA_ "GenSigTimeout_RF_HUB" SG_ 994 NetCfg_PASS 21000;
BA_ "FlexKomSID" SG_ 994 NetCfg_PASS 40;
BA_ "FlexKomSigStartPos" SG_ 994 NetCfg_PASS 7;
BA_ "FlexKomSigLaenge" SG_ 994 NetCfg_PASS 24;
BA_ "FlexKomSigName" SG_ 994 NetCfg_PASS "NET_CFG_DATA_AT";
BA_ "FlexKomComment" SG_ 994 NetCfg_PASS "Network ECU config data for Audio and Telematics-C";
BA_ "FlexKomIsMotorola" SG_ 994 NetCfg_PASS 1;
BA_ "GenSigSNA" SG_ 994 NetCfg_PASS "0h";
BA_ "GenSigSendType" SG_ 994 NetCfg_SDARV 5;
BA_ "GenSigCycleTime" SG_ 994 NetCfg_SDARV 2000;
BA_ "FlexKomSigStartValue" SG_ 994 NetCfg_SDARV "030000h";
BA_ "GenSigTimeout_RF_HUB" SG_ 994 NetCfg_SDARV 21000;
BA_ "FlexKomSID" SG_ 994 NetCfg_SDARV 40;
BA_ "FlexKomSigStartPos" SG_ 994 NetCfg_SDARV 7;
BA_ "FlexKomSigLaenge" SG_ 994 NetCfg_SDARV 24;
BA_ "FlexKomSigName" SG_ 994 NetCfg_SDARV "NET_CFG_DATA_AT";
BA_ "FlexKomComment" SG_ 994 NetCfg_SDARV "Network ECU config data for Audio and Telematics-C";
BA_ "FlexKomIsMotorola" SG_ 994 NetCfg_SDARV 1;
BA_ "GenSigSNA" SG_ 994 NetCfg_SDARV "0h";
BA_ "GenSigSendType" SG_ 994 NetCfg_VES3 5;
BA_ "GenSigCycleTime" SG_ 994 NetCfg_VES3 2000;
BA_ "FlexKomSigStartValue" SG_ 994 NetCfg_VES3 "030000h";
BA_ "GenSigTimeout_RF_HUB" SG_ 994 NetCfg_VES3 21000;
BA_ "FlexKomSID" SG_ 994 NetCfg_VES3 40;
BA_ "FlexKomSigStartPos" SG_ 994 NetCfg_VES3 7;
BA_ "FlexKomSigLaenge" SG_ 994 NetCfg_VES3 24;
BA_ "FlexKomSigName" SG_ 994 NetCfg_VES3 "NET_CFG_DATA_AT";
BA_ "FlexKomComment" SG_ 994 NetCfg_VES3 "Network ECU config data for Audio and Telematics-C";
BA_ "FlexKomIsMotorola" SG_ 994 NetCfg_VES3 1;
BA_ "GenSigSNA" SG_ 994 NetCfg_VES3 "0h";
BA_ "GenSigSendType" SG_ 994 NetCfg_VES2 5;
BA_ "GenSigCycleTime" SG_ 994 NetCfg_VES2 2000;
BA_ "FlexKomSigStartValue" SG_ 994 NetCfg_VES2 "030000h";
BA_ "GenSigTimeout_RF_HUB" SG_ 994 NetCfg_VES2 21000;
BA_ "FlexKomSID" SG_ 994 NetCfg_VES2 40;
BA_ "FlexKomSigStartPos" SG_ 994 NetCfg_VES2 7;
BA_ "FlexKomSigLaenge" SG_ 994 NetCfg_VES2 24;
BA_ "FlexKomSigName" SG_ 994 NetCfg_VES2 "NET_CFG_DATA_AT";
BA_ "FlexKomComment" SG_ 994 NetCfg_VES2 "Network ECU config data for Audio and Telematics-C";
BA_ "FlexKomIsMotorola" SG_ 994 NetCfg_VES2 1;
BA_ "GenSigSNA" SG_ 994 NetCfg_VES2 "0h";
BA_ "GenSigSendType" SG_ 994 NetCfg_DVD 5;
BA_ "GenSigCycleTime" SG_ 994 NetCfg_DVD 2000;
BA_ "FlexKomSigStartValue" SG_ 994 NetCfg_DVD "030000h";
BA_ "GenSigTimeout_RF_HUB" SG_ 994 NetCfg_DVD 21000;
BA_ "FlexKomSID" SG_ 994 NetCfg_DVD 40;
BA_ "FlexKomSigStartPos" SG_ 994 NetCfg_DVD 7;
BA_ "FlexKomSigLaenge" SG_ 994 NetCfg_DVD 24;
BA_ "FlexKomSigName" SG_ 994 NetCfg_DVD "NET_CFG_DATA_AT";
BA_ "FlexKomComment" SG_ 994 NetCfg_DVD "Network ECU config data for Audio and Telematics-C";
BA_ "FlexKomIsMotorola" SG_ 994 NetCfg_DVD 1;
BA_ "GenSigSNA" SG_ 994 NetCfg_DVD "0h";
BA_ "GenSigSendType" SG_ 994 NetCfg_HFM 5;
BA_ "GenSigCycleTime" SG_ 994 NetCfg_HFM 2000;
BA_ "FlexKomSigStartValue" SG_ 994 NetCfg_HFM "030000h";
BA_ "FlexKomSID" SG_ 994 NetCfg_HFM 40;
BA_ "FlexKomSigStartPos" SG_ 994 NetCfg_HFM 7;
BA_ "FlexKomSigLaenge" SG_ 994 NetCfg_HFM 24;
BA_ "FlexKomSigName" SG_ 994 NetCfg_HFM "NET_CFG_DATA_AT";
BA_ "FlexKomComment" SG_ 994 NetCfg_HFM "Network ECU config data for Audio and Telematics-C";
BA_ "FlexKomIsMotorola" SG_ 994 NetCfg_HFM 1;
BA_ "GenSigSNA" SG_ 994 NetCfg_HFM "0h";
BA_ "GenSigSendType" SG_ 995 NET_CFG_STAT_INT 5;
BA_ "GenSigCycleTime" SG_ 995 NET_CFG_STAT_INT 2000;
BA_ "FlexKomSigStartValue" SG_ 995 NET_CFG_STAT_INT "0300000000000000h";
BA_ "GenSigStartValue" SG_ 995 NET_CFG_STAT_INT 3;
BA_ "GenSigTimeout_RF_HUB" SG_ 995 NET_CFG_STAT_INT 21000;
BA_ "GenSigTimeout_IC" SG_ 995 NET_CFG_STAT_INT 21000;
BA_ "FlexKomSID" SG_ 995 NET_CFG_STAT_INT 38;
BA_ "FlexKomSigStartPos" SG_ 995 NET_CFG_STAT_INT 7;
BA_ "FlexKomSigLaenge" SG_ 995 NET_CFG_STAT_INT 64;
BA_ "FlexKomSigName" SG_ 995 NET_CFG_STAT_INT "NET_CFG_DATA_INT";
BA_ "FlexKomComment" SG_ 995 NET_CFG_STAT_INT "Network ECU config data for interior";
BA_ "FlexKomIsMotorola" SG_ 995 NET_CFG_STAT_INT 1;
BA_ "GenSigSNA" SG_ 995 NET_CFG_STAT_INT "3h";
BA_ "GenSigSendType" SG_ 995 NetCfg_RBSS 5;
BA_ "GenSigCycleTime" SG_ 995 NetCfg_RBSS 2000;
BA_ "FlexKomSigStartValue" SG_ 995 NetCfg_RBSS "0300000000000000h";
BA_ "GenSigTimeout_RF_HUB" SG_ 995 NetCfg_RBSS 21000;
BA_ "FlexKomSID" SG_ 995 NetCfg_RBSS 38;
BA_ "FlexKomSigStartPos" SG_ 995 NetCfg_RBSS 7;
BA_ "FlexKomSigLaenge" SG_ 995 NetCfg_RBSS 64;
BA_ "FlexKomSigName" SG_ 995 NetCfg_RBSS "NET_CFG_DATA_INT";
BA_ "FlexKomComment" SG_ 995 NetCfg_RBSS "Network ECU config data for interior";
BA_ "FlexKomIsMotorola" SG_ 995 NetCfg_RBSS 1;
BA_ "GenSigSNA" SG_ 995 NetCfg_RBSS "0h";
BA_ "GenSigSendType" SG_ 995 NetCfg_BSM 5;
BA_ "GenSigCycleTime" SG_ 995 NetCfg_BSM 2000;
BA_ "FlexKomSigStartValue" SG_ 995 NetCfg_BSM "0300000000000000h";
BA_ "GenSigTimeout_RF_HUB" SG_ 995 NetCfg_BSM 21000;
BA_ "GenSigTimeout_IC" SG_ 995 NetCfg_BSM 21000;
BA_ "FlexKomSID" SG_ 995 NetCfg_BSM 38;
BA_ "FlexKomSigStartPos" SG_ 995 NetCfg_BSM 7;
BA_ "FlexKomSigLaenge" SG_ 995 NetCfg_BSM 64;
BA_ "FlexKomSigName" SG_ 995 NetCfg_BSM "NET_CFG_DATA_INT";
BA_ "FlexKomComment" SG_ 995 NetCfg_BSM "Network ECU config data for interior";
BA_ "FlexKomIsMotorola" SG_ 995 NetCfg_BSM 1;
BA_ "GenSigSNA" SG_ 995 NetCfg_BSM "0h";
BA_ "GenSigSendType" SG_ 995 NetCfg_CBC_IN 5;
BA_ "GenSigCycleTime" SG_ 995 NetCfg_CBC_IN 2000;
BA_ "FlexKomSigStartValue" SG_ 995 NetCfg_CBC_IN "0300000000000000h";
BA_ "GenSigTimeout_RF_HUB" SG_ 995 NetCfg_CBC_IN 21000;
BA_ "GenSigTimeout_IC" SG_ 995 NetCfg_CBC_IN 21000;
BA_ "FlexKomSID" SG_ 995 NetCfg_CBC_IN 38;
BA_ "FlexKomSigStartPos" SG_ 995 NetCfg_CBC_IN 7;
BA_ "FlexKomSigLaenge" SG_ 995 NetCfg_CBC_IN 64;
BA_ "FlexKomSigName" SG_ 995 NetCfg_CBC_IN "NET_CFG_DATA_INT";
BA_ "FlexKomComment" SG_ 995 NetCfg_CBC_IN "Network ECU config data for interior";
BA_ "FlexKomIsMotorola" SG_ 995 NetCfg_CBC_IN 1;
BA_ "GenSigSNA" SG_ 995 NetCfg_CBC_IN "0h";
BA_ "GenSigSendType" SG_ 995 NetCfg_CSWM 5;
BA_ "GenSigCycleTime" SG_ 995 NetCfg_CSWM 2000;
BA_ "FlexKomSigStartValue" SG_ 995 NetCfg_CSWM "0300000000000000h";
BA_ "GenSigTimeout_RF_HUB" SG_ 995 NetCfg_CSWM 21000;
BA_ "GenSigTimeout_IC" SG_ 995 NetCfg_CSWM 21000;
BA_ "FlexKomSID" SG_ 995 NetCfg_CSWM 38;
BA_ "FlexKomSigStartPos" SG_ 995 NetCfg_CSWM 7;
BA_ "FlexKomSigLaenge" SG_ 995 NetCfg_CSWM 64;
BA_ "FlexKomSigName" SG_ 995 NetCfg_CSWM "NET_CFG_DATA_INT";
BA_ "FlexKomComment" SG_ 995 NetCfg_CSWM "Network ECU config data for interior";
BA_ "FlexKomIsMotorola" SG_ 995 NetCfg_CSWM 1;
BA_ "GenSigSNA" SG_ 995 NetCfg_CSWM "0h";
BA_ "GenSigSendType" SG_ 995 NetCfg_DCM_DR 5;
BA_ "GenSigCycleTime" SG_ 995 NetCfg_DCM_DR 2000;
BA_ "FlexKomSigStartValue" SG_ 995 NetCfg_DCM_DR "0300000000000000h";
BA_ "GenSigTimeout_RF_HUB" SG_ 995 NetCfg_DCM_DR 21000;
BA_ "GenSigTimeout_IC" SG_ 995 NetCfg_DCM_DR 21000;
BA_ "FlexKomSID" SG_ 995 NetCfg_DCM_DR 38;
BA_ "FlexKomSigStartPos" SG_ 995 NetCfg_DCM_DR 7;
BA_ "FlexKomSigLaenge" SG_ 995 NetCfg_DCM_DR 64;
BA_ "FlexKomSigName" SG_ 995 NetCfg_DCM_DR "NET_CFG_DATA_INT";
BA_ "FlexKomComment" SG_ 995 NetCfg_DCM_DR "Network ECU config data for interior";
BA_ "FlexKomIsMotorola" SG_ 995 NetCfg_DCM_DR 1;
BA_ "GenSigSNA" SG_ 995 NetCfg_DCM_DR "0h";
BA_ "GenSigSendType" SG_ 995 NetCfg_DCM_PASS 5;
BA_ "GenSigCycleTime" SG_ 995 NetCfg_DCM_PASS 2000;
BA_ "FlexKomSigStartValue" SG_ 995 NetCfg_DCM_PASS "0300000000000000h";
BA_ "GenSigTimeout_RF_HUB" SG_ 995 NetCfg_DCM_PASS 21000;
BA_ "GenSigTimeout_IC" SG_ 995 NetCfg_DCM_PASS 21000;
BA_ "FlexKomSID" SG_ 995 NetCfg_DCM_PASS 38;
BA_ "FlexKomSigStartPos" SG_ 995 NetCfg_DCM_PASS 7;
BA_ "FlexKomSigLaenge" SG_ 995 NetCfg_DCM_PASS 64;
BA_ "FlexKomSigName" SG_ 995 NetCfg_DCM_PASS "NET_CFG_DATA_INT";
BA_ "FlexKomComment" SG_ 995 NetCfg_DCM_PASS "Network ECU config data for interior";
BA_ "FlexKomIsMotorola" SG_ 995 NetCfg_DCM_PASS 1;
BA_ "GenSigSNA" SG_ 995 NetCfg_DCM_PASS "0h";
BA_ "GenSigSendType" SG_ 995 NetCfg_DCM_RL 5;
BA_ "GenSigCycleTime" SG_ 995 NetCfg_DCM_RL 2000;
BA_ "FlexKomSigStartValue" SG_ 995 NetCfg_DCM_RL "0300000000000000h";
BA_ "GenSigTimeout_RF_HUB" SG_ 995 NetCfg_DCM_RL 21000;
BA_ "GenSigTimeout_IC" SG_ 995 NetCfg_DCM_RL 21000;
BA_ "FlexKomSID" SG_ 995 NetCfg_DCM_RL 38;
BA_ "FlexKomSigStartPos" SG_ 995 NetCfg_DCM_RL 7;
BA_ "FlexKomSigLaenge" SG_ 995 NetCfg_DCM_RL 64;
BA_ "FlexKomSigName" SG_ 995 NetCfg_DCM_RL "NET_CFG_DATA_INT";
BA_ "FlexKomComment" SG_ 995 NetCfg_DCM_RL "Network ECU config data for interior";
BA_ "FlexKomIsMotorola" SG_ 995 NetCfg_DCM_RL 1;
BA_ "GenSigSNA" SG_ 995 NetCfg_DCM_RL "0h";
BA_ "GenSigSendType" SG_ 995 NetCfg_DCM_RR 5;
BA_ "GenSigCycleTime" SG_ 995 NetCfg_DCM_RR 2000;
BA_ "FlexKomSigStartValue" SG_ 995 NetCfg_DCM_RR "0300000000000000h";
BA_ "GenSigTimeout_RF_HUB" SG_ 995 NetCfg_DCM_RR 21000;
BA_ "GenSigTimeout_IC" SG_ 995 NetCfg_DCM_RR 21000;
BA_ "FlexKomSID" SG_ 995 NetCfg_DCM_RR 38;
BA_ "FlexKomSigStartPos" SG_ 995 NetCfg_DCM_RR 7;
BA_ "FlexKomSigLaenge" SG_ 995 NetCfg_DCM_RR 64;
BA_ "FlexKomSigName" SG_ 995 NetCfg_DCM_RR "NET_CFG_DATA_INT";
BA_ "FlexKomComment" SG_ 995 NetCfg_DCM_RR "Network ECU config data for interior";
BA_ "FlexKomIsMotorola" SG_ 995 NetCfg_DCM_RR 1;
BA_ "GenSigSNA" SG_ 995 NetCfg_DCM_RR "0h";
BA_ "GenSigSendType" SG_ 995 NetCfg_HVAC 5;
BA_ "GenSigCycleTime" SG_ 995 NetCfg_HVAC 2000;
BA_ "FlexKomSigStartValue" SG_ 995 NetCfg_HVAC "0300000000000000h";
BA_ "GenSigTimeout_RF_HUB" SG_ 995 NetCfg_HVAC 21000;
BA_ "GenSigTimeout_IC" SG_ 995 NetCfg_HVAC 21000;
BA_ "FlexKomSID" SG_ 995 NetCfg_HVAC 38;
BA_ "FlexKomSigStartPos" SG_ 995 NetCfg_HVAC 7;
BA_ "FlexKomSigLaenge" SG_ 995 NetCfg_HVAC 64;
BA_ "FlexKomSigName" SG_ 995 NetCfg_HVAC "NET_CFG_DATA_INT";
BA_ "FlexKomComment" SG_ 995 NetCfg_HVAC "Network ECU config data for interior";
BA_ "FlexKomIsMotorola" SG_ 995 NetCfg_HVAC 1;
BA_ "GenSigSNA" SG_ 995 NetCfg_HVAC "0h";
BA_ "GenSigSendType" SG_ 995 NetCfg_MSM 5;
BA_ "GenSigCycleTime" SG_ 995 NetCfg_MSM 2000;
BA_ "FlexKomSigStartValue" SG_ 995 NetCfg_MSM "0300000000000000h";
BA_ "GenSigTimeout_RF_HUB" SG_ 995 NetCfg_MSM 21000;
BA_ "GenSigTimeout_IC" SG_ 995 NetCfg_MSM 21000;
BA_ "FlexKomSID" SG_ 995 NetCfg_MSM 38;
BA_ "FlexKomSigStartPos" SG_ 995 NetCfg_MSM 7;
BA_ "FlexKomSigLaenge" SG_ 995 NetCfg_MSM 64;
BA_ "FlexKomSigName" SG_ 995 NetCfg_MSM "NET_CFG_DATA_INT";
BA_ "FlexKomComment" SG_ 995 NetCfg_MSM "Network ECU config data for interior";
BA_ "FlexKomIsMotorola" SG_ 995 NetCfg_MSM 1;
BA_ "GenSigSNA" SG_ 995 NetCfg_MSM "0h";
BA_ "GenSigSendType" SG_ 995 NetCfg_PLG 5;
BA_ "GenSigCycleTime" SG_ 995 NetCfg_PLG 2000;
BA_ "FlexKomSigStartValue" SG_ 995 NetCfg_PLG "0300000000000000h";
BA_ "GenSigTimeout_RF_HUB" SG_ 995 NetCfg_PLG 21000;
BA_ "GenSigTimeout_IC" SG_ 995 NetCfg_PLG 21000;
BA_ "FlexKomSID" SG_ 995 NetCfg_PLG 38;
BA_ "FlexKomSigStartPos" SG_ 995 NetCfg_PLG 7;
BA_ "FlexKomSigLaenge" SG_ 995 NetCfg_PLG 64;
BA_ "FlexKomSigName" SG_ 995 NetCfg_PLG "NET_CFG_DATA_INT";
BA_ "FlexKomComment" SG_ 995 NetCfg_PLG "Network ECU config data for interior";
BA_ "FlexKomIsMotorola" SG_ 995 NetCfg_PLG 1;
BA_ "GenSigSNA" SG_ 995 NetCfg_PLG "0h";
BA_ "GenSigSendType" SG_ 995 NetCfg_VTM 5;
BA_ "GenSigCycleTime" SG_ 995 NetCfg_VTM 2000;
BA_ "FlexKomSigStartValue" SG_ 995 NetCfg_VTM "0300000000000000h";
BA_ "GenSigTimeout_RF_HUB" SG_ 995 NetCfg_VTM 21000;
BA_ "FlexKomSID" SG_ 995 NetCfg_VTM 38;
BA_ "FlexKomSigStartPos" SG_ 995 NetCfg_VTM 7;
BA_ "FlexKomSigLaenge" SG_ 995 NetCfg_VTM 64;
BA_ "FlexKomSigName" SG_ 995 NetCfg_VTM "NET_CFG_DATA_INT";
BA_ "FlexKomComment" SG_ 995 NetCfg_VTM "Network ECU config data for interior";
BA_ "FlexKomIsMotorola" SG_ 995 NetCfg_VTM 1;
BA_ "GenSigSNA" SG_ 995 NetCfg_VTM "0h";
BA_ "GenSigSendType" SG_ 995 NetCfg_PSD_LT 5;
BA_ "GenSigCycleTime" SG_ 995 NetCfg_PSD_LT 2000;
BA_ "FlexKomSigStartValue" SG_ 995 NetCfg_PSD_LT "0300000000000000h";
BA_ "GenSigTimeout_RF_HUB" SG_ 995 NetCfg_PSD_LT 21000;
BA_ "GenSigTimeout_IC" SG_ 995 NetCfg_PSD_LT 21000;
BA_ "FlexKomSID" SG_ 995 NetCfg_PSD_LT 38;
BA_ "FlexKomSigStartPos" SG_ 995 NetCfg_PSD_LT 7;
BA_ "FlexKomSigLaenge" SG_ 995 NetCfg_PSD_LT 64;
BA_ "FlexKomSigName" SG_ 995 NetCfg_PSD_LT "NET_CFG_DATA_INT";
BA_ "FlexKomComment" SG_ 995 NetCfg_PSD_LT "Network ECU config data for interior";
BA_ "FlexKomIsMotorola" SG_ 995 NetCfg_PSD_LT 1;
BA_ "GenSigSNA" SG_ 995 NetCfg_PSD_LT "0h";
BA_ "GenSigSendType" SG_ 995 NetCfg_PSD_RT 5;
BA_ "GenSigCycleTime" SG_ 995 NetCfg_PSD_RT 2000;
BA_ "FlexKomSigStartValue" SG_ 995 NetCfg_PSD_RT "0300000000000000h";
BA_ "GenSigTimeout_RF_HUB" SG_ 995 NetCfg_PSD_RT 21000;
BA_ "GenSigTimeout_IC" SG_ 995 NetCfg_PSD_RT 21000;
BA_ "FlexKomSID" SG_ 995 NetCfg_PSD_RT 38;
BA_ "FlexKomSigStartPos" SG_ 995 NetCfg_PSD_RT 7;
BA_ "FlexKomSigLaenge" SG_ 995 NetCfg_PSD_RT 64;
BA_ "FlexKomSigName" SG_ 995 NetCfg_PSD_RT "NET_CFG_DATA_INT";
BA_ "FlexKomComment" SG_ 995 NetCfg_PSD_RT "Network ECU config data for interior";
BA_ "FlexKomIsMotorola" SG_ 995 NetCfg_PSD_RT 1;
BA_ "GenSigSNA" SG_ 995 NetCfg_PSD_RT "0h";
BA_ "GenSigSendType" SG_ 995 NetCfg_FSM 5;
BA_ "GenSigCycleTime" SG_ 995 NetCfg_FSM 2000;
BA_ "FlexKomSigStartValue" SG_ 995 NetCfg_FSM "0300000000000000h";
BA_ "GenSigTimeout_RF_HUB" SG_ 995 NetCfg_FSM 21000;
BA_ "GenSigTimeout_IC" SG_ 995 NetCfg_FSM 21000;
BA_ "FlexKomSID" SG_ 995 NetCfg_FSM 38;
BA_ "FlexKomSigStartPos" SG_ 995 NetCfg_FSM 7;
BA_ "FlexKomSigLaenge" SG_ 995 NetCfg_FSM 64;
BA_ "FlexKomSigName" SG_ 995 NetCfg_FSM "NET_CFG_DATA_INT";
BA_ "FlexKomComment" SG_ 995 NetCfg_FSM "Network ECU config data for interior";
BA_ "FlexKomIsMotorola" SG_ 995 NetCfg_FSM 1;
BA_ "GenSigSNA" SG_ 995 NetCfg_FSM "0h";
BA_ "GenSigSendType" SG_ 995 NetCfg_PTCM 5;
BA_ "GenSigCycleTime" SG_ 995 NetCfg_PTCM 2000;
BA_ "FlexKomSigStartValue" SG_ 995 NetCfg_PTCM "0300000000000000h";
BA_ "GenSigTimeout_RF_HUB" SG_ 995 NetCfg_PTCM 21000;
BA_ "GenSigTimeout_IC" SG_ 995 NetCfg_PTCM 21000;
BA_ "FlexKomSID" SG_ 995 NetCfg_PTCM 38;
BA_ "FlexKomSigStartPos" SG_ 995 NetCfg_PTCM 7;
BA_ "FlexKomSigLaenge" SG_ 995 NetCfg_PTCM 64;
BA_ "FlexKomSigName" SG_ 995 NetCfg_PTCM "NET_CFG_DATA_INT";
BA_ "FlexKomComment" SG_ 995 NetCfg_PTCM "Network ECU config data for interior";
BA_ "FlexKomIsMotorola" SG_ 995 NetCfg_PTCM 1;
BA_ "GenSigSNA" SG_ 995 NetCfg_PTCM "0h";
BA_ "GenSigSendType" SG_ 995 NetCfg_RBC 5;
BA_ "GenSigCycleTime" SG_ 995 NetCfg_RBC 2000;
BA_ "FlexKomSigStartValue" SG_ 995 NetCfg_RBC "0300000000000000h";
BA_ "GenSigTimeout_RF_HUB" SG_ 995 NetCfg_RBC 21000;
BA_ "GenSigTimeout_IC" SG_ 995 NetCfg_RBC 21000;
BA_ "FlexKomSID" SG_ 995 NetCfg_RBC 38;
BA_ "FlexKomSigStartPos" SG_ 995 NetCfg_RBC 7;
BA_ "FlexKomSigLaenge" SG_ 995 NetCfg_RBC 64;
BA_ "FlexKomSigName" SG_ 995 NetCfg_RBC "NET_CFG_DATA_INT";
BA_ "FlexKomComment" SG_ 995 NetCfg_RBC "Network ECU config data for interior";
BA_ "FlexKomIsMotorola" SG_ 995 NetCfg_RBC 1;
BA_ "GenSigSNA" SG_ 995 NetCfg_RBC "0h";
BA_ "GenSigSendType" SG_ 995 NetCfg_DTV 5;
BA_ "GenSigCycleTime" SG_ 995 NetCfg_DTV 2000;
BA_ "FlexKomSigStartValue" SG_ 995 NetCfg_DTV "0300000000000000h";
BA_ "GenSigTimeout_RF_HUB" SG_ 995 NetCfg_DTV 21000;
BA_ "FlexKomSID" SG_ 995 NetCfg_DTV 38;
BA_ "FlexKomSigStartPos" SG_ 995 NetCfg_DTV 7;
BA_ "FlexKomSigLaenge" SG_ 995 NetCfg_DTV 64;
BA_ "FlexKomSigName" SG_ 995 NetCfg_DTV "NET_CFG_DATA_INT";
BA_ "FlexKomComment" SG_ 995 NetCfg_DTV "Network ECU config data for interior";
BA_ "FlexKomIsMotorola" SG_ 995 NetCfg_DTV 1;
BA_ "GenSigSNA" SG_ 995 NetCfg_DTV "0h";
BA_ "GenSigSendType" SG_ 995 NetCfg_TGW 5;
BA_ "GenSigCycleTime" SG_ 995 NetCfg_TGW 2000;
BA_ "FlexKomSigStartValue" SG_ 995 NetCfg_TGW "0300000000000000h";
BA_ "GenSigTimeout_RF_HUB" SG_ 995 NetCfg_TGW 21000;
BA_ "GenSigTimeout_IC" SG_ 995 NetCfg_TGW 21000;
BA_ "FlexKomSID" SG_ 995 NetCfg_TGW 38;
BA_ "FlexKomSigStartPos" SG_ 995 NetCfg_TGW 7;
BA_ "FlexKomSigLaenge" SG_ 995 NetCfg_TGW 64;
BA_ "FlexKomSigName" SG_ 995 NetCfg_TGW "NET_CFG_DATA_INT";
BA_ "FlexKomComment" SG_ 995 NetCfg_TGW "Network ECU config data for interior";
BA_ "FlexKomIsMotorola" SG_ 995 NetCfg_TGW 1;
BA_ "GenSigSNA" SG_ 995 NetCfg_TGW "0h";
BA_ "GenSigSendType" SG_ 995 NetCfg_CLOCK 5;
BA_ "GenSigCycleTime" SG_ 995 NetCfg_CLOCK 2000;
BA_ "FlexKomSigStartValue" SG_ 995 NetCfg_CLOCK "0300000000000000h";
BA_ "GenSigTimeout_RF_HUB" SG_ 995 NetCfg_CLOCK 21000;
BA_ "FlexKomSID" SG_ 995 NetCfg_CLOCK 38;
BA_ "FlexKomSigStartPos" SG_ 995 NetCfg_CLOCK 7;
BA_ "FlexKomSigLaenge" SG_ 995 NetCfg_CLOCK 64;
BA_ "FlexKomSigName" SG_ 995 NetCfg_CLOCK "NET_CFG_DATA_INT";
BA_ "FlexKomComment" SG_ 995 NetCfg_CLOCK "Network ECU config data for interior";
BA_ "FlexKomIsMotorola" SG_ 995 NetCfg_CLOCK 1;
BA_ "GenSigSNA" SG_ 995 NetCfg_CLOCK "0h";
BA_ "GenSigSendType" SG_ 995 NetCfg_VSIM 5;
BA_ "GenSigCycleTime" SG_ 995 NetCfg_VSIM 2000;
BA_ "FlexKomSigStartValue" SG_ 995 NetCfg_VSIM "0300000000000000h";
BA_ "GenSigTimeout_RF_HUB" SG_ 995 NetCfg_VSIM 21000;
BA_ "GenSigTimeout_IC" SG_ 995 NetCfg_VSIM 21000;
BA_ "FlexKomSID" SG_ 995 NetCfg_VSIM 38;
BA_ "FlexKomSigStartPos" SG_ 995 NetCfg_VSIM 7;
BA_ "FlexKomSigLaenge" SG_ 995 NetCfg_VSIM 64;
BA_ "FlexKomSigName" SG_ 995 NetCfg_VSIM "NET_CFG_DATA_INT";
BA_ "FlexKomComment" SG_ 995 NetCfg_VSIM "Network ECU config data for interior";
BA_ "FlexKomIsMotorola" SG_ 995 NetCfg_VSIM 1;
BA_ "GenSigSNA" SG_ 995 NetCfg_VSIM "0h";
BA_ "GenSigSendType" SG_ 995 NetCfg_ITM 5;
BA_ "GenSigCycleTime" SG_ 995 NetCfg_ITM 2000;
BA_ "FlexKomSigStartValue" SG_ 995 NetCfg_ITM "0300000000000000h";
BA_ "GenSigTimeout_RF_HUB" SG_ 995 NetCfg_ITM 21000;
BA_ "GenSigTimeout_IC" SG_ 995 NetCfg_ITM 21000;
BA_ "FlexKomSID" SG_ 995 NetCfg_ITM 38;
BA_ "FlexKomSigStartPos" SG_ 995 NetCfg_ITM 7;
BA_ "FlexKomSigLaenge" SG_ 995 NetCfg_ITM 64;
BA_ "FlexKomSigName" SG_ 995 NetCfg_ITM "NET_CFG_DATA_INT";
BA_ "FlexKomComment" SG_ 995 NetCfg_ITM "Network ECU config data for interior";
BA_ "FlexKomIsMotorola" SG_ 995 NetCfg_ITM 1;
BA_ "GenSigSNA" SG_ 995 NetCfg_ITM "0h";
BA_ "GenSigSendType" SG_ 995 NetCfg_AMP_I 5;
BA_ "GenSigCycleTime" SG_ 995 NetCfg_AMP_I 2000;
BA_ "FlexKomSigStartValue" SG_ 995 NetCfg_AMP_I "0300000000000000h";
BA_ "GenSigTimeout_RF_HUB" SG_ 995 NetCfg_AMP_I 21000;
BA_ "FlexKomSID" SG_ 995 NetCfg_AMP_I 38;
BA_ "FlexKomSigStartPos" SG_ 995 NetCfg_AMP_I 7;
BA_ "FlexKomSigLaenge" SG_ 995 NetCfg_AMP_I 64;
BA_ "FlexKomSigName" SG_ 995 NetCfg_AMP_I "NET_CFG_DATA_INT";
BA_ "FlexKomComment" SG_ 995 NetCfg_AMP_I "Network ECU config data for interior";
BA_ "FlexKomIsMotorola" SG_ 995 NetCfg_AMP_I 1;
BA_ "GenSigSNA" SG_ 995 NetCfg_AMP_I "0h";
BA_ "GenSigSendType" SG_ 995 NetCfg_DVD_CDM 5;
BA_ "GenSigCycleTime" SG_ 995 NetCfg_DVD_CDM 2000;
BA_ "FlexKomSigStartValue" SG_ 995 NetCfg_DVD_CDM "0300000000000000h";
BA_ "GenSigTimeout_RF_HUB" SG_ 995 NetCfg_DVD_CDM 21000;
BA_ "FlexKomSID" SG_ 995 NetCfg_DVD_CDM 38;
BA_ "FlexKomSigStartPos" SG_ 995 NetCfg_DVD_CDM 7;
BA_ "FlexKomSigLaenge" SG_ 995 NetCfg_DVD_CDM 64;
BA_ "FlexKomSigName" SG_ 995 NetCfg_DVD_CDM "NET_CFG_DATA_INT";
BA_ "FlexKomComment" SG_ 995 NetCfg_DVD_CDM "Network ECU config data for interior";
BA_ "FlexKomIsMotorola" SG_ 995 NetCfg_DVD_CDM 1;
BA_ "GenSigSNA" SG_ 995 NetCfg_DVD_CDM "0h";
BA_ "GenSigSendType" SG_ 995 NetCfg_HFM_CTM 5;
BA_ "GenSigCycleTime" SG_ 995 NetCfg_HFM_CTM 2000;
BA_ "FlexKomSigStartValue" SG_ 995 NetCfg_HFM_CTM "0300000000000000h";
BA_ "GenSigTimeout_RF_HUB" SG_ 995 NetCfg_HFM_CTM 21000;
BA_ "FlexKomSID" SG_ 995 NetCfg_HFM_CTM 38;
BA_ "FlexKomSigStartPos" SG_ 995 NetCfg_HFM_CTM 7;
BA_ "FlexKomSigLaenge" SG_ 995 NetCfg_HFM_CTM 64;
BA_ "FlexKomSigName" SG_ 995 NetCfg_HFM_CTM "NET_CFG_DATA_INT";
BA_ "FlexKomComment" SG_ 995 NetCfg_HFM_CTM "Network ECU config data for interior";
BA_ "FlexKomIsMotorola" SG_ 995 NetCfg_HFM_CTM 1;
BA_ "GenSigSNA" SG_ 995 NetCfg_HFM_CTM "0h";
BA_ "GenSigSendType" SG_ 995 NetCfg_ICS_I 5;
BA_ "GenSigCycleTime" SG_ 995 NetCfg_ICS_I 2000;
BA_ "FlexKomSigStartValue" SG_ 995 NetCfg_ICS_I "0300000000000000h";
BA_ "GenSigTimeout_RF_HUB" SG_ 995 NetCfg_ICS_I 21000;
BA_ "FlexKomSID" SG_ 995 NetCfg_ICS_I 38;
BA_ "FlexKomSigStartPos" SG_ 995 NetCfg_ICS_I 7;
BA_ "FlexKomSigLaenge" SG_ 995 NetCfg_ICS_I 64;
BA_ "FlexKomSigName" SG_ 995 NetCfg_ICS_I "NET_CFG_DATA_INT";
BA_ "FlexKomComment" SG_ 995 NetCfg_ICS_I "Network ECU config data for interior";
BA_ "FlexKomIsMotorola" SG_ 995 NetCfg_ICS_I 1;
BA_ "GenSigSNA" SG_ 995 NetCfg_ICS_I "0h";
BA_ "GenSigSendType" SG_ 995 NetCfg_VES2_I 5;
BA_ "GenSigCycleTime" SG_ 995 NetCfg_VES2_I 2000;
BA_ "FlexKomSigStartValue" SG_ 995 NetCfg_VES2_I "0300000000000000h";
BA_ "GenSigTimeout_RF_HUB" SG_ 995 NetCfg_VES2_I 21000;
BA_ "FlexKomSID" SG_ 995 NetCfg_VES2_I 38;
BA_ "FlexKomSigStartPos" SG_ 995 NetCfg_VES2_I 7;
BA_ "FlexKomSigLaenge" SG_ 995 NetCfg_VES2_I 64;
BA_ "FlexKomSigName" SG_ 995 NetCfg_VES2_I "NET_CFG_DATA_INT";
BA_ "FlexKomComment" SG_ 995 NetCfg_VES2_I "Network ECU config data for interior";
BA_ "FlexKomIsMotorola" SG_ 995 NetCfg_VES2_I 1;
BA_ "GenSigSNA" SG_ 995 NetCfg_VES2_I "0h";
BA_ "GenSigSendType" SG_ 995 NetCfg_VES3_I 5;
BA_ "GenSigCycleTime" SG_ 995 NetCfg_VES3_I 2000;
BA_ "FlexKomSigStartValue" SG_ 995 NetCfg_VES3_I "0300000000000000h";
BA_ "GenSigTimeout_RF_HUB" SG_ 995 NetCfg_VES3_I 21000;
BA_ "FlexKomSID" SG_ 995 NetCfg_VES3_I 38;
BA_ "FlexKomSigStartPos" SG_ 995 NetCfg_VES3_I 7;
BA_ "FlexKomSigLaenge" SG_ 995 NetCfg_VES3_I 64;
BA_ "FlexKomSigName" SG_ 995 NetCfg_VES3_I "NET_CFG_DATA_INT";
BA_ "FlexKomComment" SG_ 995 NetCfg_VES3_I "Network ECU config data for interior";
BA_ "FlexKomIsMotorola" SG_ 995 NetCfg_VES3_I 1;
BA_ "GenSigSNA" SG_ 995 NetCfg_VES3_I "0h";
BA_ "GenSigSendType" SG_ 995 NetCfg_CRSM 5;
BA_ "GenSigCycleTime" SG_ 995 NetCfg_CRSM 2000;
BA_ "FlexKomSigStartValue" SG_ 995 NetCfg_CRSM "0300000000000000h";
BA_ "GenSigTimeout_RF_HUB" SG_ 995 NetCfg_CRSM 21000;
BA_ "FlexKomSID" SG_ 995 NetCfg_CRSM 38;
BA_ "FlexKomSigStartPos" SG_ 995 NetCfg_CRSM 7;
BA_ "FlexKomSigLaenge" SG_ 995 NetCfg_CRSM 64;
BA_ "FlexKomSigName" SG_ 995 NetCfg_CRSM "NET_CFG_DATA_INT";
BA_ "FlexKomComment" SG_ 995 NetCfg_CRSM "Network ECU config data for interior";
BA_ "FlexKomIsMotorola" SG_ 995 NetCfg_CRSM 1;
BA_ "GenSigSNA" SG_ 995 NetCfg_CRSM "0h";
BA_ "GenSigSendType" SG_ 995 NetCfg_HVAC_R 5;
BA_ "GenSigCycleTime" SG_ 995 NetCfg_HVAC_R 2000;
BA_ "FlexKomSigStartValue" SG_ 995 NetCfg_HVAC_R "0300000000000000h";
BA_ "GenSigTimeout_RF_HUB" SG_ 995 NetCfg_HVAC_R 21000;
BA_ "FlexKomSID" SG_ 995 NetCfg_HVAC_R 38;
BA_ "FlexKomSigStartPos" SG_ 995 NetCfg_HVAC_R 7;
BA_ "FlexKomSigLaenge" SG_ 995 NetCfg_HVAC_R 64;
BA_ "FlexKomSigName" SG_ 995 NetCfg_HVAC_R "NET_CFG_DATA_INT";
BA_ "FlexKomComment" SG_ 995 NetCfg_HVAC_R "Network ECU config data for interior";
BA_ "FlexKomIsMotorola" SG_ 995 NetCfg_HVAC_R 1;
BA_ "GenSigSNA" SG_ 995 NetCfg_HVAC_R "0h";
BA_ "GenSigSendType" SG_ 996 NET_CFG_STAT_PT 5;
BA_ "GenSigCycleTime" SG_ 996 NET_CFG_STAT_PT 2000;
BA_ "FlexKomSigStartValue" SG_ 996 NET_CFG_STAT_PT "0300000000000000h";
BA_ "GenSigStartValue" SG_ 996 NET_CFG_STAT_PT 3;
BA_ "GenSigTimeout_IC" SG_ 996 NET_CFG_STAT_PT 21000;
BA_ "GenSigTimeout_TPM" SG_ 996 NET_CFG_STAT_PT 21000;
BA_ "GenSigTimeout_EPS" SG_ 996 NET_CFG_STAT_PT 21000;
BA_ "GenSigTimeout_ESM" SG_ 996 NET_CFG_STAT_PT 21000;
BA_ "GenSigTimeout_DTCM" SG_ 996 NET_CFG_STAT_PT 21000;
BA_ "GenSigTimeout_ADCM" SG_ 996 NET_CFG_STAT_PT 21000;
BA_ "GenSigTimeout_ORC" SG_ 996 NET_CFG_STAT_PT 7000;
BA_ "FlexKomSID" SG_ 996 NET_CFG_STAT_PT 39;
BA_ "FlexKomSigStartPos" SG_ 996 NET_CFG_STAT_PT 7;
BA_ "FlexKomSigLaenge" SG_ 996 NET_CFG_STAT_PT 64;
BA_ "FlexKomSigName" SG_ 996 NET_CFG_STAT_PT "NET_CFG_DATA_PT";
BA_ "FlexKomComment" SG_ 996 NET_CFG_STAT_PT "Network ECU config data for Powertrain";
BA_ "FlexKomIsMotorola" SG_ 996 NET_CFG_STAT_PT 1;
BA_ "GenSigSNA" SG_ 996 NET_CFG_STAT_PT "3h";
BA_ "GenSigSendType" SG_ 996 NetCfg_ACC 5;
BA_ "GenSigCycleTime" SG_ 996 NetCfg_ACC 2000;
BA_ "FlexKomSigStartValue" SG_ 996 NetCfg_ACC "0300000000000000h";
BA_ "GenSigTimeout_IC" SG_ 996 NetCfg_ACC 21000;
BA_ "FlexKomSID" SG_ 996 NetCfg_ACC 39;
BA_ "FlexKomSigStartPos" SG_ 996 NetCfg_ACC 7;
BA_ "FlexKomSigLaenge" SG_ 996 NetCfg_ACC 64;
BA_ "FlexKomSigName" SG_ 996 NetCfg_ACC "NET_CFG_DATA_PT";
BA_ "FlexKomComment" SG_ 996 NetCfg_ACC "Network ECU config data for Powertrain";
BA_ "FlexKomIsMotorola" SG_ 996 NetCfg_ACC 1;
BA_ "GenSigSNA" SG_ 996 NetCfg_ACC "0h";
BA_ "GenSigSendType" SG_ 996 NetCfg_ADCM 5;
BA_ "GenSigCycleTime" SG_ 996 NetCfg_ADCM 2000;
BA_ "FlexKomSigStartValue" SG_ 996 NetCfg_ADCM "0300000000000000h";
BA_ "GenSigTimeout_IC" SG_ 996 NetCfg_ADCM 21000;
BA_ "FlexKomSID" SG_ 996 NetCfg_ADCM 39;
BA_ "FlexKomSigStartPos" SG_ 996 NetCfg_ADCM 7;
BA_ "FlexKomSigLaenge" SG_ 996 NetCfg_ADCM 64;
BA_ "FlexKomSigName" SG_ 996 NetCfg_ADCM "NET_CFG_DATA_PT";
BA_ "FlexKomComment" SG_ 996 NetCfg_ADCM "Network ECU config data for Powertrain";
BA_ "FlexKomIsMotorola" SG_ 996 NetCfg_ADCM 1;
BA_ "GenSigSNA" SG_ 996 NetCfg_ADCM "0h";
BA_ "GenSigSendType" SG_ 996 NetCfg_AHLM 5;
BA_ "GenSigCycleTime" SG_ 996 NetCfg_AHLM 2000;
BA_ "FlexKomSigStartValue" SG_ 996 NetCfg_AHLM "0300000000000000h";
BA_ "GenSigTimeout_IC" SG_ 996 NetCfg_AHLM 21000;
BA_ "FlexKomSID" SG_ 996 NetCfg_AHLM 39;
BA_ "FlexKomSigStartPos" SG_ 996 NetCfg_AHLM 7;
BA_ "FlexKomSigLaenge" SG_ 996 NetCfg_AHLM 64;
BA_ "FlexKomSigName" SG_ 996 NetCfg_AHLM "NET_CFG_DATA_PT";
BA_ "FlexKomComment" SG_ 996 NetCfg_AHLM "Network ECU config data for Powertrain";
BA_ "FlexKomIsMotorola" SG_ 996 NetCfg_AHLM 1;
BA_ "GenSigSNA" SG_ 996 NetCfg_AHLM "0h";
BA_ "GenSigSendType" SG_ 996 NetCfg_VSIM_C 5;
BA_ "GenSigCycleTime" SG_ 996 NetCfg_VSIM_C 2000;
BA_ "FlexKomSigStartValue" SG_ 996 NetCfg_VSIM_C "0300000000000000h";
BA_ "GenSigTimeout_IC" SG_ 996 NetCfg_VSIM_C 21000;
BA_ "FlexKomSID" SG_ 996 NetCfg_VSIM_C 39;
BA_ "FlexKomSigStartPos" SG_ 996 NetCfg_VSIM_C 7;
BA_ "FlexKomSigLaenge" SG_ 996 NetCfg_VSIM_C 64;
BA_ "FlexKomSigName" SG_ 996 NetCfg_VSIM_C "NET_CFG_DATA_PT";
BA_ "FlexKomComment" SG_ 996 NetCfg_VSIM_C "Network ECU config data for Powertrain";
BA_ "FlexKomIsMotorola" SG_ 996 NetCfg_VSIM_C 1;
BA_ "GenSigSNA" SG_ 996 NetCfg_VSIM_C "0h";
BA_ "GenSigSendType" SG_ 996 NetCfg_ASCM 5;
BA_ "GenSigCycleTime" SG_ 996 NetCfg_ASCM 2000;
BA_ "FlexKomSigStartValue" SG_ 996 NetCfg_ASCM "0300000000000000h";
BA_ "GenSigTimeout_IC" SG_ 996 NetCfg_ASCM 21000;
BA_ "FlexKomSID" SG_ 996 NetCfg_ASCM 39;
BA_ "FlexKomSigStartPos" SG_ 996 NetCfg_ASCM 7;
BA_ "FlexKomSigLaenge" SG_ 996 NetCfg_ASCM 64;
BA_ "FlexKomSigName" SG_ 996 NetCfg_ASCM "NET_CFG_DATA_PT";
BA_ "FlexKomComment" SG_ 996 NetCfg_ASCM "Network ECU config data for Powertrain";
BA_ "FlexKomIsMotorola" SG_ 996 NetCfg_ASCM 1;
BA_ "GenSigSNA" SG_ 996 NetCfg_ASCM "0h";
BA_ "GenSigSendType" SG_ 996 NetCfg_CBC_PT 5;
BA_ "GenSigCycleTime" SG_ 996 NetCfg_CBC_PT 2000;
BA_ "FlexKomSigStartValue" SG_ 996 NetCfg_CBC_PT "0300000000000000h";
BA_ "GenSigTimeout_IC" SG_ 996 NetCfg_CBC_PT 21000;
BA_ "GenSigTimeout_EPS" SG_ 996 NetCfg_CBC_PT 21000;
BA_ "GenSigTimeout_ORC" SG_ 996 NetCfg_CBC_PT 7000;
BA_ "FlexKomSID" SG_ 996 NetCfg_CBC_PT 39;
BA_ "FlexKomSigStartPos" SG_ 996 NetCfg_CBC_PT 7;
BA_ "FlexKomSigLaenge" SG_ 996 NetCfg_CBC_PT 64;
BA_ "FlexKomSigName" SG_ 996 NetCfg_CBC_PT "NET_CFG_DATA_PT";
BA_ "FlexKomComment" SG_ 996 NetCfg_CBC_PT "Network ECU config data for Powertrain";
BA_ "FlexKomIsMotorola" SG_ 996 NetCfg_CBC_PT 1;
BA_ "GenSigSNA" SG_ 996 NetCfg_CBC_PT "0h";
BA_ "GenSigSendType" SG_ 996 NetCfg_DTCM 5;
BA_ "GenSigCycleTime" SG_ 996 NetCfg_DTCM 2000;
BA_ "FlexKomSigStartValue" SG_ 996 NetCfg_DTCM "0300000000000000h";
BA_ "GenSigTimeout_IC" SG_ 996 NetCfg_DTCM 21000;
BA_ "FlexKomSID" SG_ 996 NetCfg_DTCM 39;
BA_ "FlexKomSigStartPos" SG_ 996 NetCfg_DTCM 7;
BA_ "FlexKomSigLaenge" SG_ 996 NetCfg_DTCM 64;
BA_ "FlexKomSigName" SG_ 996 NetCfg_DTCM "NET_CFG_DATA_PT";
BA_ "FlexKomComment" SG_ 996 NetCfg_DTCM "Network ECU config data for Powertrain";
BA_ "FlexKomIsMotorola" SG_ 996 NetCfg_DTCM 1;
BA_ "GenSigSNA" SG_ 996 NetCfg_DTCM "0h";
BA_ "GenSigSendType" SG_ 996 NetCfg_ECM 5;
BA_ "GenSigCycleTime" SG_ 996 NetCfg_ECM 2000;
BA_ "FlexKomSigStartValue" SG_ 996 NetCfg_ECM "0300000000000000h";
BA_ "GenSigTimeout_IC" SG_ 996 NetCfg_ECM 21000;
BA_ "GenSigTimeout_TPM" SG_ 996 NetCfg_ECM 21000;
BA_ "GenSigTimeout_EPS" SG_ 996 NetCfg_ECM 21000;
BA_ "GenSigTimeout_ORC" SG_ 996 NetCfg_ECM 7000;
BA_ "FlexKomSID" SG_ 996 NetCfg_ECM 39;
BA_ "FlexKomSigStartPos" SG_ 996 NetCfg_ECM 7;
BA_ "FlexKomSigLaenge" SG_ 996 NetCfg_ECM 64;
BA_ "FlexKomSigName" SG_ 996 NetCfg_ECM "NET_CFG_DATA_PT";
BA_ "FlexKomComment" SG_ 996 NetCfg_ECM "Network ECU config data for Powertrain";
BA_ "FlexKomIsMotorola" SG_ 996 NetCfg_ECM 1;
BA_ "GenSigSNA" SG_ 996 NetCfg_ECM "0h";
BA_ "GenSigSendType" SG_ 996 NetCfg_EPS 5;
BA_ "GenSigCycleTime" SG_ 996 NetCfg_EPS 2000;
BA_ "FlexKomSigStartValue" SG_ 996 NetCfg_EPS "0300000000000000h";
BA_ "GenSigTimeout_IC" SG_ 996 NetCfg_EPS 21000;
BA_ "FlexKomSID" SG_ 996 NetCfg_EPS 39;
BA_ "FlexKomSigStartPos" SG_ 996 NetCfg_EPS 7;
BA_ "FlexKomSigLaenge" SG_ 996 NetCfg_EPS 64;
BA_ "FlexKomSigName" SG_ 996 NetCfg_EPS "NET_CFG_DATA_PT";
BA_ "FlexKomComment" SG_ 996 NetCfg_EPS "Network ECU config data for Powertrain";
BA_ "FlexKomIsMotorola" SG_ 996 NetCfg_EPS 1;
BA_ "GenSigSNA" SG_ 996 NetCfg_EPS "0h";
BA_ "GenSigSendType" SG_ 996 NetCfg_ESM 5;
BA_ "GenSigCycleTime" SG_ 996 NetCfg_ESM 2000;
BA_ "FlexKomSigStartValue" SG_ 996 NetCfg_ESM "0300000000000000h";
BA_ "GenSigTimeout_IC" SG_ 996 NetCfg_ESM 21000;
BA_ "FlexKomSID" SG_ 996 NetCfg_ESM 39;
BA_ "FlexKomSigStartPos" SG_ 996 NetCfg_ESM 7;
BA_ "FlexKomSigLaenge" SG_ 996 NetCfg_ESM 64;
BA_ "FlexKomSigName" SG_ 996 NetCfg_ESM "NET_CFG_DATA_PT";
BA_ "FlexKomComment" SG_ 996 NetCfg_ESM "Network ECU config data for Powertrain";
BA_ "FlexKomIsMotorola" SG_ 996 NetCfg_ESM 1;
BA_ "GenSigSNA" SG_ 996 NetCfg_ESM "0h";
BA_ "GenSigSendType" SG_ 996 NetCfg_ESC 5;
BA_ "GenSigCycleTime" SG_ 996 NetCfg_ESC 2000;
BA_ "FlexKomSigStartValue" SG_ 996 NetCfg_ESC "0300000000000000h";
BA_ "GenSigTimeout_IC" SG_ 996 NetCfg_ESC 21000;
BA_ "GenSigTimeout_TPM" SG_ 996 NetCfg_ESC 21000;
BA_ "GenSigTimeout_EPS" SG_ 996 NetCfg_ESC 21000;
BA_ "GenSigTimeout_ORC" SG_ 996 NetCfg_ESC 7000;
BA_ "FlexKomSID" SG_ 996 NetCfg_ESC 39;
BA_ "FlexKomSigStartPos" SG_ 996 NetCfg_ESC 7;
BA_ "FlexKomSigLaenge" SG_ 996 NetCfg_ESC 64;
BA_ "FlexKomSigName" SG_ 996 NetCfg_ESC "NET_CFG_DATA_PT";
BA_ "FlexKomComment" SG_ 996 NetCfg_ESC "Network ECU config data for Powertrain";
BA_ "FlexKomIsMotorola" SG_ 996 NetCfg_ESC 1;
BA_ "GenSigSNA" SG_ 996 NetCfg_ESC "0h";
BA_ "GenSigSendType" SG_ 996 NetCfg_EPB 5;
BA_ "GenSigCycleTime" SG_ 996 NetCfg_EPB 2000;
BA_ "FlexKomSigStartValue" SG_ 996 NetCfg_EPB "0300000000000000h";
BA_ "FlexKomSID" SG_ 996 NetCfg_EPB 39;
BA_ "FlexKomSigStartPos" SG_ 996 NetCfg_EPB 7;
BA_ "FlexKomSigLaenge" SG_ 996 NetCfg_EPB 64;
BA_ "FlexKomSigName" SG_ 996 NetCfg_EPB "NET_CFG_DATA_PT";
BA_ "FlexKomComment" SG_ 996 NetCfg_EPB "Network ECU config data for Powertrain";
BA_ "FlexKomIsMotorola" SG_ 996 NetCfg_EPB 1;
BA_ "GenSigSNA" SG_ 996 NetCfg_EPB "0h";
BA_ "GenSigSendType" SG_ 996 NetCfg_RF_HUB 5;
BA_ "GenSigCycleTime" SG_ 996 NetCfg_RF_HUB 2000;
BA_ "FlexKomSigStartValue" SG_ 996 NetCfg_RF_HUB "0300000000000000h";
BA_ "GenSigTimeout_IC" SG_ 996 NetCfg_RF_HUB 21000;
BA_ "GenSigTimeout_TPM" SG_ 996 NetCfg_RF_HUB 21000;
BA_ "FlexKomSID" SG_ 996 NetCfg_RF_HUB 39;
BA_ "FlexKomSigStartPos" SG_ 996 NetCfg_RF_HUB 7;
BA_ "FlexKomSigLaenge" SG_ 996 NetCfg_RF_HUB 64;
BA_ "FlexKomSigName" SG_ 996 NetCfg_RF_HUB "NET_CFG_DATA_PT";
BA_ "FlexKomComment" SG_ 996 NetCfg_RF_HUB "Network ECU config data for Powertrain";
BA_ "FlexKomIsMotorola" SG_ 996 NetCfg_RF_HUB 1;
BA_ "GenSigSNA" SG_ 996 NetCfg_RF_HUB "0h";
BA_ "GenSigSendType" SG_ 996 NetCfg_IC 5;
BA_ "GenSigCycleTime" SG_ 996 NetCfg_IC 2000;
BA_ "FlexKomSigStartValue" SG_ 996 NetCfg_IC "0300000000000000h";
BA_ "GenSigTimeout_IC" SG_ 996 NetCfg_IC 21000;
BA_ "GenSigTimeout_TPM" SG_ 996 NetCfg_IC 21000;
BA_ "GenSigTimeout_EPS" SG_ 996 NetCfg_IC 21000;
BA_ "FlexKomSID" SG_ 996 NetCfg_IC 39;
BA_ "FlexKomSigStartPos" SG_ 996 NetCfg_IC 7;
BA_ "FlexKomSigLaenge" SG_ 996 NetCfg_IC 64;
BA_ "FlexKomSigName" SG_ 996 NetCfg_IC "NET_CFG_DATA_PT";
BA_ "FlexKomComment" SG_ 996 NetCfg_IC "Network ECU config data for Powertrain";
BA_ "FlexKomIsMotorola" SG_ 996 NetCfg_IC 1;
BA_ "GenSigSNA" SG_ 996 NetCfg_IC "0h";
BA_ "GenSigSendType" SG_ 996 NetCfg_DASM 5;
BA_ "GenSigCycleTime" SG_ 996 NetCfg_DASM 2000;
BA_ "FlexKomSigStartValue" SG_ 996 NetCfg_DASM "0300000000000000h";
BA_ "GenSigTimeout_IC" SG_ 996 NetCfg_DASM 21000;
BA_ "FlexKomSID" SG_ 996 NetCfg_DASM 39;
BA_ "FlexKomSigStartPos" SG_ 996 NetCfg_DASM 7;
BA_ "FlexKomSigLaenge" SG_ 996 NetCfg_DASM 64;
BA_ "FlexKomSigName" SG_ 996 NetCfg_DASM "NET_CFG_DATA_PT";
BA_ "FlexKomComment" SG_ 996 NetCfg_DASM "Network ECU config data for Powertrain";
BA_ "FlexKomIsMotorola" SG_ 996 NetCfg_DASM 1;
BA_ "GenSigSNA" SG_ 996 NetCfg_DASM "0h";
BA_ "GenSigSendType" SG_ 996 NetCfg_FDCM 5;
BA_ "GenSigCycleTime" SG_ 996 NetCfg_FDCM 2000;
BA_ "FlexKomSigStartValue" SG_ 996 NetCfg_FDCM "0300000000000000h";
BA_ "FlexKomSID" SG_ 996 NetCfg_FDCM 39;
BA_ "FlexKomSigStartPos" SG_ 996 NetCfg_FDCM 7;
BA_ "FlexKomSigLaenge" SG_ 996 NetCfg_FDCM 64;
BA_ "FlexKomSigName" SG_ 996 NetCfg_FDCM "NET_CFG_DATA_PT";
BA_ "FlexKomComment" SG_ 996 NetCfg_FDCM "Network ECU config data for Powertrain";
BA_ "FlexKomIsMotorola" SG_ 996 NetCfg_FDCM 1;
BA_ "GenSigSNA" SG_ 996 NetCfg_FDCM "0h";
BA_ "GenSigSendType" SG_ 996 NetCfg_EPPM 5;
BA_ "GenSigCycleTime" SG_ 996 NetCfg_EPPM 2000;
BA_ "FlexKomSigStartValue" SG_ 996 NetCfg_EPPM "0300000000000000h";
BA_ "GenSigTimeout_ORC" SG_ 996 NetCfg_EPPM 7000;
BA_ "FlexKomSID" SG_ 996 NetCfg_EPPM 39;
BA_ "FlexKomSigStartPos" SG_ 996 NetCfg_EPPM 7;
BA_ "FlexKomSigLaenge" SG_ 996 NetCfg_EPPM 64;
BA_ "FlexKomSigName" SG_ 996 NetCfg_EPPM "NET_CFG_DATA_PT";
BA_ "FlexKomComment" SG_ 996 NetCfg_EPPM "Network ECU config data for Powertrain";
BA_ "FlexKomIsMotorola" SG_ 996 NetCfg_EPPM 1;
BA_ "GenSigSNA" SG_ 996 NetCfg_EPPM "0h";
BA_ "GenSigSendType" SG_ 996 NetCfg_ORC 5;
BA_ "GenSigCycleTime" SG_ 996 NetCfg_ORC 2000;
BA_ "FlexKomSigStartValue" SG_ 996 NetCfg_ORC "0300000000000000h";
BA_ "GenSigTimeout_IC" SG_ 996 NetCfg_ORC 21000;
BA_ "FlexKomSID" SG_ 996 NetCfg_ORC 39;
BA_ "FlexKomSigStartPos" SG_ 996 NetCfg_ORC 7;
BA_ "FlexKomSigLaenge" SG_ 996 NetCfg_ORC 64;
BA_ "FlexKomSigName" SG_ 996 NetCfg_ORC "NET_CFG_DATA_PT";
BA_ "FlexKomComment" SG_ 996 NetCfg_ORC "Network ECU config data for Powertrain";
BA_ "FlexKomIsMotorola" SG_ 996 NetCfg_ORC 1;
BA_ "GenSigSNA" SG_ 996 NetCfg_ORC "0h";
BA_ "GenSigSendType" SG_ 996 NetCfg_PTS 5;
BA_ "GenSigCycleTime" SG_ 996 NetCfg_PTS 2000;
BA_ "FlexKomSigStartValue" SG_ 996 NetCfg_PTS "0300000000000000h";
BA_ "GenSigTimeout_IC" SG_ 996 NetCfg_PTS 21000;
BA_ "FlexKomSID" SG_ 996 NetCfg_PTS 39;
BA_ "FlexKomSigStartPos" SG_ 996 NetCfg_PTS 7;
BA_ "FlexKomSigLaenge" SG_ 996 NetCfg_PTS 64;
BA_ "FlexKomSigName" SG_ 996 NetCfg_PTS "NET_CFG_DATA_PT";
BA_ "FlexKomComment" SG_ 996 NetCfg_PTS "Network ECU config data for Powertrain";
BA_ "FlexKomIsMotorola" SG_ 996 NetCfg_PTS 1;
BA_ "GenSigSNA" SG_ 996 NetCfg_PTS "0h";
BA_ "GenSigSendType" SG_ 996 NetCfg_RBT_DR 5;
BA_ "GenSigCycleTime" SG_ 996 NetCfg_RBT_DR 2000;
BA_ "FlexKomSigStartValue" SG_ 996 NetCfg_RBT_DR "0300000000000000h";
BA_ "GenSigTimeout_IC" SG_ 996 NetCfg_RBT_DR 21000;
BA_ "FlexKomSID" SG_ 996 NetCfg_RBT_DR 39;
BA_ "FlexKomSigStartPos" SG_ 996 NetCfg_RBT_DR 7;
BA_ "FlexKomSigLaenge" SG_ 996 NetCfg_RBT_DR 64;
BA_ "FlexKomSigName" SG_ 996 NetCfg_RBT_DR "NET_CFG_DATA_PT";
BA_ "FlexKomComment" SG_ 996 NetCfg_RBT_DR "Network ECU config data for Powertrain";
BA_ "FlexKomIsMotorola" SG_ 996 NetCfg_RBT_DR 1;
BA_ "GenSigSNA" SG_ 996 NetCfg_RBT_DR "0h";
BA_ "GenSigSendType" SG_ 996 NetCfg_RBT_PASS 5;
BA_ "GenSigCycleTime" SG_ 996 NetCfg_RBT_PASS 2000;
BA_ "FlexKomSigStartValue" SG_ 996 NetCfg_RBT_PASS "0300000000000000h";
BA_ "GenSigTimeout_IC" SG_ 996 NetCfg_RBT_PASS 21000;
BA_ "FlexKomSID" SG_ 996 NetCfg_RBT_PASS 39;
BA_ "FlexKomSigStartPos" SG_ 996 NetCfg_RBT_PASS 7;
BA_ "FlexKomSigLaenge" SG_ 996 NetCfg_RBT_PASS 64;
BA_ "FlexKomSigName" SG_ 996 NetCfg_RBT_PASS "NET_CFG_DATA_PT";
BA_ "FlexKomComment" SG_ 996 NetCfg_RBT_PASS "Network ECU config data for Powertrain";
BA_ "FlexKomIsMotorola" SG_ 996 NetCfg_RBT_PASS 1;
BA_ "GenSigSNA" SG_ 996 NetCfg_RBT_PASS "0h";
BA_ "GenSigSendType" SG_ 996 NetCfg_SCCM 5;
BA_ "GenSigCycleTime" SG_ 996 NetCfg_SCCM 2000;
BA_ "FlexKomSigStartValue" SG_ 996 NetCfg_SCCM "0300000000000000h";
BA_ "GenSigTimeout_IC" SG_ 996 NetCfg_SCCM 21000;
BA_ "GenSigTimeout_EPS" SG_ 996 NetCfg_SCCM 21000;
BA_ "GenSigTimeout_SCCM" SG_ 996 NetCfg_SCCM 21000;
BA_ "GenSigTimeout_ORC" SG_ 996 NetCfg_SCCM 7000;
BA_ "FlexKomSID" SG_ 996 NetCfg_SCCM 39;
BA_ "FlexKomSigStartPos" SG_ 996 NetCfg_SCCM 7;
BA_ "FlexKomSigLaenge" SG_ 996 NetCfg_SCCM 64;
BA_ "FlexKomSigName" SG_ 996 NetCfg_SCCM "NET_CFG_DATA_PT";
BA_ "FlexKomComment" SG_ 996 NetCfg_SCCM "Network ECU config data for Powertrain";
BA_ "FlexKomIsMotorola" SG_ 996 NetCfg_SCCM 1;
BA_ "GenSigSNA" SG_ 996 NetCfg_SCCM "0h";
BA_ "GenSigSendType" SG_ 996 NetCfg_ELSD 5;
BA_ "GenSigCycleTime" SG_ 996 NetCfg_ELSD 2000;
BA_ "FlexKomSigStartValue" SG_ 996 NetCfg_ELSD "0300000000000000h";
BA_ "GenSigTimeout_IC" SG_ 996 NetCfg_ELSD 21000;
BA_ "FlexKomSID" SG_ 996 NetCfg_ELSD 39;
BA_ "FlexKomSigStartPos" SG_ 996 NetCfg_ELSD 7;
BA_ "FlexKomSigLaenge" SG_ 996 NetCfg_ELSD 64;
BA_ "FlexKomSigName" SG_ 996 NetCfg_ELSD "NET_CFG_DATA_PT";
BA_ "FlexKomComment" SG_ 996 NetCfg_ELSD "Network ECU config data for Powertrain";
BA_ "FlexKomIsMotorola" SG_ 996 NetCfg_ELSD 1;
BA_ "GenSigSNA" SG_ 996 NetCfg_ELSD "0h";
BA_ "GenSigSendType" SG_ 996 NetCfg_TCM 5;
BA_ "GenSigCycleTime" SG_ 996 NetCfg_TCM 2000;
BA_ "FlexKomSigStartValue" SG_ 996 NetCfg_TCM "0300000000000000h";
BA_ "GenSigTimeout_IC" SG_ 996 NetCfg_TCM 21000;
BA_ "GenSigTimeout_ESM" SG_ 996 NetCfg_TCM 21000;
BA_ "GenSigTimeout_ORC" SG_ 996 NetCfg_TCM 7000;
BA_ "FlexKomSID" SG_ 996 NetCfg_TCM 39;
BA_ "FlexKomSigStartPos" SG_ 996 NetCfg_TCM 7;
BA_ "FlexKomSigLaenge" SG_ 996 NetCfg_TCM 64;
BA_ "FlexKomSigName" SG_ 996 NetCfg_TCM "NET_CFG_DATA_PT";
BA_ "FlexKomComment" SG_ 996 NetCfg_TCM "Network ECU config data for Powertrain";
BA_ "FlexKomIsMotorola" SG_ 996 NetCfg_TCM 1;
BA_ "GenSigSNA" SG_ 996 NetCfg_TCM "0h";
BA_ "GenSigSendType" SG_ 996 NetCfg_TPM 5;
BA_ "GenSigCycleTime" SG_ 996 NetCfg_TPM 2000;
BA_ "FlexKomSigStartValue" SG_ 996 NetCfg_TPM "0300000000000000h";
BA_ "GenSigTimeout_IC" SG_ 996 NetCfg_TPM 21000;
BA_ "GenSigTimeout_ORC" SG_ 996 NetCfg_TPM 7000;
BA_ "FlexKomSID" SG_ 996 NetCfg_TPM 39;
BA_ "FlexKomSigStartPos" SG_ 996 NetCfg_TPM 7;
BA_ "FlexKomSigLaenge" SG_ 996 NetCfg_TPM 64;
BA_ "FlexKomSigName" SG_ 996 NetCfg_TPM "NET_CFG_DATA_PT";
BA_ "FlexKomComment" SG_ 996 NetCfg_TPM "Network ECU config data for Powertrain";
BA_ "FlexKomIsMotorola" SG_ 996 NetCfg_TPM 1;
BA_ "GenSigSNA" SG_ 996 NetCfg_TPM "0h";
BA_ "GenSigSendType" SG_ 996 NetCfg_PASS_PT 5;
BA_ "GenSigCycleTime" SG_ 996 NetCfg_PASS_PT 2000;
BA_ "FlexKomSigStartValue" SG_ 996 NetCfg_PASS_PT "0300000000000000h";
BA_ "GenSigTimeout_IC" SG_ 996 NetCfg_PASS_PT 21000;
BA_ "FlexKomSID" SG_ 996 NetCfg_PASS_PT 39;
BA_ "FlexKomSigStartPos" SG_ 996 NetCfg_PASS_PT 7;
BA_ "FlexKomSigLaenge" SG_ 996 NetCfg_PASS_PT 64;
BA_ "FlexKomSigName" SG_ 996 NetCfg_PASS_PT "NET_CFG_DATA_PT";
BA_ "FlexKomComment" SG_ 996 NetCfg_PASS_PT "Network ECU config data for Powertrain";
BA_ "FlexKomIsMotorola" SG_ 996 NetCfg_PASS_PT 1;
BA_ "GenSigSNA" SG_ 996 NetCfg_PASS_PT "0h";
BA_ "GenSigSendType" SG_ 996 NetCfg_AFLS 5;
BA_ "GenSigCycleTime" SG_ 996 NetCfg_AFLS 2000;
BA_ "FlexKomSigStartValue" SG_ 996 NetCfg_AFLS "0300000000000000h";
BA_ "GenSigTimeout_IC" SG_ 996 NetCfg_AFLS 21000;
BA_ "FlexKomSID" SG_ 996 NetCfg_AFLS 39;
BA_ "FlexKomSigStartPos" SG_ 996 NetCfg_AFLS 7;
BA_ "FlexKomSigLaenge" SG_ 996 NetCfg_AFLS 64;
BA_ "FlexKomSigName" SG_ 996 NetCfg_AFLS "NET_CFG_DATA_PT";
BA_ "FlexKomComment" SG_ 996 NetCfg_AFLS "Network ECU config data for Powertrain";
BA_ "FlexKomIsMotorola" SG_ 996 NetCfg_AFLS 1;
BA_ "GenSigSNA" SG_ 996 NetCfg_AFLS "0h";
BA_ "GenSigSendType" SG_ 996 NetCfg_ITBM 5;
BA_ "GenSigCycleTime" SG_ 996 NetCfg_ITBM 2000;
BA_ "FlexKomSigStartValue" SG_ 996 NetCfg_ITBM "0300000000000000h";
BA_ "GenSigTimeout_IC" SG_ 996 NetCfg_ITBM 21000;
BA_ "FlexKomSID" SG_ 996 NetCfg_ITBM 39;
BA_ "FlexKomSigStartPos" SG_ 996 NetCfg_ITBM 7;
BA_ "FlexKomSigLaenge" SG_ 996 NetCfg_ITBM 64;
BA_ "FlexKomSigName" SG_ 996 NetCfg_ITBM "NET_CFG_DATA_PT";
BA_ "FlexKomComment" SG_ 996 NetCfg_ITBM "Network ECU config data for Powertrain";
BA_ "FlexKomIsMotorola" SG_ 996 NetCfg_ITBM 1;
BA_ "GenSigSNA" SG_ 996 NetCfg_ITBM "0h";
BA_ "GenSigSendType" SG_ 996 NetCfg_OCM 5;
BA_ "GenSigCycleTime" SG_ 996 NetCfg_OCM 2000;
BA_ "FlexKomSigStartValue" SG_ 996 NetCfg_OCM "0300000000000000h";
BA_ "FlexKomSID" SG_ 996 NetCfg_OCM 39;
BA_ "FlexKomSigStartPos" SG_ 996 NetCfg_OCM 7;
BA_ "FlexKomSigLaenge" SG_ 996 NetCfg_OCM 64;
BA_ "FlexKomSigName" SG_ 996 NetCfg_OCM "NET_CFG_DATA_PT";
BA_ "FlexKomComment" SG_ 996 NetCfg_OCM "Network ECU config data for Powertrain";
BA_ "FlexKomIsMotorola" SG_ 996 NetCfg_OCM 1;
BA_ "GenSigSNA" SG_ 996 NetCfg_OCM "0h";
BA_ "GenSigSendType" SG_ 996 NetCfg_HaLF 5;
BA_ "GenSigCycleTime" SG_ 996 NetCfg_HaLF 2000;
BA_ "FlexKomSigStartValue" SG_ 996 NetCfg_HaLF "0300000000000000h";
BA_ "GenSigTimeout_EPS" SG_ 996 NetCfg_HaLF 21000;
BA_ "FlexKomSID" SG_ 996 NetCfg_HaLF 39;
BA_ "FlexKomSigStartPos" SG_ 996 NetCfg_HaLF 7;
BA_ "FlexKomSigLaenge" SG_ 996 NetCfg_HaLF 64;
BA_ "FlexKomSigName" SG_ 996 NetCfg_HaLF "NET_CFG_DATA_PT";
BA_ "FlexKomComment" SG_ 996 NetCfg_HaLF "Network ECU config data for Powertrain";
BA_ "FlexKomIsMotorola" SG_ 996 NetCfg_HaLF 1;
BA_ "GenSigSNA" SG_ 996 NetCfg_HaLF "0h";
BA_ "GenSigSendType" SG_ 996 NetCfg_ANC 5;
BA_ "GenSigCycleTime" SG_ 996 NetCfg_ANC 2000;
BA_ "FlexKomSigStartValue" SG_ 996 NetCfg_ANC "0300000000000000h";
BA_ "FlexKomSID" SG_ 996 NetCfg_ANC 39;
BA_ "FlexKomSigStartPos" SG_ 996 NetCfg_ANC 7;
BA_ "FlexKomSigLaenge" SG_ 996 NetCfg_ANC 64;
BA_ "FlexKomSigName" SG_ 996 NetCfg_ANC "NET_CFG_DATA_PT";
BA_ "FlexKomComment" SG_ 996 NetCfg_ANC "Network ECU config data for Powertrain";
BA_ "FlexKomIsMotorola" SG_ 996 NetCfg_ANC 1;
BA_ "GenSigSNA" SG_ 996 NetCfg_ANC "0h";
BA_ "GenSigSendType" SG_ 997 BU_NET_CFG_STAT_AT 1;
BA_ "FlexKomSigStartValue" SG_ 997 BU_NET_CFG_STAT_AT "030000h";
BA_ "GenSigStartValue" SG_ 997 BU_NET_CFG_STAT_AT 3;
BA_ "FlexKomSID" SG_ 997 BU_NET_CFG_STAT_AT 870;
BA_ "FlexKomSigStartPos" SG_ 997 BU_NET_CFG_STAT_AT 7;
BA_ "FlexKomSigLaenge" SG_ 997 BU_NET_CFG_STAT_AT 24;
BA_ "FlexKomSigName" SG_ 997 BU_NET_CFG_STAT_AT "BU_NET_CFG_DATA_AT";
BA_ "FlexKomComment" SG_ 997 BU_NET_CFG_STAT_AT "Backup for network ECU config data for Audio and T";
BA_ "FlexKomIsMotorola" SG_ 997 BU_NET_CFG_STAT_AT 1;
BA_ "GenSigSNA" SG_ 997 BU_NET_CFG_STAT_AT "3h";
BA_ "GenSigSendType" SG_ 997 BU_NetCfg_AMP 1;
BA_ "FlexKomSigStartValue" SG_ 997 BU_NetCfg_AMP "030000h";
BA_ "FlexKomSID" SG_ 997 BU_NetCfg_AMP 870;
BA_ "FlexKomSigStartPos" SG_ 997 BU_NetCfg_AMP 7;
BA_ "FlexKomSigLaenge" SG_ 997 BU_NetCfg_AMP 24;
BA_ "FlexKomSigName" SG_ 997 BU_NetCfg_AMP "BU_NET_CFG_DATA_AT";
BA_ "FlexKomComment" SG_ 997 BU_NetCfg_AMP "Backup for network ECU config data for Audio and T";
BA_ "FlexKomIsMotorola" SG_ 997 BU_NetCfg_AMP 1;
BA_ "GenSigSNA" SG_ 997 BU_NetCfg_AMP "0h";
BA_ "GenSigSendType" SG_ 997 BU_NetCfg_ICS 1;
BA_ "FlexKomSigStartValue" SG_ 997 BU_NetCfg_ICS "030000h";
BA_ "FlexKomSID" SG_ 997 BU_NetCfg_ICS 870;
BA_ "FlexKomSigStartPos" SG_ 997 BU_NetCfg_ICS 7;
BA_ "FlexKomSigLaenge" SG_ 997 BU_NetCfg_ICS 24;
BA_ "FlexKomSigName" SG_ 997 BU_NetCfg_ICS "BU_NET_CFG_DATA_AT";
BA_ "FlexKomComment" SG_ 997 BU_NetCfg_ICS "Backup for network ECU config data for Audio and T";
BA_ "FlexKomIsMotorola" SG_ 997 BU_NetCfg_ICS 1;
BA_ "GenSigSNA" SG_ 997 BU_NetCfg_ICS "0h";
BA_ "GenSigSendType" SG_ 997 BU_NetCfg_PASS 1;
BA_ "FlexKomSigStartValue" SG_ 997 BU_NetCfg_PASS "030000h";
BA_ "FlexKomSID" SG_ 997 BU_NetCfg_PASS 870;
BA_ "FlexKomSigStartPos" SG_ 997 BU_NetCfg_PASS 7;
BA_ "FlexKomSigLaenge" SG_ 997 BU_NetCfg_PASS 24;
BA_ "FlexKomSigName" SG_ 997 BU_NetCfg_PASS "BU_NET_CFG_DATA_AT";
BA_ "FlexKomComment" SG_ 997 BU_NetCfg_PASS "Backup for network ECU config data for Audio and T";
BA_ "FlexKomIsMotorola" SG_ 997 BU_NetCfg_PASS 1;
BA_ "GenSigSNA" SG_ 997 BU_NetCfg_PASS "0h";
BA_ "GenSigSendType" SG_ 997 BU_NetCfg_SDARV 1;
BA_ "FlexKomSigStartValue" SG_ 997 BU_NetCfg_SDARV "030000h";
BA_ "FlexKomSID" SG_ 997 BU_NetCfg_SDARV 870;
BA_ "FlexKomSigStartPos" SG_ 997 BU_NetCfg_SDARV 7;
BA_ "FlexKomSigLaenge" SG_ 997 BU_NetCfg_SDARV 24;
BA_ "FlexKomSigName" SG_ 997 BU_NetCfg_SDARV "BU_NET_CFG_DATA_AT";
BA_ "FlexKomComment" SG_ 997 BU_NetCfg_SDARV "Backup for network ECU config data for Audio and T";
BA_ "FlexKomIsMotorola" SG_ 997 BU_NetCfg_SDARV 1;
BA_ "GenSigSNA" SG_ 997 BU_NetCfg_SDARV "0h";
BA_ "GenSigSendType" SG_ 997 BU_NetCfg_VES3 1;
BA_ "FlexKomSigStartValue" SG_ 997 BU_NetCfg_VES3 "030000h";
BA_ "FlexKomSID" SG_ 997 BU_NetCfg_VES3 870;
BA_ "FlexKomSigStartPos" SG_ 997 BU_NetCfg_VES3 7;
BA_ "FlexKomSigLaenge" SG_ 997 BU_NetCfg_VES3 24;
BA_ "FlexKomSigName" SG_ 997 BU_NetCfg_VES3 "BU_NET_CFG_DATA_AT";
BA_ "FlexKomComment" SG_ 997 BU_NetCfg_VES3 "Backup for network ECU config data for Audio and T";
BA_ "FlexKomIsMotorola" SG_ 997 BU_NetCfg_VES3 1;
BA_ "GenSigSNA" SG_ 997 BU_NetCfg_VES3 "0h";
BA_ "GenSigSendType" SG_ 997 BU_NetCfg_VES2 1;
BA_ "FlexKomSigStartValue" SG_ 997 BU_NetCfg_VES2 "030000h";
BA_ "FlexKomSID" SG_ 997 BU_NetCfg_VES2 870;
BA_ "FlexKomSigStartPos" SG_ 997 BU_NetCfg_VES2 7;
BA_ "FlexKomSigLaenge" SG_ 997 BU_NetCfg_VES2 24;
BA_ "FlexKomSigName" SG_ 997 BU_NetCfg_VES2 "BU_NET_CFG_DATA_AT";
BA_ "FlexKomComment" SG_ 997 BU_NetCfg_VES2 "Backup for network ECU config data for Audio and T";
BA_ "FlexKomIsMotorola" SG_ 997 BU_NetCfg_VES2 1;
BA_ "GenSigSNA" SG_ 997 BU_NetCfg_VES2 "0h";
BA_ "GenSigSendType" SG_ 997 BU_NetCfg_DVD 1;
BA_ "FlexKomSigStartValue" SG_ 997 BU_NetCfg_DVD "030000h";
BA_ "FlexKomSID" SG_ 997 BU_NetCfg_DVD 870;
BA_ "FlexKomSigStartPos" SG_ 997 BU_NetCfg_DVD 7;
BA_ "FlexKomSigLaenge" SG_ 997 BU_NetCfg_DVD 24;
BA_ "FlexKomSigName" SG_ 997 BU_NetCfg_DVD "BU_NET_CFG_DATA_AT";
BA_ "FlexKomComment" SG_ 997 BU_NetCfg_DVD "Backup for network ECU config data for Audio and T";
BA_ "FlexKomIsMotorola" SG_ 997 BU_NetCfg_DVD 1;
BA_ "GenSigSNA" SG_ 997 BU_NetCfg_DVD "0h";
BA_ "GenSigSendType" SG_ 997 BU_NetCfg_HFM 1;
BA_ "FlexKomSigStartValue" SG_ 997 BU_NetCfg_HFM "030000h";
BA_ "FlexKomSID" SG_ 997 BU_NetCfg_HFM 870;
BA_ "FlexKomSigStartPos" SG_ 997 BU_NetCfg_HFM 7;
BA_ "FlexKomSigLaenge" SG_ 997 BU_NetCfg_HFM 24;
BA_ "FlexKomSigName" SG_ 997 BU_NetCfg_HFM "BU_NET_CFG_DATA_AT";
BA_ "FlexKomComment" SG_ 997 BU_NetCfg_HFM "Backup for network ECU config data for Audio and T";
BA_ "FlexKomIsMotorola" SG_ 997 BU_NetCfg_HFM 1;
BA_ "GenSigSNA" SG_ 997 BU_NetCfg_HFM "0h";
BA_ "GenSigSendType" SG_ 998 BU_NET_CFG_STAT_INT 1;
BA_ "FlexKomSigStartValue" SG_ 998 BU_NET_CFG_STAT_INT "0300000000000000h";
BA_ "GenSigStartValue" SG_ 998 BU_NET_CFG_STAT_INT 3;
BA_ "FlexKomSID" SG_ 998 BU_NET_CFG_STAT_INT 871;
BA_ "FlexKomSigStartPos" SG_ 998 BU_NET_CFG_STAT_INT 7;
BA_ "FlexKomSigLaenge" SG_ 998 BU_NET_CFG_STAT_INT 64;
BA_ "FlexKomSigName" SG_ 998 BU_NET_CFG_STAT_INT "BU_NET_CFG_DATA_INT";
BA_ "FlexKomComment" SG_ 998 BU_NET_CFG_STAT_INT "Backup for network ECU config data for interior";
BA_ "FlexKomIsMotorola" SG_ 998 BU_NET_CFG_STAT_INT 1;
BA_ "GenSigSNA" SG_ 998 BU_NET_CFG_STAT_INT "3h";
BA_ "GenSigSendType" SG_ 998 BU_NetCfg_RBSS 1;
BA_ "FlexKomSigStartValue" SG_ 998 BU_NetCfg_RBSS "0300000000000000h";
BA_ "FlexKomSID" SG_ 998 BU_NetCfg_RBSS 871;
BA_ "FlexKomSigStartPos" SG_ 998 BU_NetCfg_RBSS 7;
BA_ "FlexKomSigLaenge" SG_ 998 BU_NetCfg_RBSS 64;
BA_ "FlexKomSigName" SG_ 998 BU_NetCfg_RBSS "BU_NET_CFG_DATA_INT";
BA_ "FlexKomComment" SG_ 998 BU_NetCfg_RBSS "Backup for network ECU config data for interior";
BA_ "FlexKomIsMotorola" SG_ 998 BU_NetCfg_RBSS 1;
BA_ "GenSigSNA" SG_ 998 BU_NetCfg_RBSS "0h";
BA_ "GenSigSendType" SG_ 998 BU_NetCfg_BSM 1;
BA_ "FlexKomSigStartValue" SG_ 998 BU_NetCfg_BSM "0300000000000000h";
BA_ "FlexKomSID" SG_ 998 BU_NetCfg_BSM 871;
BA_ "FlexKomSigStartPos" SG_ 998 BU_NetCfg_BSM 7;
BA_ "FlexKomSigLaenge" SG_ 998 BU_NetCfg_BSM 64;
BA_ "FlexKomSigName" SG_ 998 BU_NetCfg_BSM "BU_NET_CFG_DATA_INT";
BA_ "FlexKomComment" SG_ 998 BU_NetCfg_BSM "Backup for network ECU config data for interior";
BA_ "FlexKomIsMotorola" SG_ 998 BU_NetCfg_BSM 1;
BA_ "GenSigSNA" SG_ 998 BU_NetCfg_BSM "0h";
BA_ "GenSigSendType" SG_ 998 BU_NetCfg_CBC_IN 1;
BA_ "FlexKomSigStartValue" SG_ 998 BU_NetCfg_CBC_IN "0300000000000000h";
BA_ "FlexKomSID" SG_ 998 BU_NetCfg_CBC_IN 871;
BA_ "FlexKomSigStartPos" SG_ 998 BU_NetCfg_CBC_IN 7;
BA_ "FlexKomSigLaenge" SG_ 998 BU_NetCfg_CBC_IN 64;
BA_ "FlexKomSigName" SG_ 998 BU_NetCfg_CBC_IN "BU_NET_CFG_DATA_INT";
BA_ "FlexKomComment" SG_ 998 BU_NetCfg_CBC_IN "Backup for network ECU config data for interior";
BA_ "FlexKomIsMotorola" SG_ 998 BU_NetCfg_CBC_IN 1;
BA_ "GenSigSNA" SG_ 998 BU_NetCfg_CBC_IN "0h";
BA_ "GenSigSendType" SG_ 998 BU_NetCfg_CSWM 1;
BA_ "FlexKomSigStartValue" SG_ 998 BU_NetCfg_CSWM "0300000000000000h";
BA_ "FlexKomSID" SG_ 998 BU_NetCfg_CSWM 871;
BA_ "FlexKomSigStartPos" SG_ 998 BU_NetCfg_CSWM 7;
BA_ "FlexKomSigLaenge" SG_ 998 BU_NetCfg_CSWM 64;
BA_ "FlexKomSigName" SG_ 998 BU_NetCfg_CSWM "BU_NET_CFG_DATA_INT";
BA_ "FlexKomComment" SG_ 998 BU_NetCfg_CSWM "Backup for network ECU config data for interior";
BA_ "FlexKomIsMotorola" SG_ 998 BU_NetCfg_CSWM 1;
BA_ "GenSigSNA" SG_ 998 BU_NetCfg_CSWM "0h";
BA_ "GenSigSendType" SG_ 998 BU_NetCfg_DCM_DR 1;
BA_ "FlexKomSigStartValue" SG_ 998 BU_NetCfg_DCM_DR "0300000000000000h";
BA_ "FlexKomSID" SG_ 998 BU_NetCfg_DCM_DR 871;
BA_ "FlexKomSigStartPos" SG_ 998 BU_NetCfg_DCM_DR 7;
BA_ "FlexKomSigLaenge" SG_ 998 BU_NetCfg_DCM_DR 64;
BA_ "FlexKomSigName" SG_ 998 BU_NetCfg_DCM_DR "BU_NET_CFG_DATA_INT";
BA_ "FlexKomComment" SG_ 998 BU_NetCfg_DCM_DR "Backup for network ECU config data for interior";
BA_ "FlexKomIsMotorola" SG_ 998 BU_NetCfg_DCM_DR 1;
BA_ "GenSigSNA" SG_ 998 BU_NetCfg_DCM_DR "0h";
BA_ "GenSigSendType" SG_ 998 BU_NetCfg_DCM_PASS 1;
BA_ "FlexKomSigStartValue" SG_ 998 BU_NetCfg_DCM_PASS "0300000000000000h";
BA_ "FlexKomSID" SG_ 998 BU_NetCfg_DCM_PASS 871;
BA_ "FlexKomSigStartPos" SG_ 998 BU_NetCfg_DCM_PASS 7;
BA_ "FlexKomSigLaenge" SG_ 998 BU_NetCfg_DCM_PASS 64;
BA_ "FlexKomSigName" SG_ 998 BU_NetCfg_DCM_PASS "BU_NET_CFG_DATA_INT";
BA_ "FlexKomComment" SG_ 998 BU_NetCfg_DCM_PASS "Backup for network ECU config data for interior";
BA_ "FlexKomIsMotorola" SG_ 998 BU_NetCfg_DCM_PASS 1;
BA_ "GenSigSNA" SG_ 998 BU_NetCfg_DCM_PASS "0h";
BA_ "GenSigSendType" SG_ 998 BU_NetCfg_DCM_RL 1;
BA_ "FlexKomSigStartValue" SG_ 998 BU_NetCfg_DCM_RL "0300000000000000h";
BA_ "FlexKomSID" SG_ 998 BU_NetCfg_DCM_RL 871;
BA_ "FlexKomSigStartPos" SG_ 998 BU_NetCfg_DCM_RL 7;
BA_ "FlexKomSigLaenge" SG_ 998 BU_NetCfg_DCM_RL 64;
BA_ "FlexKomSigName" SG_ 998 BU_NetCfg_DCM_RL "BU_NET_CFG_DATA_INT";
BA_ "FlexKomComment" SG_ 998 BU_NetCfg_DCM_RL "Backup for network ECU config data for interior";
BA_ "FlexKomIsMotorola" SG_ 998 BU_NetCfg_DCM_RL 1;
BA_ "GenSigSNA" SG_ 998 BU_NetCfg_DCM_RL "0h";
BA_ "GenSigSendType" SG_ 998 BU_NetCfg_DCM_RR 1;
BA_ "FlexKomSigStartValue" SG_ 998 BU_NetCfg_DCM_RR "0300000000000000h";
BA_ "FlexKomSID" SG_ 998 BU_NetCfg_DCM_RR 871;
BA_ "FlexKomSigStartPos" SG_ 998 BU_NetCfg_DCM_RR 7;
BA_ "FlexKomSigLaenge" SG_ 998 BU_NetCfg_DCM_RR 64;
BA_ "FlexKomSigName" SG_ 998 BU_NetCfg_DCM_RR "BU_NET_CFG_DATA_INT";
BA_ "FlexKomComment" SG_ 998 BU_NetCfg_DCM_RR "Backup for network ECU config data for interior";
BA_ "FlexKomIsMotorola" SG_ 998 BU_NetCfg_DCM_RR 1;
BA_ "GenSigSNA" SG_ 998 BU_NetCfg_DCM_RR "0h";
BA_ "GenSigSendType" SG_ 998 BU_NetCfg_HVAC 1;
BA_ "FlexKomSigStartValue" SG_ 998 BU_NetCfg_HVAC "0300000000000000h";
BA_ "FlexKomSID" SG_ 998 BU_NetCfg_HVAC 871;
BA_ "FlexKomSigStartPos" SG_ 998 BU_NetCfg_HVAC 7;
BA_ "FlexKomSigLaenge" SG_ 998 BU_NetCfg_HVAC 64;
BA_ "FlexKomSigName" SG_ 998 BU_NetCfg_HVAC "BU_NET_CFG_DATA_INT";
BA_ "FlexKomComment" SG_ 998 BU_NetCfg_HVAC "Backup for network ECU config data for interior";
BA_ "FlexKomIsMotorola" SG_ 998 BU_NetCfg_HVAC 1;
BA_ "GenSigSNA" SG_ 998 BU_NetCfg_HVAC "0h";
BA_ "GenSigSendType" SG_ 998 BU_NetCfg_MSM 1;
BA_ "FlexKomSigStartValue" SG_ 998 BU_NetCfg_MSM "0300000000000000h";
BA_ "FlexKomSID" SG_ 998 BU_NetCfg_MSM 871;
BA_ "FlexKomSigStartPos" SG_ 998 BU_NetCfg_MSM 7;
BA_ "FlexKomSigLaenge" SG_ 998 BU_NetCfg_MSM 64;
BA_ "FlexKomSigName" SG_ 998 BU_NetCfg_MSM "BU_NET_CFG_DATA_INT";
BA_ "FlexKomComment" SG_ 998 BU_NetCfg_MSM "Backup for network ECU config data for interior";
BA_ "FlexKomIsMotorola" SG_ 998 BU_NetCfg_MSM 1;
BA_ "GenSigSNA" SG_ 998 BU_NetCfg_MSM "0h";
BA_ "GenSigSendType" SG_ 998 BU_NetCfg_PLG 1;
BA_ "FlexKomSigStartValue" SG_ 998 BU_NetCfg_PLG "0300000000000000h";
BA_ "FlexKomSID" SG_ 998 BU_NetCfg_PLG 871;
BA_ "FlexKomSigStartPos" SG_ 998 BU_NetCfg_PLG 7;
BA_ "FlexKomSigLaenge" SG_ 998 BU_NetCfg_PLG 64;
BA_ "FlexKomSigName" SG_ 998 BU_NetCfg_PLG "BU_NET_CFG_DATA_INT";
BA_ "FlexKomComment" SG_ 998 BU_NetCfg_PLG "Backup for network ECU config data for interior";
BA_ "FlexKomIsMotorola" SG_ 998 BU_NetCfg_PLG 1;
BA_ "GenSigSNA" SG_ 998 BU_NetCfg_PLG "0h";
BA_ "GenSigSendType" SG_ 998 BU_NetCfg_VTM 1;
BA_ "FlexKomSigStartValue" SG_ 998 BU_NetCfg_VTM "0300000000000000h";
BA_ "FlexKomSID" SG_ 998 BU_NetCfg_VTM 871;
BA_ "FlexKomSigStartPos" SG_ 998 BU_NetCfg_VTM 7;
BA_ "FlexKomSigLaenge" SG_ 998 BU_NetCfg_VTM 64;
BA_ "FlexKomSigName" SG_ 998 BU_NetCfg_VTM "BU_NET_CFG_DATA_INT";
BA_ "FlexKomComment" SG_ 998 BU_NetCfg_VTM "Backup for network ECU config data for interior";
BA_ "FlexKomIsMotorola" SG_ 998 BU_NetCfg_VTM 1;
BA_ "GenSigSNA" SG_ 998 BU_NetCfg_VTM "0h";
BA_ "GenSigSendType" SG_ 998 BU_NetCfg_PSD_LT 1;
BA_ "FlexKomSigStartValue" SG_ 998 BU_NetCfg_PSD_LT "0300000000000000h";
BA_ "FlexKomSID" SG_ 998 BU_NetCfg_PSD_LT 871;
BA_ "FlexKomSigStartPos" SG_ 998 BU_NetCfg_PSD_LT 7;
BA_ "FlexKomSigLaenge" SG_ 998 BU_NetCfg_PSD_LT 64;
BA_ "FlexKomSigName" SG_ 998 BU_NetCfg_PSD_LT "BU_NET_CFG_DATA_INT";
BA_ "FlexKomComment" SG_ 998 BU_NetCfg_PSD_LT "Backup for network ECU config data for interior";
BA_ "FlexKomIsMotorola" SG_ 998 BU_NetCfg_PSD_LT 1;
BA_ "GenSigSNA" SG_ 998 BU_NetCfg_PSD_LT "0h";
BA_ "GenSigSendType" SG_ 998 BU_NetCfg_PSD_RT 1;
BA_ "FlexKomSigStartValue" SG_ 998 BU_NetCfg_PSD_RT "0300000000000000h";
BA_ "FlexKomSID" SG_ 998 BU_NetCfg_PSD_RT 871;
BA_ "FlexKomSigStartPos" SG_ 998 BU_NetCfg_PSD_RT 7;
BA_ "FlexKomSigLaenge" SG_ 998 BU_NetCfg_PSD_RT 64;
BA_ "FlexKomSigName" SG_ 998 BU_NetCfg_PSD_RT "BU_NET_CFG_DATA_INT";
BA_ "FlexKomComment" SG_ 998 BU_NetCfg_PSD_RT "Backup for network ECU config data for interior";
BA_ "FlexKomIsMotorola" SG_ 998 BU_NetCfg_PSD_RT 1;
BA_ "GenSigSNA" SG_ 998 BU_NetCfg_PSD_RT "0h";
BA_ "GenSigSendType" SG_ 998 BU_NetCfg_FSM 1;
BA_ "FlexKomSigStartValue" SG_ 998 BU_NetCfg_FSM "0300000000000000h";
BA_ "FlexKomSID" SG_ 998 BU_NetCfg_FSM 871;
BA_ "FlexKomSigStartPos" SG_ 998 BU_NetCfg_FSM 7;
BA_ "FlexKomSigLaenge" SG_ 998 BU_NetCfg_FSM 64;
BA_ "FlexKomSigName" SG_ 998 BU_NetCfg_FSM "BU_NET_CFG_DATA_INT";
BA_ "FlexKomComment" SG_ 998 BU_NetCfg_FSM "Backup for network ECU config data for interior";
BA_ "FlexKomIsMotorola" SG_ 998 BU_NetCfg_FSM 1;
BA_ "GenSigSNA" SG_ 998 BU_NetCfg_FSM "0h";
BA_ "GenSigSendType" SG_ 998 BU_NetCfg_PTCM 1;
BA_ "FlexKomSigStartValue" SG_ 998 BU_NetCfg_PTCM "0300000000000000h";
BA_ "FlexKomSID" SG_ 998 BU_NetCfg_PTCM 871;
BA_ "FlexKomSigStartPos" SG_ 998 BU_NetCfg_PTCM 7;
BA_ "FlexKomSigLaenge" SG_ 998 BU_NetCfg_PTCM 64;
BA_ "FlexKomSigName" SG_ 998 BU_NetCfg_PTCM "BU_NET_CFG_DATA_INT";
BA_ "FlexKomComment" SG_ 998 BU_NetCfg_PTCM "Backup for network ECU config data for interior";
BA_ "FlexKomIsMotorola" SG_ 998 BU_NetCfg_PTCM 1;
BA_ "GenSigSNA" SG_ 998 BU_NetCfg_PTCM "0h";
BA_ "GenSigSendType" SG_ 998 BU_NetCfg_RBC 1;
BA_ "FlexKomSigStartValue" SG_ 998 BU_NetCfg_RBC "0300000000000000h";
BA_ "FlexKomSID" SG_ 998 BU_NetCfg_RBC 871;
BA_ "FlexKomSigStartPos" SG_ 998 BU_NetCfg_RBC 7;
BA_ "FlexKomSigLaenge" SG_ 998 BU_NetCfg_RBC 64;
BA_ "FlexKomSigName" SG_ 998 BU_NetCfg_RBC "BU_NET_CFG_DATA_INT";
BA_ "FlexKomComment" SG_ 998 BU_NetCfg_RBC "Backup for network ECU config data for interior";
BA_ "FlexKomIsMotorola" SG_ 998 BU_NetCfg_RBC 1;
BA_ "GenSigSNA" SG_ 998 BU_NetCfg_RBC "0h";
BA_ "GenSigSendType" SG_ 998 BU_NetCfg_DTV 1;
BA_ "FlexKomSigStartValue" SG_ 998 BU_NetCfg_DTV "0300000000000000h";
BA_ "FlexKomSID" SG_ 998 BU_NetCfg_DTV 871;
BA_ "FlexKomSigStartPos" SG_ 998 BU_NetCfg_DTV 7;
BA_ "FlexKomSigLaenge" SG_ 998 BU_NetCfg_DTV 64;
BA_ "FlexKomSigName" SG_ 998 BU_NetCfg_DTV "BU_NET_CFG_DATA_INT";
BA_ "FlexKomComment" SG_ 998 BU_NetCfg_DTV "Backup for network ECU config data for interior";
BA_ "FlexKomIsMotorola" SG_ 998 BU_NetCfg_DTV 1;
BA_ "GenSigSNA" SG_ 998 BU_NetCfg_DTV "0h";
BA_ "GenSigSendType" SG_ 998 BU_NetCfg_TGW 1;
BA_ "FlexKomSigStartValue" SG_ 998 BU_NetCfg_TGW "0300000000000000h";
BA_ "FlexKomSID" SG_ 998 BU_NetCfg_TGW 871;
BA_ "FlexKomSigStartPos" SG_ 998 BU_NetCfg_TGW 7;
BA_ "FlexKomSigLaenge" SG_ 998 BU_NetCfg_TGW 64;
BA_ "FlexKomSigName" SG_ 998 BU_NetCfg_TGW "BU_NET_CFG_DATA_INT";
BA_ "FlexKomComment" SG_ 998 BU_NetCfg_TGW "Backup for network ECU config data for interior";
BA_ "FlexKomIsMotorola" SG_ 998 BU_NetCfg_TGW 1;
BA_ "GenSigSNA" SG_ 998 BU_NetCfg_TGW "0h";
BA_ "GenSigSendType" SG_ 998 BU_NetCfg_CLOCK 1;
BA_ "FlexKomSigStartValue" SG_ 998 BU_NetCfg_CLOCK "0300000000000000h";
BA_ "FlexKomSID" SG_ 998 BU_NetCfg_CLOCK 871;
BA_ "FlexKomSigStartPos" SG_ 998 BU_NetCfg_CLOCK 7;
BA_ "FlexKomSigLaenge" SG_ 998 BU_NetCfg_CLOCK 64;
BA_ "FlexKomSigName" SG_ 998 BU_NetCfg_CLOCK "BU_NET_CFG_DATA_INT";
BA_ "FlexKomComment" SG_ 998 BU_NetCfg_CLOCK "Backup for network ECU config data for interior";
BA_ "FlexKomIsMotorola" SG_ 998 BU_NetCfg_CLOCK 1;
BA_ "GenSigSNA" SG_ 998 BU_NetCfg_CLOCK "0h";
BA_ "GenSigSendType" SG_ 998 BU_NetCfg_VSIM 1;
BA_ "FlexKomSigStartValue" SG_ 998 BU_NetCfg_VSIM "0300000000000000h";
BA_ "FlexKomSID" SG_ 998 BU_NetCfg_VSIM 871;
BA_ "FlexKomSigStartPos" SG_ 998 BU_NetCfg_VSIM 7;
BA_ "FlexKomSigLaenge" SG_ 998 BU_NetCfg_VSIM 64;
BA_ "FlexKomSigName" SG_ 998 BU_NetCfg_VSIM "BU_NET_CFG_DATA_INT";
BA_ "FlexKomComment" SG_ 998 BU_NetCfg_VSIM "Backup for network ECU config data for interior";
BA_ "FlexKomIsMotorola" SG_ 998 BU_NetCfg_VSIM 1;
BA_ "GenSigSNA" SG_ 998 BU_NetCfg_VSIM "0h";
BA_ "GenSigSendType" SG_ 998 BU_NetCfg_ITM 1;
BA_ "FlexKomSigStartValue" SG_ 998 BU_NetCfg_ITM "0300000000000000h";
BA_ "FlexKomSID" SG_ 998 BU_NetCfg_ITM 871;
BA_ "FlexKomSigStartPos" SG_ 998 BU_NetCfg_ITM 7;
BA_ "FlexKomSigLaenge" SG_ 998 BU_NetCfg_ITM 64;
BA_ "FlexKomSigName" SG_ 998 BU_NetCfg_ITM "BU_NET_CFG_DATA_INT";
BA_ "FlexKomComment" SG_ 998 BU_NetCfg_ITM "Backup for network ECU config data for interior";
BA_ "FlexKomIsMotorola" SG_ 998 BU_NetCfg_ITM 1;
BA_ "GenSigSNA" SG_ 998 BU_NetCfg_ITM "0h";
BA_ "GenSigSendType" SG_ 998 BU_NetCfg_AMP_I 1;
BA_ "FlexKomSigStartValue" SG_ 998 BU_NetCfg_AMP_I "0300000000000000h";
BA_ "FlexKomSID" SG_ 998 BU_NetCfg_AMP_I 871;
BA_ "FlexKomSigStartPos" SG_ 998 BU_NetCfg_AMP_I 7;
BA_ "FlexKomSigLaenge" SG_ 998 BU_NetCfg_AMP_I 64;
BA_ "FlexKomSigName" SG_ 998 BU_NetCfg_AMP_I "BU_NET_CFG_DATA_INT";
BA_ "FlexKomComment" SG_ 998 BU_NetCfg_AMP_I "Backup for network ECU config data for interior";
BA_ "FlexKomIsMotorola" SG_ 998 BU_NetCfg_AMP_I 1;
BA_ "GenSigSNA" SG_ 998 BU_NetCfg_AMP_I "0h";
BA_ "GenSigSendType" SG_ 998 BU_NetCfg_DVD_CDM 1;
BA_ "FlexKomSigStartValue" SG_ 998 BU_NetCfg_DVD_CDM "0300000000000000h";
BA_ "FlexKomSID" SG_ 998 BU_NetCfg_DVD_CDM 871;
BA_ "FlexKomSigStartPos" SG_ 998 BU_NetCfg_DVD_CDM 7;
BA_ "FlexKomSigLaenge" SG_ 998 BU_NetCfg_DVD_CDM 64;
BA_ "FlexKomSigName" SG_ 998 BU_NetCfg_DVD_CDM "BU_NET_CFG_DATA_INT";
BA_ "FlexKomComment" SG_ 998 BU_NetCfg_DVD_CDM "Backup for network ECU config data for interior";
BA_ "FlexKomIsMotorola" SG_ 998 BU_NetCfg_DVD_CDM 1;
BA_ "GenSigSNA" SG_ 998 BU_NetCfg_DVD_CDM "0h";
BA_ "GenSigSendType" SG_ 998 BU_NetCfg_HFM_CTM 1;
BA_ "FlexKomSigStartValue" SG_ 998 BU_NetCfg_HFM_CTM "0300000000000000h";
BA_ "FlexKomSID" SG_ 998 BU_NetCfg_HFM_CTM 871;
BA_ "FlexKomSigStartPos" SG_ 998 BU_NetCfg_HFM_CTM 7;
BA_ "FlexKomSigLaenge" SG_ 998 BU_NetCfg_HFM_CTM 64;
BA_ "FlexKomSigName" SG_ 998 BU_NetCfg_HFM_CTM "BU_NET_CFG_DATA_INT";
BA_ "FlexKomComment" SG_ 998 BU_NetCfg_HFM_CTM "Backup for network ECU config data for interior";
BA_ "FlexKomIsMotorola" SG_ 998 BU_NetCfg_HFM_CTM 1;
BA_ "GenSigSNA" SG_ 998 BU_NetCfg_HFM_CTM "0h";
BA_ "GenSigSendType" SG_ 998 BU_NetCfg_ICS_I 1;
BA_ "FlexKomSigStartValue" SG_ 998 BU_NetCfg_ICS_I "0300000000000000h";
BA_ "FlexKomSID" SG_ 998 BU_NetCfg_ICS_I 871;
BA_ "FlexKomSigStartPos" SG_ 998 BU_NetCfg_ICS_I 7;
BA_ "FlexKomSigLaenge" SG_ 998 BU_NetCfg_ICS_I 64;
BA_ "FlexKomSigName" SG_ 998 BU_NetCfg_ICS_I "BU_NET_CFG_DATA_INT";
BA_ "FlexKomComment" SG_ 998 BU_NetCfg_ICS_I "Backup for network ECU config data for interior";
BA_ "FlexKomIsMotorola" SG_ 998 BU_NetCfg_ICS_I 1;
BA_ "GenSigSNA" SG_ 998 BU_NetCfg_ICS_I "0h";
BA_ "GenSigSendType" SG_ 998 BU_NetCfg_VES2_I 1;
BA_ "FlexKomSigStartValue" SG_ 998 BU_NetCfg_VES2_I "0300000000000000h";
BA_ "FlexKomSID" SG_ 998 BU_NetCfg_VES2_I 871;
BA_ "FlexKomSigStartPos" SG_ 998 BU_NetCfg_VES2_I 7;
BA_ "FlexKomSigLaenge" SG_ 998 BU_NetCfg_VES2_I 64;
BA_ "FlexKomSigName" SG_ 998 BU_NetCfg_VES2_I "BU_NET_CFG_DATA_INT";
BA_ "FlexKomComment" SG_ 998 BU_NetCfg_VES2_I "Backup for network ECU config data for interior";
BA_ "FlexKomIsMotorola" SG_ 998 BU_NetCfg_VES2_I 1;
BA_ "GenSigSNA" SG_ 998 BU_NetCfg_VES2_I "0h";
BA_ "GenSigSendType" SG_ 998 BU_NetCfg_VES3_I 1;
BA_ "FlexKomSigStartValue" SG_ 998 BU_NetCfg_VES3_I "0300000000000000h";
BA_ "FlexKomSID" SG_ 998 BU_NetCfg_VES3_I 871;
BA_ "FlexKomSigStartPos" SG_ 998 BU_NetCfg_VES3_I 7;
BA_ "FlexKomSigLaenge" SG_ 998 BU_NetCfg_VES3_I 64;
BA_ "FlexKomSigName" SG_ 998 BU_NetCfg_VES3_I "BU_NET_CFG_DATA_INT";
BA_ "FlexKomComment" SG_ 998 BU_NetCfg_VES3_I "Backup for network ECU config data for interior";
BA_ "FlexKomIsMotorola" SG_ 998 BU_NetCfg_VES3_I 1;
BA_ "GenSigSNA" SG_ 998 BU_NetCfg_VES3_I "0h";
BA_ "GenSigSendType" SG_ 998 BU_NetCfg_CRSM 1;
BA_ "FlexKomSigStartValue" SG_ 998 BU_NetCfg_CRSM "0300000000000000h";
BA_ "FlexKomSID" SG_ 998 BU_NetCfg_CRSM 871;
BA_ "FlexKomSigStartPos" SG_ 998 BU_NetCfg_CRSM 7;
BA_ "FlexKomSigLaenge" SG_ 998 BU_NetCfg_CRSM 64;
BA_ "FlexKomSigName" SG_ 998 BU_NetCfg_CRSM "BU_NET_CFG_DATA_INT";
BA_ "FlexKomComment" SG_ 998 BU_NetCfg_CRSM "Backup for network ECU config data for interior";
BA_ "FlexKomIsMotorola" SG_ 998 BU_NetCfg_CRSM 1;
BA_ "GenSigSNA" SG_ 998 BU_NetCfg_CRSM "0h";
BA_ "GenSigSendType" SG_ 998 BU_NetCfg_HVAC_R 1;
BA_ "FlexKomSigStartValue" SG_ 998 BU_NetCfg_HVAC_R "0300000000000000h";
BA_ "FlexKomSID" SG_ 998 BU_NetCfg_HVAC_R 871;
BA_ "FlexKomSigStartPos" SG_ 998 BU_NetCfg_HVAC_R 7;
BA_ "FlexKomSigLaenge" SG_ 998 BU_NetCfg_HVAC_R 64;
BA_ "FlexKomSigName" SG_ 998 BU_NetCfg_HVAC_R "BU_NET_CFG_DATA_INT";
BA_ "FlexKomComment" SG_ 998 BU_NetCfg_HVAC_R "Backup for network ECU config data for interior";
BA_ "FlexKomIsMotorola" SG_ 998 BU_NetCfg_HVAC_R 1;
BA_ "GenSigSNA" SG_ 998 BU_NetCfg_HVAC_R "0h";
VAL_ 974 FT_HVAC_BLW_FN_SP 127 "SNA" ;
VAL_ 974 FT_HVAC_MD_STAT 15 "SNA" 8 "PNL_MD" 7 "PNL_BI_LVL_MID_MD" 6 "BI_LVL_MD" 5 "BI_LVL_FLR_MID_MD" 4 "FLR_MD" 3 "FLR_MIX_MID_MD" 2 "MIX_MD" 1 "MIX_DEFR_MID_MD" 0 "DEFR_MD" ;
VAL_ 974 FT_HVAC_CTRL_STAT 7 "SNA" 4 "BLW_MAN_MD_MAN" 3 "BLW_MAN_MD_AUTO" 2 "BLW_AUTO_MD_MAN" 1 "BLW_AUTO_MD_AUTO" 0 "HVAC_CTRL_OFF" ;
VAL_ 974 DRV_TEMP_DR_POS 127 "SNA" ;
VAL_ 974 PAS_TEMP_DR_POS 127 "SNA" ;
VAL_ 974 R_TEMP_DR_POS 127 "SNA" ;
VAL_ 975 SRT_CTRL3 15 "SNA" 13 "LAST2_US" 12 "BEST2_US" 11 "CURRENT2_US" 10 "LAST2_M" 9 "BEST2_M" 8 "CURRENT2_M" 5 "LAST_US" 4 "BEST_US" 3 "CURRENT_US" 2 "LAST_M" 1 "BEST_M" 0 "CURRENT_M" ;
VAL_ 975 SRT_60mphTmC 255 "SNA" 254 "TMR_READY" 253 "TMR_CANCEL" ;
VAL_ 975 SRT_60mphTmB 255 "SNA" 254 "TMR_READY" 253 "TMR_CANCEL" ;
VAL_ 975 SRT_100mphTmL 255 "SNA" 254 "TMR_READY" 253 "TMR_CANCEL" ;
VAL_ 975 SRT_100mphTm_C 255 "SNA" 254 "TMR_READY" 253 "TMR_CANCEL" ;
VAL_ 975 SRT_100mphTm_B 255 "SNA" 254 "TMR_READY" 253 "TMR_CANCEL" ;
VAL_ 975 SRT_100mphTm_L 255 "SNA" 254 "TMR_READY" 253 "TMR_CANCEL" ;
VAL_ 975 SRT_60mphTmL 255 "SNA" 254 "TMR_READY" 253 "TMR_CANCEL" ;
VAL_ 975 SRT_60mphTm_C 255 "SNA" 254 "TMR_READY" 253 "TMR_CANCEL" ;
VAL_ 975 SRT_60mphTm_B 255 "SNA" 254 "TMR_READY" 253 "TMR_CANCEL" ;
VAL_ 975 SRT_60mphTm_L 255 "SNA" 254 "TMR_READY" 253 "TMR_CANCEL" ;
VAL_ 975 SRT_100mphTmC 255 "SNA" 254 "TMR_READY" 253 "TMR_CANCEL" ;
VAL_ 975 SRT_100mphTmB 255 "SNA" 254 "TMR_READY" 253 "TMR_CANCEL" ;
VAL_ 975 SRT_eighthTmC 255 "SNA" 254 "TMR_READY" 253 "TMR_CANCEL" ;
VAL_ 975 SRT_eighthTmB 255 "SNA" 254 "TMR_READY" 253 "TMR_CANCEL" ;
VAL_ 975 SRT_BrkTmL 255 "SNA" 254 "TMR_READY" 253 "TMR_CANCEL" ;
VAL_ 975 SRT_BrkTm_C 255 "SNA" 254 "TMR_READY" 253 "TMR_CANCEL" ;
VAL_ 975 SRT_BrkTm_B 255 "SNA" 254 "TMR_READY" 253 "TMR_CANCEL" ;
VAL_ 975 SRT_BrkTm_L 255 "SNA" 254 "TMR_READY" 253 "TMR_CANCEL" ;
VAL_ 975 SRT_eighthTmL 255 "SNA" 254 "TMR_READY" 253 "TMR_CANCEL" ;
VAL_ 975 SRT_eighthTm_C 255 "SNA" 254 "TMR_READY" 253 "TMR_CANCEL" ;
VAL_ 975 SRT_eighthTm_B 255 "SNA" 254 "TMR_READY" 253 "TMR_CANCEL" ;
VAL_ 975 SRT_eighthTm_L 255 "SNA" 254 "TMR_READY" 253 "TMR_CANCEL" ;
VAL_ 975 SRT_BrkTmC 255 "SNA" 254 "TMR_READY" 253 "TMR_CANCEL" ;
VAL_ 975 SRT_BrkTmB 255 "SNA" 254 "TMR_READY" 253 "TMR_CANCEL" ;
VAL_ 975 SRT_quarterTmC 255 "SNA" 254 "TMR_READY" 253 "TMR_CANCEL" ;
VAL_ 975 SRT_quarterTmB 255 "SNA" 254 "TMR_READY" 253 "TMR_CANCEL" ;
VAL_ 975 SRT_ReactTmL 255 "SNA" 254 "TMR_NU" 253 "OOR" ;
VAL_ 975 SRT_quarterTmL 255 "SNA" 254 "TMR_READY" 253 "TMR_CANCEL" ;
VAL_ 975 SRT_quarterTm_C 255 "SNA" 254 "TMR_READY" 253 "TMR_CANCEL" ;
VAL_ 975 SRT_quarterTm_B 255 "SNA" 254 "TMR_READY" 253 "TMR_CANCEL" ;
VAL_ 975 SRT_quarterTm_L 255 "SNA" 254 "TMR_READY" 253 "TMR_CANCEL" ;
VAL_ 975 SRT_ReactTmC 255 "SNA" 254 "TMR_NU" 253 "OOR" ;
VAL_ 975 SRT_ReactTmB 255 "SNA" 254 "TMR_NU" 253 "OOR" ;
VAL_ 975 SRT_EthSpdC_M 255 "SNA" ;
VAL_ 975 SRT_EthSpdB_M 255 "SNA" ;
VAL_ 975 SRT_EthSpdL_M 255 "SNA" ;
VAL_ 975 SRT_EthSpdC_US 255 "SNA" ;
VAL_ 975 SRT_EthSpdB_US 255 "SNA" ;
VAL_ 975 SRT_EthSpdL_US 255 "SNA" ;
VAL_ 975 SRT_QrtSpdC_M 255 "SNA" ;
VAL_ 975 SRT_QrtSpdB_M 255 "SNA" ;
VAL_ 975 SRT_QrtSpdL_M 255 "SNA" ;
VAL_ 975 SRT_QrtSpdC_US 255 "SNA" ;
VAL_ 975 SRT_QrtSpdB_US 255 "SNA" ;
VAL_ 975 SRT_QrtSpdL_US 255 "SNA" ;
VAL_ 975 SRT_BrkSpdC_M 255 "SNA" ;
VAL_ 975 SRT_BrkSpdB_M 255 "SNA" ;
VAL_ 975 SRT_BrkSpdL_M 255 "SNA" ;
VAL_ 975 SRT_BrkSpdC_US 255 "SNA" ;
VAL_ 975 SRT_BrkSpdB_US 255 "SNA" ;
VAL_ 975 SRT_BrkSpdL_US 255 "SNA" ;
VAL_ 975 SRT_BrkDistC_M 255 "SNA" 254 "T_READY" 253 "T_CANCEL" ;
VAL_ 975 SRT_BrkDistB_M 255 "SNA" 254 "T_READY" 253 "T_CANCEL" ;
VAL_ 975 SRT_BrkDistL_M 255 "SNA" 254 "T_READY" 253 "T_CANCEL" ;
VAL_ 975 SRT_BrkDistC_US 255 "SNA" 254 "T_READY" 253 "T_CANCEL" ;
VAL_ 975 SRT_BrkDistB_US 255 "SNA" 254 "T_READY" 253 "T_CANCEL" ;
VAL_ 975 SRT_BrkDistL_US 255 "SNA" 254 "T_READY" 253 "T_CANCEL" ;
VAL_ 977 TransTyp 255 "SNA" 2 "TRNS2" 1 "TRNS1" 0 "NS" ;
VAL_ 979 EC_ECUCfg14_Stat 3 "SNA" 2 "REQUEST_DATA" 1 "PROGAMMED" 0 "NA" ;
VAL_ 980 EC_ECUCfg13_Stat 3 "SNA" 2 "REQUEST_DATA" 1 "PROGAMMED" 0 "NA" ;
VAL_ 981 EC_ECUCfg12_Stat 3 "SNA" 2 "REQUEST_DATA" 1 "PROGAMMED" 0 "NA" ;
VAL_ 982 EC_ECUCfg11_Stat 3 "SNA" 2 "REQUEST_DATA" 1 "PROGAMMED" 0 "NA" ;
VAL_ 983 EC_ECUCfg10_Stat 3 "SNA" 2 "REQUEST_DATA" 1 "PROGAMMED" 0 "NA" ;
VAL_ 984 EC_ECUCfg9_Stat 3 "SNA" 2 "REQUEST_DATA" 1 "PROGAMMED" 0 "NA" ;
VAL_ 985 EC_BU_ECUCfg14_Stat 3 "SNA" 2 "NA1" 1 "PROGAMMED" 0 "NA" ;
VAL_ 986 EC_BU_ECUCfg13_Stat 3 "SNA" 2 "NA1" 1 "PROGAMMED" 0 "NA" ;
VAL_ 987 EC_BU_ECUCfg12_Stat 3 "SNA" 2 "NA1" 1 "PROGAMMED" 0 "NA" ;
VAL_ 988 EC_BU_ECUCfg11_Stat 3 "SNA" 2 "REQUEST_DATA" 1 "PROGAMMED" 0 "NA" ;
VAL_ 989 EC_BU_ECUCfg10_Stat 3 "SNA" 2 "NA1" 1 "PROGAMMED" 0 "NA" ;
VAL_ 991 EC_BU_ECUCfg9_Stat 3 "SNA" 2 "NA1" 1 "PROGAMMED" 0 "NA" ;
VAL_ 992 VIN_MSG 3 "SNA" 2 "VIN_HI" 1 "VIN_MID" 0 "VIN_LO" ;
VAL_ 993 DISPLACEMENT 255 "SNA" ;
VAL_ 993 NUM_CYL 15 "SNA" ;
VAL_ 993 ENG_ASP 7 "SNA" 3 "SUPER" 2 "TURBO2" 1 "TURBO1" 0 "INTAKE_NORM" ;
VAL_ 993 FUEL_TYPE 7 "SNA" 3 "CNG" 2 "FLEX" 1 "DIESEL" 0 "UNLEADED" ;
VAL_ 993 Manufacture 7 "ENG_NP" 3 "ENG_HY" 2 "ENG_MMC" 1 "ENG_DCS" 0 "ENG_DCA" ;
VAL_ 993 NUM_VALVE 7 "SNA" ;
VAL_ 993 EngStyle 7 "SNA" 5 "CHOICE6" 4 "CHOICE5" 3 "CHOICE4" 2 "CHOICE3" 1 "CHOICE2" 0 "CHOICE1" ;
VAL_ 993 A580_INDEX 31 "SNA" 20 "A580_CalLvl_3_4" 19 "A580_CalLvl_1_2" 18 "A580_SwLvl_3_4" 17 "A580_SwLvl_1_2" 16 "A580_31_32" 15 "A580_29_30" 14 "A580_27_28" 13 "A580_25_26" 12 "A580_23_24" 11 "A580_21_22" 10 "A580_19_20" 9 "A580_17_18" 8 "A580_15_16" 7 "A580_13_14" 6 "A580_11_12" 5 "A580_9_10" 4 "A580_7_8" 3 "A580_5_6" 2 "A580_3_4" 1 "A580_1_2" 0 "A580_CRC" ;
VAL_ 994 NET_CFG_STAT_AT 3 "SNA" 2 "REQUEST_DATA" 1 "PROGAMMED" 0 "NA" ;
VAL_ 995 NET_CFG_STAT_INT 3 "SNA" 2 "REQUEST_DATA" 1 "PROGAMMED" 0 "NA" ;
VAL_ 996 NET_CFG_STAT_PT 3 "SNA" 2 "REQUEST_DATA" 1 "PROGAMMED" 0 "NA" ;
VAL_ 997 BU_NET_CFG_STAT_AT 3 "SNA" 2 "NA1" 1 "PROGAMMED" 0 "NA" ;
VAL_ 998 BU_NET_CFG_STAT_INT 3 "SNA" 2 "NA1" 1 "PROGAMMED" 0 "NA" ;
